VERSION ""

NS_ :

BS_:

BU_: EBOOST_HS CGM_HS BSM_HS HCP_B_HS AVM_HS PFAF_HS LVMPC_HS DCDC_HS TRCM_HS AMP_HS VICM2_HS FICM_HS ARS_HS MCP_B_HS MCP_A_HS ICCM_OBD_HS SAS_HS ACCM_HS VLBS_HS EBCM_OBD_HS HCP_T_HS EDI_HS HPCC_HS VITM_OBD_HS VICM_HS HCP_HS APPS_HS ICCM_HS EOCM_F_HS GPCM_HS VCM_HS HMIM_HS VES_HS Dummy_HS MCP_C_HS ONSTAR_HS EPS_HS TestTool_HS MCP_HS BCP_HS ALC_HS AHL_AFL_HS SADS_HS EPB_HS FCM_HS TCCM_HS RDCM_HS PTO_HS EBCM_HS ACC_HS BCM_HS TCM_HS ECM_HS

BO_ 497 PPEI_Platform_General_Status: 8 BCM_HS
 SG_ ElvtdIdlCstStReq : 33|2@0+ (1,0) [0|3] ""  CGM_HS,ECM_HS
 SG_ FuelFltLfRstRqd : 56|1@0+ (1,0) [0|1] ""  CGM_HS,TCCM_HS,ECM_HS
 SG_ ACCompSysVDA : 9|1@0+ (1,0) [0|1] ""  CGM_HS,HCP_HS,HCP_T_HS,VCM_HS,BCP_HS,ECM_HS
 SG_ BkupPwrModeMstrVDA : 7|1@0+ (1,0) [0|1] ""  EPS_HS,CGM_HS,HCP_T_HS,HCP_HS,HMIM_HS,APPS_HS,EBCM_OBD_HS,EBCM_HS,TCCM_HS,FICM_HS
 SG_ PrkBrkVDA : 35|1@0+ (1,0) [0|1] ""  CGM_HS,RDCM_HS,TCCM_HS
 SG_ PrkBrkVDM : 62|1@0+ (1,0) [0|1] ""  CGM_HS
 SG_ BkupPwrModeMstrVDM : 61|1@0+ (1,0) [0|1] ""  CGM_HS
 SG_ ACCompSysVDM : 60|1@0+ (1,0) [0|1] ""  CGM_HS,VCM_HS
 SG_ AirbgVDA : 57|1@0+ (1,0) [0|1] ""  HCP_B_HS,CGM_HS,HCP_T_HS,HCP_HS,HMIM_HS,ECM_HS,ACC_HS,TCCM_HS,ICCM_OBD_HS,ICCM_HS,BCP_HS
 SG_ SysBkupPwrMdEn : 6|1@0+ (1,0) [0|1] ""  CGM_HS,EBOOST_HS,HCP_B_HS,AVM_HS,PFAF_HS,DCDC_HS,TRCM_HS,FICM_HS,ARS_HS,ICCM_OBD_HS,SAS_HS,VLBS_HS,EBCM_OBD_HS,HCP_T_HS,HCP_HS,ICCM_HS,EOCM_F_HS,VCM_HS,HMIM_HS,VES_HS,MCP_C_HS,EPS_HS,BCP_HS,ALC_HS,AHL_AFL_HS,SADS_HS,FCM_HS,TCCM_HS,RDCM_HS,PTO_HS,EBCM_HS,ACC_HS,TCM_HS,ECM_HS,APPS_HS,EPB_HS
 SG_ SysBkUpPwrMd : 5|2@0+ (1,0) [0|3] ""  CGM_HS,EBOOST_HS,HCP_B_HS,AVM_HS,PFAF_HS,DCDC_HS,TRCM_HS,FICM_HS,ARS_HS,ICCM_OBD_HS,SAS_HS,VLBS_HS,EBCM_OBD_HS,HCP_T_HS,HCP_HS,ICCM_HS,EOCM_F_HS,VCM_HS,HMIM_HS,VES_HS,MCP_C_HS,EPS_HS,BCP_HS,ALC_HS,AHL_AFL_HS,SADS_HS,FCM_HS,TCCM_HS,RDCM_HS,PTO_HS,EBCM_HS,ACC_HS,TCM_HS,ECM_HS,APPS_HS,EPB_HS
 SG_ SysPwrMd : 1|2@0+ (1,0) [0|3] ""  CGM_HS,BSM_HS,VICM2_HS,VICM_HS,EBOOST_HS,HCP_B_HS,AVM_HS,PFAF_HS,DCDC_HS,TRCM_HS,FICM_HS,ARS_HS,ICCM_OBD_HS,SAS_HS,VLBS_HS,HCP_T_HS,HCP_HS,ICCM_HS,EOCM_F_HS,VCM_HS,HMIM_HS,VES_HS,MCP_C_HS,EPS_HS,BCP_HS,ALC_HS,AHL_AFL_HS,SADS_HS,FCM_HS,TCCM_HS,RDCM_HS,PTO_HS,ACC_HS,TCM_HS,ECM_HS,EBCM_OBD_HS,EBCM_HS,APPS_HS,EPB_HS
 SG_ TrStLgMdAtv : 34|1@0+ (1,0) [0|1] ""  EBOOST_HS,BSM_HS,HCP_B_HS,AVM_HS,PFAF_HS,DCDC_HS,TRCM_HS,VICM2_HS,MCP_B_HS,MCP_A_HS,ICCM_OBD_HS,SAS_HS,ACCM_HS,VLBS_HS,VITM_OBD_HS,VICM_HS,ICCM_HS,EOCM_F_HS,VCM_HS,HMIM_HS,VES_HS,MCP_C_HS,EPS_HS,MCP_HS,ALC_HS,AHL_AFL_HS,SADS_HS,EPB_HS,FCM_HS,TCCM_HS,RDCM_HS,PTO_HS,ACC_HS,TCM_HS,ECM_HS,CGM_HS,EBCM_OBD_HS,EBCM_HS
 SG_ DispMeasSys : 59|1@0+ (1,0) [0|1] ""  CGM_HS,TCCM_HS,ACC_HS,ECM_HS
 SG_ ACCmpsrFldOn : 63|1@0+ (1,0) [0|1] ""  CGM_HS,TCCM_HS,ECM_HS
 SG_ ACCompModReq : 12|2@0+ (1,0) [0|3] ""  CGM_HS,HCP_T_HS,HCP_HS,TCCM_HS,ECM_HS
 SG_ ACCompNormLd : 55|8@0+ (0.1,0) [0|25.5] "l/min"  CGM_HS,TCCM_HS,BCP_HS,ECM_HS
 SG_ ACCompNormLdV : 10|1@0+ (1,0) [0|1] ""  CGM_HS,TCCM_HS,BCP_HS,ECM_HS
 SG_ PTORSMstrEngShtReq : 13|1@0+ (1,0) [0|1] ""  CGM_HS,TCCM_HS,PTO_HS,ECM_HS
 SG_ EngOilLfRstRq : 37|1@0+ (1,0) [0|1] ""  CGM_HS,TCCM_HS,ECM_HS
 SG_ SIRDpl : 58|1@0+ (1,0) [0|1] ""  CGM_HS,HCP_T_HS,ICCM_OBD_HS,ICCM_HS,HCP_B_HS,HMIM_HS,HCP_HS,TCCM_HS,BCP_HS,ACC_HS,ECM_HS
 SG_ PTORmStMsEngStRq : 14|1@0+ (1,0) [0|1] ""  CGM_HS,PTO_HS,TCM_HS,TCCM_HS,ECM_HS
 SG_ RmVehStrRq : 15|1@0+ (1,0) [0|1] ""  CGM_HS,HCP_T_HS,BCP_HS,BSM_HS,VICM_HS,HCP_HS,APPS_HS,EPB_HS,TCCM_HS,ECM_HS
 SG_ ThrtlPrgrsnReq : 39|2@0+ (1,0) [0|3] ""  CGM_HS,TCCM_HS,ECM_HS
 SG_ PrkBrkSwAtv : 36|1@0+ (1,0) [0|1] ""  CGM_HS,PTO_HS,ICCM_OBD_HS,ICCM_HS,EOCM_F_HS,RDCM_HS,ACC_HS,EBCM_OBD_HS,EBCM_HS,TCCM_HS,ECM_HS
 SG_ PMMAccTrmSt : 2|1@0+ (1,0) [0|1] ""  CGM_HS,TCM_HS,TCCM_HS,ECM_HS
 SG_ PMMRunCrkTrmSt : 3|1@0+ (1,0) [0|1] ""  CGM_HS,TCM_HS,TCCM_HS,ECM_HS
 SG_ ImmblzrPreRelPswdStat : 8|1@0+ (1,0) [0|1] ""  CGM_HS,HCP_T_HS,HCP_HS,TCCM_HS,ECM_HS
 SG_ ImmblzrPreRelPswrd : 23|16@0+ (1,0) [0|65535] "passwrd"  CGM_HS,HCP_T_HS,HCP_HS,TCCM_HS,ECM_HS

BO_ 969 PPEI_Platform_Immobilizer_Data: 8 BCM_HS
 SG_ ImoInf : 7|64@0+ (1,0) [0|1.84467440737096E+019] ""  HCP_T_HS,HCP_HS,ECM_HS

BO_ 1249 PPEI_VIN_Digits_10_to_17: 8 BCM_HS
 SG_ VehIdNmDig10_17 : 7|64@0+ (1,0) [0|1] ""  HCP_B_HS,CGM_HS,HCP_T_HS,EBCM_OBD_HS,EBCM_HS,VES_HS,EPS_HS,VLBS_HS,BCP_HS,ACC_HS,FICM_HS,EPB_HS,RDCM_HS,TCCM_HS,TCM_HS,ECM_HS

BO_ 2024 USDT_Resp_From_ECM_HS: 8 ECM_HS
 SG_ DgnInf : 7|64@0+ (1,0) [0|1.84467440737096E+019] ""  CGM_HS,ONSTAR_HS,TestTool_HS

BO_ 1512 UUDT_Resp_From_ECM: 8 ECM_HS
 SG_ DgnInf : 7|64@0+ (1,0) [0|1.84467440737096E+019] ""  CGM_HS,ONSTAR_HS,TestTool_HS

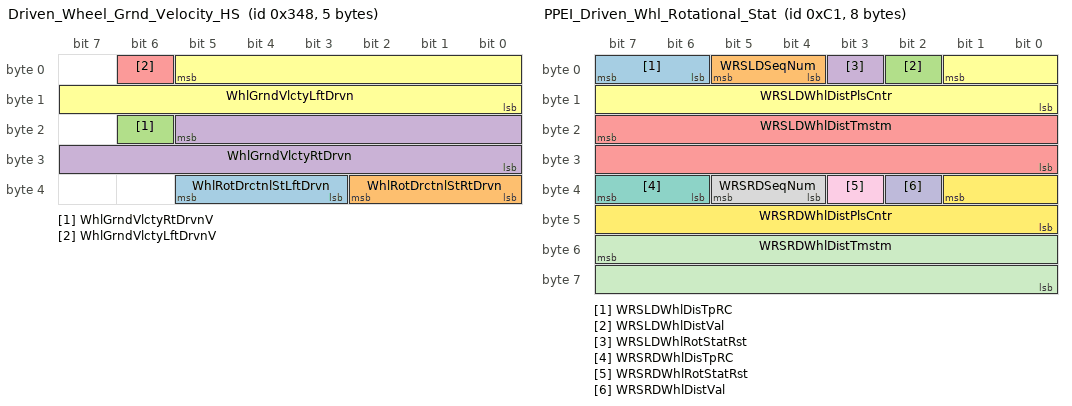
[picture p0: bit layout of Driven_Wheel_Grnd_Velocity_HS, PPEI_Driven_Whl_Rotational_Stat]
BO_ 840 Driven_Wheel_Grnd_Velocity_HS: 5 EBCM_HS
 SG_ WhlRotDrctnlStLftDrvn : 37|3@0+ (1,0) [0|7] ""  CGM_HS,EDI_HS,EOCM_F_HS,HMIM_HS,EPS_HS
 SG_ WhlRotDrctnlStRtDrvn : 34|3@0+ (1,0) [0|7] ""  CGM_HS,EDI_HS,EOCM_F_HS,HMIM_HS,EPS_HS
 SG_ WhlGrndVlctyRtDrvnV : 22|1@0+ (1,0) [0|1] ""  CGM_HS,EDI_HS,HMIM_HS,TCCM_HS,FCM_HS,APPS_HS,EOCM_F_HS,EPB_HS,BCM_HS,RDCM_HS,ACC_HS,VES_HS,EPS_HS,SADS_HS
 SG_ WhlGrndVlctyRtDrvn : 21|14@0+ (0.03125,0) [0|511.96875] "km / h"  CGM_HS,EDI_HS,HMIM_HS,TCCM_HS,FCM_HS,APPS_HS,EOCM_F_HS,BCM_HS,RDCM_HS,ACC_HS,EPB_HS,VES_HS,EPS_HS,SADS_HS
 SG_ WhlGrndVlctyLftDrvnV : 6|1@0+ (1,0) [0|1] ""  CGM_HS,EDI_HS,HMIM_HS,TCCM_HS,FCM_HS,APPS_HS,EOCM_F_HS,EPB_HS,BCM_HS,RDCM_HS,ACC_HS,VES_HS,EPS_HS,SADS_HS
 SG_ WhlGrndVlctyLftDrvn : 5|14@0+ (0.03125,0) [0|511.96875] "km / h"  CGM_HS,EDI_HS,HMIM_HS,TCCM_HS,FCM_HS,APPS_HS,EOCM_F_HS,BCM_HS,RDCM_HS,ACC_HS,EPB_HS,VES_HS,EPS_HS,SADS_HS

BO_ 193 PPEI_Driven_Whl_Rotational_Stat: 8 EBCM_HS
 SG_ WRSLDWhlDisTpRC : 7|2@0+ (1,0) [0|3] "counts"  HCP_B_HS,FCM_HS,HCP_T_HS,FICM_HS,CGM_HS,HCP_HS,ICCM_OBD_HS,ICCM_HS,HMIM_HS,BCP_HS,VES_HS,EPB_HS,EPS_HS,ONSTAR_HS,RDCM_HS,ACC_HS,PTO_HS,BCM_HS,SADS_HS,TCM_HS,TCCM_HS,ECM_HS
 SG_ WRSLDSeqNum : 5|2@0+ (1,0) [0|3] "counts"  HCP_B_HS,FCM_HS,HCP_T_HS,FICM_HS,CGM_HS,HCP_HS,ICCM_OBD_HS,ICCM_HS,HMIM_HS,BCP_HS,VES_HS,EPB_HS,EPS_HS,ONSTAR_HS,RDCM_HS,ACC_HS,PTO_HS,BCM_HS,SADS_HS,TCM_HS,TCCM_HS,ECM_HS
 SG_ WRSLDWhlDistVal : 2|1@0+ (1,0) [0|1] ""  HCP_B_HS,FCM_HS,HCP_T_HS,FICM_HS,CGM_HS,HCP_HS,ICCM_OBD_HS,ICCM_HS,HMIM_HS,BCP_HS,VES_HS,EPB_HS,EPS_HS,ONSTAR_HS,RDCM_HS,ACC_HS,PTO_HS,BCM_HS,SADS_HS,TCM_HS,TCCM_HS,ECM_HS
 SG_ WRSLDWhlRotStatRst : 3|1@0+ (1,0) [0|1] ""  HCP_B_HS,FCM_HS,HCP_T_HS,FICM_HS,CGM_HS,HCP_HS,ICCM_OBD_HS,ICCM_HS,HMIM_HS,BCP_HS,VES_HS,EPB_HS,EPS_HS,ONSTAR_HS,RDCM_HS,ACC_HS,PTO_HS,BCM_HS,SADS_HS,TCM_HS,TCCM_HS,ECM_HS
 SG_ WRSLDWhlDistTmstm : 23|16@0+ (1,0) [0|65535] "counts"  HCP_B_HS,FCM_HS,HCP_T_HS,FICM_HS,CGM_HS,HCP_HS,ICCM_OBD_HS,ICCM_HS,HMIM_HS,BCP_HS,VES_HS,EPB_HS,EPS_HS,ONSTAR_HS,RDCM_HS,ACC_HS,PTO_HS,BCM_HS,SADS_HS,TCM_HS,TCCM_HS,ECM_HS
 SG_ WRSLDWhlDistPlsCntr : 1|10@0+ (1,0) [0|1023] "counts"  HCP_B_HS,FCM_HS,HCP_T_HS,FICM_HS,CGM_HS,HCP_HS,ICCM_OBD_HS,ICCM_HS,HMIM_HS,BCP_HS,VES_HS,EPB_HS,EPS_HS,ONSTAR_HS,RDCM_HS,ACC_HS,PTO_HS,BCM_HS,SADS_HS,TCM_HS,TCCM_HS,ECM_HS
 SG_ WRSRDWhlDisTpRC : 39|2@0+ (1,0) [0|3] "counts"  HCP_B_HS,FCM_HS,HCP_T_HS,FICM_HS,CGM_HS,HCP_HS,ICCM_OBD_HS,ICCM_HS,HMIM_HS,BCP_HS,VES_HS,EPS_HS,ONSTAR_HS,RDCM_HS,ACC_HS,EPB_HS,PTO_HS,BCM_HS,SADS_HS,TCM_HS,TCCM_HS,ECM_HS
 SG_ WRSRDSeqNum : 37|2@0+ (1,0) [0|3] "counts"  HCP_B_HS,FCM_HS,HCP_T_HS,FICM_HS,CGM_HS,HCP_HS,ICCM_OBD_HS,ICCM_HS,HMIM_HS,BCP_HS,VES_HS,EPS_HS,ONSTAR_HS,RDCM_HS,ACC_HS,EPB_HS,PTO_HS,BCM_HS,SADS_HS,TCM_HS,TCCM_HS,ECM_HS
 SG_ WRSRDWhlRotStatRst : 35|1@0+ (1,0) [0|1] ""  HCP_B_HS,FCM_HS,HCP_T_HS,FICM_HS,CGM_HS,HCP_HS,ICCM_OBD_HS,ICCM_HS,HMIM_HS,BCP_HS,VES_HS,EPS_HS,ONSTAR_HS,RDCM_HS,ACC_HS,EPB_HS,PTO_HS,BCM_HS,SADS_HS,TCM_HS,TCCM_HS,ECM_HS
 SG_ WRSRDWhlDistVal : 34|1@0+ (1,0) [0|1] ""  HCP_B_HS,FCM_HS,HCP_T_HS,FICM_HS,CGM_HS,HCP_HS,ICCM_OBD_HS,ICCM_HS,HMIM_HS,BCP_HS,VES_HS,EPS_HS,ONSTAR_HS,RDCM_HS,ACC_HS,EPB_HS,PTO_HS,BCM_HS,SADS_HS,TCM_HS,TCCM_HS,ECM_HS
 SG_ WRSRDWhlDistTmstm : 55|16@0+ (1,0) [0|65535] "counts"  HCP_B_HS,FCM_HS,HCP_T_HS,FICM_HS,CGM_HS,HCP_HS,ICCM_OBD_HS,ICCM_HS,HMIM_HS,BCP_HS,VES_HS,EPS_HS,ONSTAR_HS,RDCM_HS,ACC_HS,EPB_HS,PTO_HS,BCM_HS,SADS_HS,TCM_HS,TCCM_HS,ECM_HS
 SG_ WRSRDWhlDistPlsCntr : 33|10@0+ (1,0) [0|1023] "counts"  HCP_B_HS,FCM_HS,HCP_T_HS,FICM_HS,CGM_HS,HCP_HS,ICCM_OBD_HS,ICCM_HS,HMIM_HS,BCP_HS,VES_HS,EPS_HS,ONSTAR_HS,RDCM_HS,ACC_HS,EPB_HS,PTO_HS,BCM_HS,SADS_HS,TCM_HS,TCCM_HS,ECM_HS

BO_ 481 PPEI_Cruise_Control_Sw_Status: 7 BCM_HS
 SG_ CrsSecSwStatPVal : 51|4@0+ (1,0) [0|15] ""  CGM_HS,ECM_HS,EOCM_F_HS,ACC_HS,PTO_HS
 SG_ CrsSecSwStatARC : 41|2@0+ (1,0) [0|3] ""  CGM_HS,ECM_HS,EOCM_F_HS,ACC_HS,PTO_HS
 SG_ CrsSecSwStat : 27|4@0+ (1,0) [0|15] ""  CGM_HS,ECM_HS,EOCM_F_HS,ACC_HS,PTO_HS
 SG_ DrvSelMdSw3Sta : 37|1@0+ (1,0) [0|1] ""  CGM_HS,ECM_HS
 SG_ DrvSelMdSw2Sta : 38|1@0+ (1,0) [0|1] ""  CGM_HS,ECM_HS
 SG_ AuxHtrRq : 31|1@0+ (1,0) [0|1] ""  CGM_HS,ECM_HS
 SG_ AuxHtrAtv : 30|1@0+ (1,0) [0|1] ""  CGM_HS,ECM_HS
 SG_ DrvSelMdSwStaARC : 33|2@0+ (1,0) [0|3] ""  CGM_HS,ECM_HS
 SG_ DrvSelMdSw1Sta : 39|1@0+ (1,0) [0|1] ""  CGM_HS,ECM_HS
 SG_ CrsSpdLmtrSwStatPVal : 55|4@0+ (1,0) [0|15] ""  CGM_HS,PTO_HS,EOCM_F_HS,ECM_HS,ACC_HS
 SG_ CrsSpdLmtrSwStatARC : 43|2@0+ (1,0) [0|3] ""  CGM_HS,PTO_HS,EOCM_F_HS,ECM_HS,ACC_HS
 SG_ FuelMdSwActV : 29|1@0+ (1,0) [0|1] ""  CGM_HS,FICM_HS,ECM_HS
 SG_ FuelMdSwAct : 28|1@0+ (1,0) [0|1] ""  CGM_HS,FICM_HS,ECM_HS
 SG_ CrsSpdLmtrSwStat : 47|4@0+ (1,0) [0|15] ""  CGM_HS,PTO_HS,EOCM_F_HS,ECM_HS,ACC_HS
 SG_ AdptCrsGapSwAct : 23|2@0+ (1,0) [0|3] ""  CGM_HS,EOCM_F_HS,ACC_HS
 SG_ CrsCntrlSwStCanSwAct : 7|1@0+ (1,0) [0|1] ""  CGM_HS,EOCM_F_HS,ACC_HS,ECM_HS
 SG_ CrsCntrlSwStSwDataIntgty : 1|2@0+ (1,0) [0|3] ""  CGM_HS,EOCM_F_HS,ACC_HS,ECM_HS
 SG_ CrsCntrlSwStSpdInSwAct : 3|1@0+ (1,0) [0|1] ""  CGM_HS,EOCM_F_HS,ACC_HS,ECM_HS
 SG_ CrsCntrlSwStSpDcSwAct : 2|1@0+ (1,0) [0|1] ""  CGM_HS,EOCM_F_HS,ACC_HS,ECM_HS
 SG_ CrsCntrlSwStSetSwAct : 4|1@0+ (1,0) [0|1] ""  CGM_HS,EOCM_F_HS,ACC_HS,ECM_HS
 SG_ CrsCntrlSwStResSwAct : 5|1@0+ (1,0) [0|1] ""  CGM_HS,EOCM_F_HS,ACC_HS,ECM_HS
 SG_ CrsCntrlSwStOnSwAct : 6|1@0+ (1,0) [0|1] ""  CGM_HS,EOCM_F_HS,ACC_HS,ECM_HS
 SG_ CrsCntrlSwStatProtValue : 15|8@0+ (1,0) [0|255] ""  CGM_HS,EOCM_F_HS,ACC_HS,ECM_HS
 SG_ CrsCntrlSwStAlvRollCnt : 17|2@0+ (1,0) [0|3] ""  CGM_HS,EOCM_F_HS,ACC_HS,ECM_HS
 SG_ CrsCntCncRq : 18|1@0+ (1,0) [0|1] ""  CGM_HS,ECM_HS

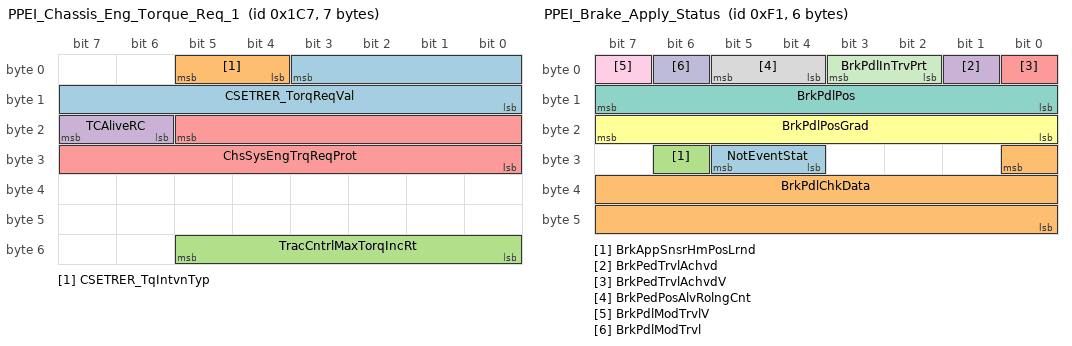
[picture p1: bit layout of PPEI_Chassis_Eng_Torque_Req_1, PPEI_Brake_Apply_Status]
BO_ 455 PPEI_Chassis_Eng_Torque_Req_1: 7 EBCM_HS
 SG_ CSETRER_TorqReqVal : 3|12@0+ (0.5,-848) [-848|1199.5] "Nm"  CGM_HS,ICCM_OBD_HS,ICCM_HS,EOCM_F_HS,ACC_HS,ECM_HS
 SG_ CSETRER_TqIntvnTyp : 5|2@0+ (1,0) [0|3] ""  CGM_HS,ICCM_OBD_HS,ICCM_HS,EOCM_F_HS,ACC_HS,ECM_HS
 SG_ TracCntrlMaxTorqIncRt : 53|6@0+ (16,0) [0|1008] "Nm/s"  CGM_HS,ECM_HS
 SG_ TCAliveRC : 23|2@0+ (1,0) [0|3] ""  CGM_HS,ECM_HS
 SG_ ChsSysEngTrqReqProt : 21|14@0+ (1,0) [0|16383] ""  CGM_HS,ECM_HS

BO_ 761 PPEI_Chassis_General_Status_2: 7 EBCM_HS
 SG_ BrkSysHRBkCtrlAvail : 24|1@0+ (1,0) [0|1] ""  CGM_HS,TCM_HS
 SG_ BrkSysHRBkCtrlStat : 26|2@0+ (1,0) [0|3] ""  CGM_HS,TCM_HS
 SG_ BrkSysHSAAval : 27|1@0+ (1,0) [0|1] ""  CGM_HS,TCM_HS
 SG_ BrkSysHSAStat : 30|3@0+ (1,0) [0|7] ""  CGM_HS,TCM_HS
 SG_ HillDscntCtrlStatPVal : 17|2@0+ (1,0) [0|3] ""  CGM_HS,ECM_HS
 SG_ HillDscntCtrlStatARC : 19|2@0+ (1,0) [0|3] ""  CGM_HS,ECM_HS
 SG_ HillDscntCtrlStat : 21|2@0+ (1,0) [0|3] ""  CGM_HS,ECM_HS
 SG_ AutoBrkFeatInhbtPVal : 49|2@0+ (1,0) [0|3] ""  CGM_HS,FCM_HS,ECM_HS
 SG_ AutoBrkFeatInhbtARC : 51|2@0+ (1,0) [0|3] ""  CGM_HS,FCM_HS,ECM_HS
 SG_ ABFI_CollPrepSysInhbt : 52|1@0+ (1,0) [0|1] ""  CGM_HS,FCM_HS,ECM_HS
 SG_ ABFI_RrVirtlBmprInh : 53|1@0+ (1,0) [0|1] ""  CGM_HS,FCM_HS,ECM_HS
 SG_ BrkPdlDrvApplPresV : 12|1@0+ (1,0) [0|1] ""  CGM_HS,ICCM_OBD_HS,ICCM_HS,BCP_HS,FCM_HS,ECM_HS,TCCM_HS,TCM_HS,VES_HS,EPS_HS
 SG_ BrkPdlDrvApplPres : 47|8@0+ (75,0) [0|19125] "kPa"  HCP_B_HS,CGM_HS,ICCM_OBD_HS,ICCM_HS,BCP_HS,FCM_HS,ECM_HS,TCCM_HS,TCM_HS,VES_HS,EPS_HS
 SG_ AutoBrkPTReqStat : 15|3@0+ (1,0) [0|7] ""  CGM_HS,FCM_HS,ECM_HS
 SG_ WhlSpdSnsgDTCIndex : 7|5@0+ (1,0) [0|31] ""  CGM_HS,ECM_HS
 SG_ WhlSpdSnsgDTCStat : 2|3@0+ (1,0) [0|7] ""  CGM_HS,ECM_HS
 SG_ SprTireSt : 10|3@0+ (1,0) [0|7] ""  CGM_HS,ICCM_OBD_HS,ICCM_HS,VES_HS,EPS_HS,BCM_HS,RDCM_HS,TCCM_HS

BO_ 489 PPEI_Chassis_General_Status_1: 8 EBCM_HS
 SG_ EnhDrvMdSwChUseRq : 53|1@0+ (1,0) [0|1] ""  CGM_HS,ECM_HS
 SG_ IMUDataMsk : 25|1@0+ (1,0) [0|1] ""  CGM_HS,ONSTAR_HS
 SG_ DrvIndpntBrkAppAct : 55|1@0+ (1,0) [0|1] ""  CGM_HS,RDCM_HS,TCM_HS,ECM_HS
 SG_ WhlSlpSt : 52|2@0+ (1,0) [0|3] ""  HCP_HS,CGM_HS,HCP_T_HS,ECM_HS,TCM_HS
 SG_ BSTGRReqdGear : 19|4@0+ (1,0) [0|15] ""  CGM_HS,TCM_HS
 SG_ BSTGRReqType : 21|2@0+ (1,0) [0|3] ""  CGM_HS,TCM_HS
 SG_ VehDynOvrUndrStr : 49|10@0- (0.5,0) [-256|255.5] "%"  CGM_HS,EPS_HS,RDCM_HS,TCCM_HS
 SG_ VSELatAccV : 4|1@0+ (1,0) [0|1] ""  CGM_HS,EDI_HS,FCM_HS,EPS_HS,ICCM_OBD_HS,ICCM_HS,ALC_HS,SADS_HS,RDCM_HS,BCM_HS,ACC_HS,EPB_HS,TCM_HS,TCCM_HS,ECM_HS
 SG_ VSELatAcc : 3|12@0- (0.015625,0) [-32|31.984375] "m/s^2"  CGM_HS,EDI_HS,FCM_HS,EPS_HS,ICCM_OBD_HS,ICCM_HS,ALC_HS,SADS_HS,BCM_HS,RDCM_HS,ACC_HS,EPB_HS,TCM_HS,TCCM_HS,ECM_HS
 SG_ VSEAct : 24|1@0+ (1,0) [0|1] ""  CGM_HS,ICCM_OBD_HS,ICCM_HS,EOCM_F_HS,VES_HS,BCM_HS,EPB_HS,RDCM_HS,EPS_HS,ACC_HS,LVMPC_HS,TCCM_HS,ECM_HS
 SG_ VhDynCntlSysSt : 39|3@0+ (1,0) [0|7] ""  CGM_HS,EOCM_F_HS,FCM_HS,HMIM_HS,RDCM_HS,VES_HS,ECM_HS,EPB_HS,EPS_HS,ACC_HS,TCCM_HS
 SG_ VehDynYawRateV : 36|1@0+ (1,0) [0|1] ""  CGM_HS,ICCM_OBD_HS,ICCM_HS,EDI_HS,FCM_HS,HMIM_HS,RDCM_HS,BCM_HS,VES_HS,EPS_HS,ONSTAR_HS,AHL_AFL_HS,ACC_HS,TCCM_HS
 SG_ VehDynYawRate : 35|12@0- (0.0625,0) [-128|127.9375] "deg/sec"  CGM_HS,ICCM_OBD_HS,ICCM_HS,EDI_HS,FCM_HS,HMIM_HS,RDCM_HS,BCM_HS,VES_HS,EPS_HS,AHL_AFL_HS,ONSTAR_HS,ACC_HS,TCCM_HS
 SG_ TrnsBrkSysCltchRelRqd : 5|1@0+ (1,0) [0|1] ""  CGM_HS,TCCM_HS,TCM_HS
 SG_ TracCntrlSysDrIntnt : 26|1@0+ (1,0) [0|1] ""  CGM_HS,EPS_HS,RDCM_HS,ECM_HS
 SG_ VehDynOvrUndrStrV : 50|1@0+ (1,0) [0|1] ""  CGM_HS,EPS_HS,RDCM_HS,TCCM_HS
 SG_ TCSysEnbld : 27|1@0+ (1,0) [0|1] ""  CGM_HS,EOCM_F_HS,ACC_HS,BCP_HS,VES_HS,EPS_HS,RDCM_HS,TCM_HS,ECM_HS
 SG_ TCSysAtv : 28|1@0+ (1,0) [0|1] ""  CGM_HS,LVMPC_HS,EDI_HS,PTO_HS,TCCM_HS,EOCM_F_HS,VES_HS,RDCM_HS,EPB_HS,EPS_HS,ACC_HS,BCM_HS,TCM_HS,ECM_HS
 SG_ BrkPdlDrvAppPrsDetcdV : 7|1@0+ (1,0) [0|1] ""  CGM_HS,EOCM_F_HS,ACC_HS,VES_HS,EPS_HS,RDCM_HS,TCM_HS,TCCM_HS,ECM_HS
 SG_ BrkPdlDrvAppPrsDetcd : 6|1@0+ (1,0) [0|1] ""  CGM_HS,EOCM_F_HS,ACC_HS,VES_HS,EPS_HS,RDCM_HS,TCM_HS,TCCM_HS,ECM_HS
 SG_ ACCBrkngAct : 31|1@0+ (1,0) [0|1] ""  CGM_HS,EOCM_F_HS,ACC_HS,TCM_HS,ECM_HS
 SG_ ABSFld : 29|1@0+ (1,0) [0|1] ""  CGM_HS,FCM_HS,EOCM_F_HS,ACC_HS,ICCM_OBD_HS,ICCM_HS,VES_HS,EPS_HS,EPB_HS,TCM_HS,ECM_HS
 SG_ ABSAtv : 30|1@0+ (1,0) [0|1] ""  CGM_HS,LVMPC_HS,EDI_HS,ICCM_OBD_HS,ICCM_HS,EOCM_F_HS,APPS_HS,SADS_HS,VES_HS,RDCM_HS,EPB_HS,EPS_HS,ACC_HS,BCM_HS,TCM_HS,TCCM_HS,ECM_HS

BO_ 381 Antilock_Brake_and_TC_Status_HS: 6 EBCM_HS
 SG_ HillDesCtrlRedVehSpIO : 39|1@0+ (1,0) [0|1] ""  CGM_HS,BCM_HS
 SG_ EBDFailed : 23|1@0+ (1,0) [0|1] ""  CGM_HS,BCM_HS
 SG_ StWhAnVDA : 17|1@0+ (1,0) [0|1] ""  CGM_HS,HMIM_HS,RDCM_HS,ONSTAR_HS,ACC_HS,AHL_AFL_HS,EPB_HS,BCM_HS
 SG_ TirePrsLowIO : 9|1@0+ (1,0) [0|1] ""  CGM_HS,BCM_HS
 SG_ VaccBoostFailure : 16|1@0+ (1,0) [0|1] ""  CGM_HS,BCM_HS
 SG_ VSESysPrs : 1|1@0+ (1,0) [0|1] ""  CGM_HS,EPB_HS,BCM_HS
 SG_ HalfSysFail : 18|1@0+ (1,0) [0|1] ""  CGM_HS,BCM_HS
 SG_ ActVehAccel : 35|12@0- (0.01,0) [-20.48|20.47] "m/s^2"  ECM_HS,CGM_HS,BSM_HS,VICM_HS,BCP_HS,BCM_HS,EOCM_F_HS,FCM_HS,ACC_HS,AHL_AFL_HS,EPB_HS
 SG_ ActVehAccelV : 20|1@0+ (1,0) [0|1] ""  ECM_HS,CGM_HS,BSM_HS,VICM_HS,BCP_HS,BCM_HS,EOCM_F_HS,FCM_HS,ACC_HS,AHL_AFL_HS,EPB_HS
 SG_ BksOvht : 8|1@0+ (1,0) [0|1] ""  CGM_HS,EOCM_F_HS,BCM_HS,ACC_HS
 SG_ TCSysPr : 10|1@0+ (1,0) [0|1] ""  CGM_HS,EPB_HS,BCM_HS
 SG_ ABSPr : 22|1@0+ (1,0) [0|1] ""  CGM_HS,BCP_HS,APPS_HS,BCM_HS,EPB_HS
 SG_ TreInfMonSysRstPrfmd : 11|1@0+ (1,0) [0|1] ""  CGM_HS,BCM_HS
 SG_ ABSIO : 12|1@0+ (1,0) [0|1] ""  CGM_HS,FCM_HS,EOCM_F_HS,BCM_HS
 SG_ BrkPadWrnIO : 0|1@0+ (1,0) [0|1] ""  CGM_HS,BCM_HS
 SG_ VehStabEnhmntMd : 15|3@0+ (1,0) [0|7] ""  CGM_HS,EDI_HS,ICCM_OBD_HS,ICCM_HS,SADS_HS,ACC_HS,EOCM_F_HS,TCCM_HS,RDCM_HS,BCM_HS
 SG_ VehStabEnhmntStat : 4|3@0+ (1,0) [0|7] ""  CGM_HS,EPS_HS,EDI_HS,FCM_HS,ONSTAR_HS,ACC_HS,EOCM_F_HS,BCM_HS,EPB_HS
 SG_ TCSysOpMd : 7|3@0+ (1,0) [0|7] ""  CGM_HS,EDI_HS,SADS_HS,EPS_HS,ACC_HS,EOCM_F_HS,TCCM_HS,RDCM_HS,BCM_HS
 SG_ TCSysOpStat : 38|3@0+ (1,0) [0|7] ""  CGM_HS,EDI_HS,SADS_HS,ONSTAR_HS,ACC_HS,EOCM_F_HS,EPB_HS,BCM_HS
 SG_ BrkSysVTopSpdLimVal : 31|8@0+ (2,0) [0|510] "km / h"  CGM_HS,BCM_HS
 SG_ BrkSysRedBrkTlltlReq : 19|1@0+ (1,0) [0|1] ""  CGM_HS,ONSTAR_HS,BCM_HS
 SG_ BrkSysBrkLtsReqd : 21|1@0+ (1,0) [0|1] ""  CGM_HS,AHL_AFL_HS,BCM_HS

BO_ 241 PPEI_Brake_Apply_Status: 6 BCM_HS
 SG_ NotEventStat : 29|2@0+ (1,0) [0|3] ""  CGM_HS,EBCM_OBD_HS,EBCM_HS,ECM_HS,VES_HS,EPS_HS
 SG_ BrkPdlChkData : 24|17@0+ (1,0) [0|131071] ""  FCM_HS,CGM_HS,EOCM_F_HS,ACC_HS
 SG_ BrkAppSnsrHmPosLrnd : 30|1@0+ (1,0) [0|1] ""  CGM_HS,EOCM_F_HS,FCM_HS,ACC_HS,ECM_HS,VES_HS,EPS_HS,EBCM_OBD_HS,EBCM_HS
 SG_ BrkPedTrvlAchvd : 1|1@0+ (1,0) [0|1] ""  HCP_B_HS,CGM_HS,HCP_T_HS,PTO_HS,BSM_HS,VICM_HS,BCP_HS,APPS_HS,VES_HS,EPS_HS,EOCM_F_HS,ICCM_OBD_HS,ICCM_HS,ALC_HS,EPB_HS,ACC_HS,RDCM_HS,SADS_HS,EBCM_OBD_HS,EBCM_HS,TCM_HS,TCCM_HS,ECM_HS
 SG_ BrkPedTrvlAchvdV : 0|1@0+ (1,0) [0|1] ""  HCP_B_HS,CGM_HS,HCP_T_HS,PTO_HS,BSM_HS,VICM_HS,BCP_HS,APPS_HS,VES_HS,EPS_HS,EOCM_F_HS,ICCM_OBD_HS,ICCM_HS,ALC_HS,EPB_HS,ACC_HS,RDCM_HS,SADS_HS,EBCM_OBD_HS,EBCM_HS,TCM_HS,TCCM_HS,ECM_HS
 SG_ BrkPdlPosGrad : 23|8@0- (40,0) [-5120|5080] "%/s"  FCM_HS,CGM_HS,ACC_HS,VES_HS,EPS_HS,EOCM_F_HS,SADS_HS,EBCM_OBD_HS,EBCM_HS
 SG_ BrkPdlPos : 15|8@0+ (0.392157,0) [0|100.000035] "% full"  FCM_HS,ECM_HS,CGM_HS,LVMPC_HS,TCCM_HS,ACC_HS,EOCM_F_HS,TCM_HS,EDI_HS,SADS_HS,VES_HS,EPS_HS,EPB_HS,EBCM_OBD_HS,EBCM_HS
 SG_ BrkPedPosAlvRolngCnt : 5|2@0+ (1,0) [0|3] ""  FCM_HS,CGM_HS,PTO_HS,TCCM_HS,RDCM_HS,VES_HS,EPS_HS,EOCM_F_HS,ICCM_OBD_HS,ICCM_HS,EPB_HS,ACC_HS,EBCM_OBD_HS,EBCM_HS,TCM_HS,ECM_HS
 SG_ BrkPdlModTrvlV : 7|1@0+ (1,0) [0|1] ""  CGM_HS,SADS_HS,EBCM_OBD_HS,EBCM_HS,ACC_HS,EOCM_F_HS,EPB_HS,TCCM_HS,VES_HS,EPS_HS,TCM_HS,ECM_HS
 SG_ BrkPdlModTrvl : 6|1@0+ (1,0) [0|1] ""  CGM_HS,EBCM_OBD_HS,EBCM_HS,SADS_HS,ACC_HS,EOCM_F_HS,EPB_HS,TCCM_HS,VES_HS,EPS_HS,TCM_HS,ECM_HS
 SG_ BrkPdlInTrvPrt : 3|2@0+ (1,0) [0|3] ""  CGM_HS,PTO_HS,EOCM_F_HS,ICCM_OBD_HS,ICCM_HS,ALC_HS,RDCM_HS,ACC_HS,VES_HS,EPS_HS,SADS_HS,EBCM_OBD_HS,EBCM_HS,EPB_HS,TCM_HS,TCCM_HS,ECM_HS

BO_ 2025 USDT_Resp_From_BCP_HS: 8 BCP_HS
 SG_ DgnInf : 7|64@0+ (1,0) [0|1.84467440737096E+019] ""  CGM_HS,ONSTAR_HS,TestTool_HS

BO_ 2029 USDT_Resp_From_OBD_Device5: 8 EBCM_OBD_HS
 SG_ DgnInf : 7|64@0+ (1,0) [0|1.84467440737096E+019] ""  CGM_HS,ONSTAR_HS,TestTool_HS

BO_ 2031 USDT_Resp_From_VITM_HS: 8 VITM_OBD_HS
 SG_ DgnInf : 7|64@0+ (1,0) [0|1.84467440737096E+019] ""  CGM_HS,ONSTAR_HS,TestTool_HS

BO_ 1513 UUDT_Resp_From_BCP_HS: 8 BCP_HS
 SG_ DgnInf : 7|64@0+ (1,0) [0|1.84467440737096E+019] ""  CGM_HS,ONSTAR_HS,TestTool_HS

BO_ 1517 UUDT_Resp_From_OBD_Device5: 8 EBCM_OBD_HS
 SG_ DgnInf : 7|64@0+ (1,0) [0|1.84467440737096E+019] ""  CGM_HS,ONSTAR_HS,TestTool_HS

BO_ 1519 UUDT_Resp_From_VITM_HS: 8 VITM_OBD_HS
 SG_ DgnInf : 7|64@0+ (1,0) [0|1.84467440737096E+019] ""  CGM_HS,ONSTAR_HS,TestTool_HS

BO_ 2030 USDT_Resp_From_OBD_Device6: 8 GPCM_HS
 SG_ DgnInf : 7|64@0+ (1,0) [0|1.84467440737096E+019] ""  CGM_HS,ONSTAR_HS,TestTool_HS

BO_ 1518 UUDT_Resp_From_OBD_Device6: 8 GPCM_HS
 SG_ DgnInf : 7|64@0+ (1,0) [0|1.84467440737096E+019] ""  CGM_HS,ONSTAR_HS,TestTool_HS

BO_ 1346 UUDT_Resp_From_EHPS_EPS_HS: 8 EPS_HS
 SG_ DgnInf_HS542 : 7|64@0+ (1,0) [0|1.84467440737096E+019] ""  CGM_HS,ONSTAR_HS,TestTool_HS

BO_ 1353 UUDT_Resp_From_AHL_AFL_HS: 8 CGM_HS
 SG_ DgnInf_HS549 : 7|64@0+ (1,0) [0|1.84467440737096E+019] ""  CGM_HS,ONSTAR_HS,TestTool_HS

BO_ 1609 USDT_Resp_From_AHL_AFL_HS: 8 AHL_AFL_HS
 SG_ DgnInf : 7|64@0+ (1,0) [0|1.84467440737096E+019] ""  CGM_HS,ONSTAR_HS,TestTool_HS

BO_ 1602 USDT_Resp_From_EHPS_EPS_HS: 8 EPS_HS
 SG_ DgnInf : 7|64@0+ (1,0) [0|1.84467440737096E+019] ""  CGM_HS,ONSTAR_HS,TestTool_HS

BO_ 2027 USDT_Resp_From_ICCM_OBD_HS: 8 ICCM_HS
 SG_ DgnInf : 7|64@0+ (1,0) [0|1.84467440737096E+019] ""  CGM_HS,ONSTAR_HS,TestTool_HS

BO_ 1515 UUDT_Resp_From_ICCM_OBD_HS: 8 ICCM_HS
 SG_ DgnInf : 7|64@0+ (1,0) [0|1.84467440737096E+019] ""  CGM_HS,ONSTAR_HS,TestTool_HS

BO_ 1614 USDT_Resp_From_SADS_HS: 8 SADS_HS
 SG_ DgnInf : 7|64@0+ (1,0) [0|1.84467440737096E+019] ""  CGM_HS,ONSTAR_HS,TestTool_HS

BO_ 1348 UUDT_Resp_From_OBCM_HS: 8 DCDC_HS
 SG_ DgnInf_HS544 : 7|64@0+ (1,0) [0|1.84467440737096E+019] ""  CGM_HS,ONSTAR_HS,TestTool_HS

BO_ 1349 UUDT_Resp_From_ALC_HS: 8 ALC_HS
 SG_ DgnInf_HS545 : 7|64@0+ (1,0) [0|1.84467440737096E+019] ""  CGM_HS,ONSTAR_HS,TestTool_HS

BO_ 1352 UUDT_Resp_From_Free_48_HS: 8 Dummy_HS
 SG_ DgnInf_HS548 : 7|64@0+ (1,0) [0|1.84467440737096E+019] ""  CGM_HS,ONSTAR_HS,TestTool_HS

BO_ 1354 UUDT_Resp_From_SAS_HS: 8 SAS_HS
 SG_ DgnInf_HS54A : 7|64@0+ (1,0) [0|1.84467440737096E+019] ""  CGM_HS,ONSTAR_HS,TestTool_HS

BO_ 1605 USDT_Resp_From_ALC_HS: 8 ALC_HS
 SG_ DgnInf : 7|64@0+ (1,0) [0|1.84467440737096E+019] ""  CGM_HS,ONSTAR_HS,TestTool_HS

BO_ 1620 USDT_Resp_From_EPB_HS: 8 EPB_HS
 SG_ DgnInf : 7|64@0+ (1,0) [0|1.84467440737096E+019] ""  CGM_HS,ONSTAR_HS,TestTool_HS

BO_ 1604 USDT_Resp_From_OBCM_HS: 8 DCDC_HS
 SG_ DgnInf : 7|64@0+ (1,0) [0|1.84467440737096E+019] ""  CGM_HS,ONSTAR_HS,TestTool_HS

BO_ 1612 USDT_Resp_From_PFAF_HS: 8 PFAF_HS
 SG_ DgnInf : 7|64@0+ (1,0) [0|1.84467440737096E+019] ""  CGM_HS,ONSTAR_HS,TestTool_HS

BO_ 1615 USDT_Resp_From_RDCM_HS: 8 RDCM_HS
 SG_ DgnInf : 7|64@0+ (1,0) [0|1.84467440737096E+019] ""  CGM_HS,ONSTAR_HS,TestTool_HS

BO_TX_BU_ 840 : EBCM_OBD_HS,EBCM_HS;
BO_TX_BU_ 193 : EBCM_OBD_HS,EBCM_HS;
BO_TX_BU_ 455 : EBCM_OBD_HS,EBCM_HS;
BO_TX_BU_ 761 : EBCM_OBD_HS,EBCM_HS;
BO_TX_BU_ 489 : EBCM_OBD_HS,EBCM_HS;
BO_TX_BU_ 381 : EBCM_OBD_HS,EBCM_HS;
BO_TX_BU_ 2025 : HCP_B_HS,HCP_T_HS,HCP_HS,BCP_HS;
BO_TX_BU_ 1513 : HCP_B_HS,HCP_T_HS,HCP_HS,BCP_HS;
BO_TX_BU_ 2030 : EBOOST_HS,VICM2_HS,FICM_HS,GPCM_HS;
BO_TX_BU_ 1518 : EBOOST_HS,VICM2_HS,FICM_HS,GPCM_HS;
BO_TX_BU_ 1346 : VES_HS,EPS_HS;
BO_TX_BU_ 1353 : CGM_HS,AHL_AFL_HS;
BO_TX_BU_ 1609 : CGM_HS,AHL_AFL_HS;
BO_TX_BU_ 1602 : VES_HS,EPS_HS;
BO_TX_BU_ 2027 : ICCM_OBD_HS,ICCM_HS;
BO_TX_BU_ 1515 : ICCM_OBD_HS,ICCM_HS;
BO_TX_BU_ 1620 : CGM_HS,EPB_HS;
BO_TX_BU_ 1612 : CGM_HS,PFAF_HS;
CM_ SG_ 1249 VehIdNmDig10_17 "Desc: 8 ASCII Characters";
CM_ SG_ 481 AuxHtrRq "Auxiliary Heater shall be used to denote a heater function that uses some kind of power, electrical or mechanical,  that was generated by the engine.";
CM_ SG_ 481 AuxHtrAtv "Auxiliary Heater shall be used to denote a heater function that uses some kind of power, electrical or mechanical,  that was generated by the engine.";
CM_ BO_ 489 "Changed for PPEI 3.6";
CM_ SG_ 381 BrkSysRedBrkTlltlReq "Added acc to Björn 0410";
CM_ SG_ 241 BrkPdlModTrvlV "Indicates that the brake pedal position has passed a threshold for brake torque management and some 2 channel Vehicle Dynamics Control systems.";
CM_ SG_ 241 BrkPdlModTrvl "Indicates that the brake pedal position has passed a threshold for brake torque management and some 2 channel Vehicle Dynamics Control systems.";
BA_DEF_ SG_  "VNSigSLHS_VNReq" ENUM  "No","Yes";
BA_DEF_ SG_  "VNSigSLHSSharedDiagnostic" ENUM  "No","Yes";
BA_DEF_ SG_  "SignalType" STRING ;
BA_DEF_ SG_  "PacketOrder" INT 0 65535;
BA_DEF_ SG_  "SignalLongName" STRING ;
BA_DEF_ SG_  "GenSigStartValue" INT 0 65535;
BA_DEF_ SG_  "VNSigAllNodes" ENUM  "No","Yes";
BA_DEF_ SG_  "GenSigDeltaValue" INT 0 0;
BA_DEF_ SG_  "GenSigSendType" ENUM  "not used","not used","not used","not used","not used","not used","not used","NoSigSendType","not used","not used","OnAnyChange","OnChangeIfActive","OnDelta";
BA_DEF_ SG_  "GenSigSendOnInit" ENUM  "Not Initialized","Application","Handler";
BA_DEF_ BO_  "AppGenMsgCycleTime" INT 0 0;
BA_DEF_ BO_  "TpTxIndex" INT 0 99;
BA_DEF_ BO_  "GenMsgILSupport" ENUM  "No","Yes";
BA_DEF_ BO_  "TpApplType" STRING ;
BA_DEF_ BO_  "Prio" INT 0 7;
BA_DEF_ BO_  "MessageSubnet" ENUM  "LS","MS","HS","CE","PE","HV","FO","S1","HE","LE","HE2";
BA_DEF_ BO_  "DiagState" ENUM  "No","Yes";
BA_DEF_ BO_  "GenMsgStartDelayTime" INT 0 100000;
BA_DEF_ BO_  "GenMsgDelayTime" INT 0 100000;
BA_DEF_ BO_  "GenMsgCycleTime" INT 0 100000;
BA_DEF_ BO_  "GenMsgSendType" ENUM  "cyclicX","spontanX","cyclicIfActiveX","spontanWithDelay","cyclicAndSpontanX","cyclicAndSpontanWithDelay","spontanWithRepitition","cyclicIfActiveAndSpontanWD";
BA_DEF_ BO_  "DiagResponse" ENUM  "No","Yes";
BA_DEF_ BO_  "DiagRequest" ENUM  "No","Yes";
BA_DEF_ BO_  "NmMessage" ENUM  "No","Yes";
BA_DEF_REL_ BU_SG_REL_  "GenSigSuprvRespComment" STRING ;
BA_DEF_REL_ BU_SG_REL_  "GenSigVBitResp" ENUM  "No","Yes";
BA_DEF_REL_ BU_SG_REL_  "GenSigVBitRespComment" STRING ;
BA_DEF_REL_ BU_SG_REL_  "GenSigVDAFailComment" STRING ;
BA_DEF_REL_ BU_SG_REL_  "GenSigVDAFailResp" ENUM  "No","Yes";
BA_DEF_REL_ BU_SG_REL_  "GenSigRxStartValue" STRING ;
BA_DEF_REL_ BU_SG_REL_  "GenSigSuprvRespSubValue" INT 0 65535;
BA_DEF_REL_ BU_SG_REL_  "GenSigSuprvResp" ENUM  "None","Notify App","Substitute Default";
BA_DEF_REL_ BU_SG_REL_  "GenSigTimeoutMsg" HEX -2147483648 268435455;
BA_DEF_REL_ BU_SG_REL_  "GenSigTimeoutTime" INT 0 15000;
BA_DEF_DEF_  "VNSigSLHS_VNReq" "No";
BA_DEF_DEF_  "VNSigSLHSSharedDiagnostic" "No";
BA_DEF_DEF_  "SignalType" "";
BA_DEF_DEF_  "PacketOrder" 0;
BA_DEF_DEF_  "SignalLongName" "";
BA_DEF_DEF_  "GenSigStartValue" 0;
BA_DEF_DEF_  "VNSigAllNodes" "No";
BA_DEF_DEF_  "GenSigDeltaValue" 0;
BA_DEF_DEF_  "GenSigSendType" "NoSigSendType";
BA_DEF_DEF_  "GenSigSendOnInit" "Not Initialized";
BA_DEF_DEF_  "AppGenMsgCycleTime" 0;
BA_DEF_DEF_  "TpTxIndex" 0;
BA_DEF_DEF_  "GenMsgILSupport" "Yes";
BA_DEF_DEF_  "TpApplType" "";
BA_DEF_DEF_  "Prio" 4;
BA_DEF_DEF_  "MessageSubnet" "FO";
BA_DEF_DEF_  "DiagState" "No";
BA_DEF_DEF_  "GenMsgStartDelayTime" 0;
BA_DEF_DEF_  "GenMsgDelayTime" 0;
BA_DEF_DEF_  "GenMsgCycleTime" 0;
BA_DEF_DEF_  "GenMsgSendType" "spontanX";
BA_DEF_DEF_  "DiagResponse" "No";
BA_DEF_DEF_  "DiagRequest" "No";
BA_DEF_DEF_  "NmMessage" "No";
BA_DEF_DEF_REL_ "GenSigSuprvRespComment" "";
BA_DEF_DEF_REL_ "GenSigVBitResp" "No";
BA_DEF_DEF_REL_ "GenSigVBitRespComment" "";
BA_DEF_DEF_REL_ "GenSigVDAFailComment" "";
BA_DEF_DEF_REL_ "GenSigVDAFailResp" "No";
BA_DEF_DEF_REL_ "GenSigRxStartValue" "";
BA_DEF_DEF_REL_ "GenSigSuprvRespSubValue" 0;
BA_DEF_DEF_REL_ "GenSigSuprvResp" "None";
BA_DEF_DEF_REL_ "GenSigTimeoutMsg" 0;
BA_DEF_DEF_REL_ "GenSigTimeoutTime" 0;
BA_ "Prio" BO_ 497 0;
BA_ "MessageSubnet" BO_ 497 2;
BA_ "GenMsgStartDelayTime" BO_ 497 10;
BA_ "GenMsgDelayTime" BO_ 497 30;
BA_ "GenMsgCycleTime" BO_ 497 100;
BA_ "GenMsgSendType" BO_ 497 0;
BA_ "Prio" BO_ 969 0;
BA_ "MessageSubnet" BO_ 969 2;
BA_ "GenMsgStartDelayTime" BO_ 969 20;
BA_ "GenMsgCycleTime" BO_ 969 100;
BA_ "GenMsgSendType" BO_ 969 0;
BA_ "Prio" BO_ 1249 0;
BA_ "MessageSubnet" BO_ 1249 2;
BA_ "GenMsgStartDelayTime" BO_ 1249 60;
BA_ "GenMsgCycleTime" BO_ 1249 1000;
BA_ "GenMsgSendType" BO_ 1249 0;
BA_ "Prio" BO_ 2024 0;
BA_ "MessageSubnet" BO_ 2024 2;
BA_ "DiagResponse" BO_ 2024 1;
BA_ "GenMsgILSupport" BO_ 1512 0;
BA_ "TpApplType" BO_ 1512 "DiagUUDTResponse";
BA_ "Prio" BO_ 1512 0;
BA_ "MessageSubnet" BO_ 1512 2;
BA_ "Prio" BO_ 840 0;
BA_ "MessageSubnet" BO_ 840 2;
BA_ "GenMsgCycleTime" BO_ 840 50;
BA_ "GenMsgSendType" BO_ 840 0;
BA_ "Prio" BO_ 193 0;
BA_ "MessageSubnet" BO_ 193 2;
BA_ "GenMsgCycleTime" BO_ 193 10;
BA_ "GenMsgSendType" BO_ 193 0;
BA_ "Prio" BO_ 481 0;
BA_ "MessageSubnet" BO_ 481 2;
BA_ "GenMsgStartDelayTime" BO_ 481 10;
BA_ "GenMsgCycleTime" BO_ 481 30;
BA_ "GenMsgSendType" BO_ 481 0;
BA_ "Prio" BO_ 455 0;
BA_ "MessageSubnet" BO_ 455 2;
BA_ "GenMsgCycleTime" BO_ 455 20;
BA_ "GenMsgSendType" BO_ 455 0;
BA_ "Prio" BO_ 761 0;
BA_ "MessageSubnet" BO_ 761 2;
BA_ "GenMsgCycleTime" BO_ 761 50;
BA_ "GenMsgSendType" BO_ 761 0;
BA_ "Prio" BO_ 489 0;
BA_ "MessageSubnet" BO_ 489 2;
BA_ "GenMsgCycleTime" BO_ 489 20;
BA_ "GenMsgSendType" BO_ 489 0;
BA_ "Prio" BO_ 381 0;
BA_ "MessageSubnet" BO_ 381 2;
BA_ "GenMsgCycleTime" BO_ 381 100;
BA_ "GenMsgSendType" BO_ 381 0;
BA_ "Prio" BO_ 241 0;
BA_ "MessageSubnet" BO_ 241 2;
BA_ "GenMsgCycleTime" BO_ 241 10;
BA_ "GenMsgSendType" BO_ 241 0;
BA_ "Prio" BO_ 2025 0;
BA_ "MessageSubnet" BO_ 2025 2;
BA_ "DiagResponse" BO_ 2025 1;
BA_ "Prio" BO_ 2029 0;
BA_ "MessageSubnet" BO_ 2029 2;
BA_ "DiagResponse" BO_ 2029 1;
BA_ "Prio" BO_ 2031 0;
BA_ "MessageSubnet" BO_ 2031 2;
BA_ "DiagResponse" BO_ 2031 1;
BA_ "GenMsgILSupport" BO_ 1513 0;
BA_ "TpApplType" BO_ 1513 "DiagUUDTResponse";
BA_ "Prio" BO_ 1513 0;
BA_ "MessageSubnet" BO_ 1513 2;
BA_ "GenMsgILSupport" BO_ 1517 0;
BA_ "TpApplType" BO_ 1517 "DiagUUDTResponse";
BA_ "Prio" BO_ 1517 0;
BA_ "MessageSubnet" BO_ 1517 2;
BA_ "GenMsgILSupport" BO_ 1519 0;
BA_ "TpApplType" BO_ 1519 "DiagUUDTResponse";
BA_ "Prio" BO_ 1519 0;
BA_ "MessageSubnet" BO_ 1519 2;
BA_ "Prio" BO_ 2030 0;
BA_ "MessageSubnet" BO_ 2030 2;
BA_ "DiagResponse" BO_ 2030 1;
BA_ "GenMsgILSupport" BO_ 1518 0;
BA_ "TpApplType" BO_ 1518 "DiagUUDTResponse";
BA_ "Prio" BO_ 1518 0;
BA_ "MessageSubnet" BO_ 1518 2;
BA_ "GenMsgILSupport" BO_ 1346 0;
BA_ "TpApplType" BO_ 1346 "DiagUUDTResponse";
BA_ "Prio" BO_ 1346 0;
BA_ "MessageSubnet" BO_ 1346 2;
BA_ "GenMsgILSupport" BO_ 1353 0;
BA_ "TpApplType" BO_ 1353 "DiagUUDTResponse";
BA_ "Prio" BO_ 1353 0;
BA_ "MessageSubnet" BO_ 1353 2;
BA_ "Prio" BO_ 1609 0;
BA_ "MessageSubnet" BO_ 1609 2;
BA_ "DiagResponse" BO_ 1609 1;
BA_ "Prio" BO_ 1602 0;
BA_ "MessageSubnet" BO_ 1602 2;
BA_ "DiagResponse" BO_ 1602 1;
BA_ "Prio" BO_ 2027 0;
BA_ "MessageSubnet" BO_ 2027 2;
BA_ "DiagResponse" BO_ 2027 1;
BA_ "GenMsgILSupport" BO_ 1515 0;
BA_ "TpApplType" BO_ 1515 "DiagUUDTResponse";
BA_ "Prio" BO_ 1515 0;
BA_ "MessageSubnet" BO_ 1515 2;
BA_ "Prio" BO_ 1614 0;
BA_ "MessageSubnet" BO_ 1614 2;
BA_ "DiagResponse" BO_ 1614 1;
BA_ "GenMsgILSupport" BO_ 1348 0;
BA_ "TpApplType" BO_ 1348 "DiagUUDTResponse";
BA_ "Prio" BO_ 1348 0;
BA_ "MessageSubnet" BO_ 1348 2;
BA_ "GenMsgILSupport" BO_ 1349 0;
BA_ "TpApplType" BO_ 1349 "DiagUUDTResponse";
BA_ "Prio" BO_ 1349 0;
BA_ "MessageSubnet" BO_ 1349 2;
BA_ "GenMsgILSupport" BO_ 1352 0;
BA_ "TpApplType" BO_ 1352 "DiagUUDTResponse";
BA_ "Prio" BO_ 1352 0;
BA_ "MessageSubnet" BO_ 1352 2;
BA_ "GenMsgILSupport" BO_ 1354 0;
BA_ "TpApplType" BO_ 1354 "DiagUUDTResponse";
BA_ "Prio" BO_ 1354 0;
BA_ "MessageSubnet" BO_ 1354 2;
BA_ "Prio" BO_ 1605 0;
BA_ "MessageSubnet" BO_ 1605 2;
BA_ "DiagResponse" BO_ 1605 1;
BA_ "Prio" BO_ 1620 0;
BA_ "MessageSubnet" BO_ 1620 2;
BA_ "DiagResponse" BO_ 1620 1;
BA_ "Prio" BO_ 1604 0;
BA_ "MessageSubnet" BO_ 1604 2;
BA_ "DiagResponse" BO_ 1604 1;
BA_ "GenMsgILSupport" BO_ 1612 0;
BA_ "Prio" BO_ 1612 0;
BA_ "MessageSubnet" BO_ 1612 2;
BA_ "DiagResponse" BO_ 1612 1;
BA_ "Prio" BO_ 1615 0;
BA_ "MessageSubnet" BO_ 1615 2;
BA_ "DiagResponse" BO_ 1615 1;
BA_ "GenSigSendType" SG_ 497 ElvtdIdlCstStReq 10;
BA_ "SignalType" SG_ 497 ElvtdIdlCstStReq "ENM";
BA_ "SignalLongName" SG_ 497 ElvtdIdlCstStReq "Elevated Idle Customization Setting Request";
BA_ "VNSigAllNodes" SG_ 497 ElvtdIdlCstStReq 1;
BA_ "GenSigSendType" SG_ 497 FuelFltLfRstRqd 10;
BA_ "SignalType" SG_ 497 FuelFltLfRstRqd "BLN";
BA_ "SignalLongName" SG_ 497 FuelFltLfRstRqd "Fuel Filter Life Reset Requested";
BA_ "VNSigAllNodes" SG_ 497 FuelFltLfRstRqd 1;
BA_ "GenSigSendType" SG_ 497 ACCompSysVDA 10;
BA_ "SignalType" SG_ 497 ACCompSysVDA "ENM";
BA_ "SignalLongName" SG_ 497 ACCompSysVDA "Air Conditioning Compressor System Virtual Device Availability";
BA_ "GenSigStartValue" SG_ 497 ACCompSysVDA 1;
BA_ "VNSigAllNodes" SG_ 497 ACCompSysVDA 1;
BA_ "GenSigSendType" SG_ 497 BkupPwrModeMstrVDA 10;
BA_ "SignalType" SG_ 497 BkupPwrModeMstrVDA "ENM";
BA_ "SignalLongName" SG_ 497 BkupPwrModeMstrVDA "Backup Power Mode Master Virtual Device Availability";
BA_ "GenSigStartValue" SG_ 497 BkupPwrModeMstrVDA 1;
BA_ "VNSigAllNodes" SG_ 497 BkupPwrModeMstrVDA 1;
BA_ "GenSigSendType" SG_ 497 PrkBrkVDA 10;
BA_ "SignalType" SG_ 497 PrkBrkVDA "ENM";
BA_ "SignalLongName" SG_ 497 PrkBrkVDA "Park Brake Virtual Device Availability";
BA_ "GenSigStartValue" SG_ 497 PrkBrkVDA 1;
BA_ "VNSigAllNodes" SG_ 497 PrkBrkVDA 1;
BA_ "GenSigSendType" SG_ 497 PrkBrkVDM 10;
BA_ "SignalType" SG_ 497 PrkBrkVDM "ENM";
BA_ "SignalLongName" SG_ 497 PrkBrkVDM "Park Brake Virtual Device Mask";
BA_ "GenSigStartValue" SG_ 497 PrkBrkVDM 1;
BA_ "VNSigAllNodes" SG_ 497 PrkBrkVDM 1;
BA_ "GenSigSendType" SG_ 497 BkupPwrModeMstrVDM 10;
BA_ "SignalType" SG_ 497 BkupPwrModeMstrVDM "ENM";
BA_ "SignalLongName" SG_ 497 BkupPwrModeMstrVDM "Backup Power Mode Master Virtual Device Mask";
BA_ "VNSigAllNodes" SG_ 497 BkupPwrModeMstrVDM 1;
BA_ "GenSigSendType" SG_ 497 ACCompSysVDM 10;
BA_ "SignalType" SG_ 497 ACCompSysVDM "ENM";
BA_ "SignalLongName" SG_ 497 ACCompSysVDM "Air Conditioning Compressor System Virtual Device Mask";
BA_ "VNSigAllNodes" SG_ 497 ACCompSysVDM 1;
BA_ "GenSigSendType" SG_ 497 AirbgVDA 10;
BA_ "SignalType" SG_ 497 AirbgVDA "ENM";
BA_ "SignalLongName" SG_ 497 AirbgVDA "Airbag Virtual Device Availability";
BA_ "GenSigStartValue" SG_ 497 AirbgVDA 1;
BA_ "VNSigAllNodes" SG_ 497 AirbgVDA 1;
BA_ "GenSigSendType" SG_ 497 SysBkupPwrMdEn 10;
BA_ "SignalType" SG_ 497 SysBkupPwrMdEn "BLN";
BA_ "SignalLongName" SG_ 497 SysBkupPwrMdEn "System Backup Power Mode Enabled";
BA_ "VNSigAllNodes" SG_ 497 SysBkupPwrMdEn 1;
BA_ "GenSigSendType" SG_ 497 SysBkUpPwrMd 10;
BA_ "SignalType" SG_ 497 SysBkUpPwrMd "ENM";
BA_ "SignalLongName" SG_ 497 SysBkUpPwrMd "System Backup Power Mode";
BA_ "VNSigAllNodes" SG_ 497 SysBkUpPwrMd 1;
BA_ "GenSigSendType" SG_ 497 SysPwrMd 10;
BA_ "SignalType" SG_ 497 SysPwrMd "ENM";
BA_ "SignalLongName" SG_ 497 SysPwrMd "System Power Mode";
BA_ "VNSigAllNodes" SG_ 497 SysPwrMd 1;
BA_ "GenSigSendType" SG_ 497 TrStLgMdAtv 10;
BA_ "SignalType" SG_ 497 TrStLgMdAtv "BLN";
BA_ "SignalLongName" SG_ 497 TrStLgMdAtv "Transport Storage Logistic Mode Active";
BA_ "VNSigAllNodes" SG_ 497 TrStLgMdAtv 1;
BA_ "GenSigSendType" SG_ 497 DispMeasSys 10;
BA_ "SignalType" SG_ 497 DispMeasSys "ENM";
BA_ "SignalLongName" SG_ 497 DispMeasSys "Display Measurement System";
BA_ "VNSigAllNodes" SG_ 497 DispMeasSys 1;
BA_ "GenSigSendType" SG_ 497 ACCmpsrFldOn 10;
BA_ "SignalType" SG_ 497 ACCmpsrFldOn "BLN";
BA_ "SignalLongName" SG_ 497 ACCmpsrFldOn "Air Conditioning Compressor Failed On";
BA_ "VNSigAllNodes" SG_ 497 ACCmpsrFldOn 1;
BA_ "GenSigSendType" SG_ 497 ACCompModReq 10;
BA_ "SignalType" SG_ 497 ACCompModReq "ENM";
BA_ "SignalLongName" SG_ 497 ACCompModReq "Air Conditioning Compressor Mode Request";
BA_ "VNSigAllNodes" SG_ 497 ACCompModReq 1;
BA_ "GenSigDeltaValue" SG_ 497 ACCompNormLd 1;
BA_ "GenSigSendType" SG_ 497 ACCompNormLd 12;
BA_ "SignalType" SG_ 497 ACCompNormLd "UNM";
BA_ "SignalLongName" SG_ 497 ACCompNormLd "Air Conditioning Compressor Normalized Load";
BA_ "VNSigAllNodes" SG_ 497 ACCompNormLd 1;
BA_ "GenSigSendType" SG_ 497 ACCompNormLdV 10;
BA_ "SignalType" SG_ 497 ACCompNormLdV "ENM";
BA_ "SignalLongName" SG_ 497 ACCompNormLdV "Air Conditioning Compressor Normalized Load Validity";
BA_ "VNSigAllNodes" SG_ 497 ACCompNormLdV 1;
BA_ "GenSigSendType" SG_ 497 PTORSMstrEngShtReq 10;
BA_ "SignalType" SG_ 497 PTORSMstrEngShtReq "BLN";
BA_ "SignalLongName" SG_ 497 PTORSMstrEngShtReq "Power Take Off Remote Start Master Engine Shutdown Requested";
BA_ "VNSigAllNodes" SG_ 497 PTORSMstrEngShtReq 1;
BA_ "GenSigSendType" SG_ 497 EngOilLfRstRq 10;
BA_ "SignalType" SG_ 497 EngOilLfRstRq "BLN";
BA_ "SignalLongName" SG_ 497 EngOilLfRstRq "Engine Oil Life Reset Request";
BA_ "VNSigAllNodes" SG_ 497 EngOilLfRstRq 1;
BA_ "GenSigSendType" SG_ 497 SIRDpl 10;
BA_ "SignalType" SG_ 497 SIRDpl "BLN";
BA_ "SignalLongName" SG_ 497 SIRDpl "Airbag Deployed";
BA_ "VNSigAllNodes" SG_ 497 SIRDpl 1;
BA_ "GenSigSendType" SG_ 497 PTORmStMsEngStRq 10;
BA_ "SignalType" SG_ 497 PTORmStMsEngStRq "ENM";
BA_ "SignalLongName" SG_ 497 PTORmStMsEngStRq "Power Take Off Remote Start Master Engine Start Request";
BA_ "VNSigAllNodes" SG_ 497 PTORmStMsEngStRq 1;
BA_ "GenSigSendType" SG_ 497 RmVehStrRq 10;
BA_ "SignalType" SG_ 497 RmVehStrRq "ENM";
BA_ "SignalLongName" SG_ 497 RmVehStrRq "Remote Vehicle Start Request";
BA_ "VNSigAllNodes" SG_ 497 RmVehStrRq 1;
BA_ "GenSigSendType" SG_ 497 ThrtlPrgrsnReq 10;
BA_ "SignalType" SG_ 497 ThrtlPrgrsnReq "ENM";
BA_ "SignalLongName" SG_ 497 ThrtlPrgrsnReq "Throttle Progression Request";
BA_ "VNSigAllNodes" SG_ 497 ThrtlPrgrsnReq 1;
BA_ "GenSigSendType" SG_ 497 PrkBrkSwAtv 10;
BA_ "SignalType" SG_ 497 PrkBrkSwAtv "BLN";
BA_ "SignalLongName" SG_ 497 PrkBrkSwAtv "Park Brake Switch Active";
BA_ "VNSigAllNodes" SG_ 497 PrkBrkSwAtv 1;
BA_ "GenSigSendType" SG_ 497 PMMAccTrmSt 10;
BA_ "SignalType" SG_ 497 PMMAccTrmSt "ENM";
BA_ "SignalLongName" SG_ 497 PMMAccTrmSt "Power Mode Master Accessory Terminal Status";
BA_ "VNSigAllNodes" SG_ 497 PMMAccTrmSt 1;
BA_ "GenSigSendType" SG_ 497 PMMRunCrkTrmSt 10;
BA_ "SignalType" SG_ 497 PMMRunCrkTrmSt "ENM";
BA_ "SignalLongName" SG_ 497 PMMRunCrkTrmSt "Power Mode Master Run Crank Terminal Status";
BA_ "VNSigAllNodes" SG_ 497 PMMRunCrkTrmSt 1;
BA_ "GenSigSendType" SG_ 497 ImmblzrPreRelPswdStat 10;
BA_ "SignalType" SG_ 497 ImmblzrPreRelPswdStat "ENM";
BA_ "SignalLongName" SG_ 497 ImmblzrPreRelPswdStat "Immobilizer Pre Release Password Status";
BA_ "VNSigAllNodes" SG_ 497 ImmblzrPreRelPswdStat 1;
BA_ "GenSigDeltaValue" SG_ 497 ImmblzrPreRelPswrd 1;
BA_ "GenSigSendType" SG_ 497 ImmblzrPreRelPswrd 12;
BA_ "SignalType" SG_ 497 ImmblzrPreRelPswrd "UNM";
BA_ "SignalLongName" SG_ 497 ImmblzrPreRelPswrd "Immobilizer Pre Release Password";
BA_ "VNSigAllNodes" SG_ 497 ImmblzrPreRelPswrd 1;
BA_ "SignalType" SG_ 969 ImoInf "UNM";
BA_ "SignalLongName" SG_ 969 ImoInf "Immobilizer Information";
BA_ "VNSigAllNodes" SG_ 969 ImoInf 1;
BA_ "SignalType" SG_ 1249 VehIdNmDig10_17 "ASC";
BA_ "SignalLongName" SG_ 1249 VehIdNmDig10_17 "Vehicle Identification Number Digits 10-17";
BA_ "VNSigAllNodes" SG_ 1249 VehIdNmDig10_17 1;
BA_ "VNSigSLHSSharedDiagnostic" SG_ 2024 DgnInf 1;
BA_ "SignalType" SG_ 2024 DgnInf "UNM";
BA_ "SignalLongName" SG_ 2024 DgnInf "Diagnostic Information";
BA_ "VNSigAllNodes" SG_ 2024 DgnInf 1;
BA_ "VNSigSLHSSharedDiagnostic" SG_ 1512 DgnInf 1;
BA_ "SignalType" SG_ 1512 DgnInf "UNM";
BA_ "SignalLongName" SG_ 1512 DgnInf "Diagnostic Information";
BA_ "VNSigAllNodes" SG_ 1512 DgnInf 1;
BA_ "SignalType" SG_ 840 WhlRotDrctnlStLftDrvn "ENM";
BA_ "SignalLongName" SG_ 840 WhlRotDrctnlStLftDrvn "Wheel Rotational Directional Status Left Driven";
BA_ "VNSigAllNodes" SG_ 840 WhlRotDrctnlStLftDrvn 1;
BA_ "SignalType" SG_ 840 WhlRotDrctnlStRtDrvn "ENM";
BA_ "SignalLongName" SG_ 840 WhlRotDrctnlStRtDrvn "Wheel Rotational Directional Status Right Driven";
BA_ "VNSigAllNodes" SG_ 840 WhlRotDrctnlStRtDrvn 1;
BA_ "SignalType" SG_ 840 WhlGrndVlctyRtDrvnV "ENM";
BA_ "SignalLongName" SG_ 840 WhlGrndVlctyRtDrvnV "Wheel Ground Velocity Right Driven Validity";
BA_ "VNSigAllNodes" SG_ 840 WhlGrndVlctyRtDrvnV 1;
BA_ "SignalType" SG_ 840 WhlGrndVlctyRtDrvn "UNM";
BA_ "SignalLongName" SG_ 840 WhlGrndVlctyRtDrvn "Wheel Ground Velocity Right Driven";
BA_ "VNSigAllNodes" SG_ 840 WhlGrndVlctyRtDrvn 1;
BA_ "SignalType" SG_ 840 WhlGrndVlctyLftDrvnV "ENM";
BA_ "SignalLongName" SG_ 840 WhlGrndVlctyLftDrvnV "Wheel Ground Velocity Left Driven Validity";
BA_ "VNSigAllNodes" SG_ 840 WhlGrndVlctyLftDrvnV 1;
BA_ "SignalType" SG_ 840 WhlGrndVlctyLftDrvn "UNM";
BA_ "SignalLongName" SG_ 840 WhlGrndVlctyLftDrvn "Wheel Ground Velocity Left Driven";
BA_ "VNSigAllNodes" SG_ 840 WhlGrndVlctyLftDrvn 1;
BA_ "SignalType" SG_ 193 WRSLDWhlDisTpRC "UNM";
BA_ "PacketOrder" SG_ 193 WRSLDWhlDisTpRC 1;
BA_ "SignalLongName" SG_ 193 WRSLDWhlDisTpRC "Wheel Rotational Status Left Driven : Wheel Distance Timestamp Rollover Counter";
BA_ "VNSigAllNodes" SG_ 193 WRSLDWhlDisTpRC 1;
BA_ "SignalType" SG_ 193 WRSLDSeqNum "UNM";
BA_ "PacketOrder" SG_ 193 WRSLDSeqNum 2;
BA_ "SignalLongName" SG_ 193 WRSLDSeqNum "Wheel Rotational Status Left Driven : Sequence Number";
BA_ "VNSigAllNodes" SG_ 193 WRSLDSeqNum 1;
BA_ "SignalType" SG_ 193 WRSLDWhlDistVal "ENM";
BA_ "PacketOrder" SG_ 193 WRSLDWhlDistVal 4;
BA_ "SignalLongName" SG_ 193 WRSLDWhlDistVal "Wheel Rotational Status Left Driven : Wheel Distance Validity";
BA_ "VNSigAllNodes" SG_ 193 WRSLDWhlDistVal 1;
BA_ "SignalType" SG_ 193 WRSLDWhlRotStatRst "BLN";
BA_ "PacketOrder" SG_ 193 WRSLDWhlRotStatRst 3;
BA_ "SignalLongName" SG_ 193 WRSLDWhlRotStatRst "Wheel Rotational Status Left Driven : Wheel Rotational Status Reset Occurred";
BA_ "VNSigAllNodes" SG_ 193 WRSLDWhlRotStatRst 1;
BA_ "SignalType" SG_ 193 WRSLDWhlDistTmstm "UNM";
BA_ "PacketOrder" SG_ 193 WRSLDWhlDistTmstm 6;
BA_ "SignalLongName" SG_ 193 WRSLDWhlDistTmstm "Wheel Rotational Status Left Driven : Wheel Distance Timestamp";
BA_ "VNSigAllNodes" SG_ 193 WRSLDWhlDistTmstm 1;
BA_ "SignalType" SG_ 193 WRSLDWhlDistPlsCntr "UNM";
BA_ "PacketOrder" SG_ 193 WRSLDWhlDistPlsCntr 5;
BA_ "SignalLongName" SG_ 193 WRSLDWhlDistPlsCntr "Wheel Rotational Status Left Driven : Wheel Distance Pulse Counter";
BA_ "VNSigAllNodes" SG_ 193 WRSLDWhlDistPlsCntr 1;
BA_ "SignalType" SG_ 193 WRSRDWhlDisTpRC "UNM";
BA_ "PacketOrder" SG_ 193 WRSRDWhlDisTpRC 1;
BA_ "SignalLongName" SG_ 193 WRSRDWhlDisTpRC "Wheel Rotational Status Right Driven : Wheel Distance Timestamp Rollover Counter";
BA_ "VNSigAllNodes" SG_ 193 WRSRDWhlDisTpRC 1;
BA_ "SignalType" SG_ 193 WRSRDSeqNum "UNM";
BA_ "PacketOrder" SG_ 193 WRSRDSeqNum 2;
BA_ "SignalLongName" SG_ 193 WRSRDSeqNum "Wheel Rotational Status Right Driven : Sequence Number";
BA_ "VNSigAllNodes" SG_ 193 WRSRDSeqNum 1;
BA_ "SignalType" SG_ 193 WRSRDWhlRotStatRst "BLN";
BA_ "PacketOrder" SG_ 193 WRSRDWhlRotStatRst 3;
BA_ "SignalLongName" SG_ 193 WRSRDWhlRotStatRst "Wheel Rotational Status Right Driven : Wheel Rotational Status Reset Occurred";
BA_ "VNSigAllNodes" SG_ 193 WRSRDWhlRotStatRst 1;
BA_ "SignalType" SG_ 193 WRSRDWhlDistVal "ENM";
BA_ "PacketOrder" SG_ 193 WRSRDWhlDistVal 4;
BA_ "SignalLongName" SG_ 193 WRSRDWhlDistVal "Wheel Rotational Status Right Driven : Wheel Distance Validity";
BA_ "VNSigAllNodes" SG_ 193 WRSRDWhlDistVal 1;
BA_ "SignalType" SG_ 193 WRSRDWhlDistTmstm "UNM";
BA_ "PacketOrder" SG_ 193 WRSRDWhlDistTmstm 6;
BA_ "SignalLongName" SG_ 193 WRSRDWhlDistTmstm "Wheel Rotational Status Right Driven : Wheel Distance Timestamp";
BA_ "VNSigAllNodes" SG_ 193 WRSRDWhlDistTmstm 1;
BA_ "SignalType" SG_ 193 WRSRDWhlDistPlsCntr "UNM";
BA_ "PacketOrder" SG_ 193 WRSRDWhlDistPlsCntr 5;
BA_ "SignalLongName" SG_ 193 WRSRDWhlDistPlsCntr "Wheel Rotational Status Right Driven : Wheel Distance Pulse Counter";
BA_ "VNSigAllNodes" SG_ 193 WRSRDWhlDistPlsCntr 1;
BA_ "SignalType" SG_ 481 CrsSecSwStatPVal "UNM";
BA_ "SignalLongName" SG_ 481 CrsSecSwStatPVal "Cruise Secondary Switch Status Protection Value";
BA_ "VNSigAllNodes" SG_ 481 CrsSecSwStatPVal 1;
BA_ "SignalType" SG_ 481 CrsSecSwStatARC "UNM";
BA_ "SignalLongName" SG_ 481 CrsSecSwStatARC "Cruise Secondary Switch Status Alive Rolling Count";
BA_ "VNSigAllNodes" SG_ 481 CrsSecSwStatARC 1;
BA_ "SignalType" SG_ 481 CrsSecSwStat "ENM";
BA_ "SignalLongName" SG_ 481 CrsSecSwStat "Cruise Secondary Switch Status";
BA_ "VNSigAllNodes" SG_ 481 CrsSecSwStat 1;
BA_ "SignalType" SG_ 481 DrvSelMdSw3Sta "ENM";
BA_ "SignalLongName" SG_ 481 DrvSelMdSw3Sta "Driver Selected Mode Switch 3 State";
BA_ "VNSigAllNodes" SG_ 481 DrvSelMdSw3Sta 1;
BA_ "SignalType" SG_ 481 DrvSelMdSw2Sta "ENM";
BA_ "SignalLongName" SG_ 481 DrvSelMdSw2Sta "Driver Selected Mode Switch 2 State";
BA_ "VNSigAllNodes" SG_ 481 DrvSelMdSw2Sta 1;
BA_ "SignalType" SG_ 481 AuxHtrRq "ENM";
BA_ "SignalLongName" SG_ 481 AuxHtrRq "Auxiliary Heater Request";
BA_ "VNSigAllNodes" SG_ 481 AuxHtrRq 1;
BA_ "SignalType" SG_ 481 AuxHtrAtv "BLN";
BA_ "SignalLongName" SG_ 481 AuxHtrAtv "Auxiliary Heater Active";
BA_ "VNSigAllNodes" SG_ 481 AuxHtrAtv 1;
BA_ "SignalType" SG_ 481 DrvSelMdSwStaARC "UNM";
BA_ "SignalLongName" SG_ 481 DrvSelMdSwStaARC "Driver Selected Mode Switch State Alive Rolling Count";
BA_ "VNSigAllNodes" SG_ 481 DrvSelMdSwStaARC 1;
BA_ "SignalType" SG_ 481 DrvSelMdSw1Sta "ENM";
BA_ "SignalLongName" SG_ 481 DrvSelMdSw1Sta "Driver Selected Mode Switch 1 State";
BA_ "VNSigAllNodes" SG_ 481 DrvSelMdSw1Sta 1;
BA_ "SignalType" SG_ 481 CrsSpdLmtrSwStatPVal "UNM";
BA_ "SignalLongName" SG_ 481 CrsSpdLmtrSwStatPVal "Cruise and Speed Limiter Switch Status Protection Value";
BA_ "VNSigAllNodes" SG_ 481 CrsSpdLmtrSwStatPVal 1;
BA_ "SignalType" SG_ 481 CrsSpdLmtrSwStatARC "UNM";
BA_ "SignalLongName" SG_ 481 CrsSpdLmtrSwStatARC "Cruise and Speed Limiter Switch Status Alive Rolling Count";
BA_ "VNSigAllNodes" SG_ 481 CrsSpdLmtrSwStatARC 1;
BA_ "SignalType" SG_ 481 FuelMdSwActV "ENM";
BA_ "SignalLongName" SG_ 481 FuelMdSwActV "Fuel Mode Switch Active Validity";
BA_ "VNSigAllNodes" SG_ 481 FuelMdSwActV 1;
BA_ "SignalType" SG_ 481 FuelMdSwAct "ENM";
BA_ "SignalLongName" SG_ 481 FuelMdSwAct "Fuel Mode Switch Active";
BA_ "VNSigAllNodes" SG_ 481 FuelMdSwAct 1;
BA_ "SignalType" SG_ 481 CrsSpdLmtrSwStat "ENM";
BA_ "SignalLongName" SG_ 481 CrsSpdLmtrSwStat "Cruise and Speed Limiter Switch Status";
BA_ "VNSigAllNodes" SG_ 481 CrsSpdLmtrSwStat 1;
BA_ "SignalType" SG_ 481 AdptCrsGapSwAct "ENM";
BA_ "SignalLongName" SG_ 481 AdptCrsGapSwAct "Adaptive Cruise Control Gap Switch Activation";
BA_ "VNSigAllNodes" SG_ 481 AdptCrsGapSwAct 1;
BA_ "SignalType" SG_ 481 CrsCntrlSwStCanSwAct "BLN";
BA_ "PacketOrder" SG_ 481 CrsCntrlSwStCanSwAct 1;
BA_ "SignalLongName" SG_ 481 CrsCntrlSwStCanSwAct "Cruise Control Switch Status : Cancel Switch Active";
BA_ "VNSigAllNodes" SG_ 481 CrsCntrlSwStCanSwAct 1;
BA_ "SignalType" SG_ 481 CrsCntrlSwStSwDataIntgty "ENM";
BA_ "PacketOrder" SG_ 481 CrsCntrlSwStSwDataIntgty 7;
BA_ "SignalLongName" SG_ 481 CrsCntrlSwStSwDataIntgty "Cruise Control Switch Status : Switch Data Integrity";
BA_ "VNSigAllNodes" SG_ 481 CrsCntrlSwStSwDataIntgty 1;
BA_ "SignalType" SG_ 481 CrsCntrlSwStSpdInSwAct "BLN";
BA_ "PacketOrder" SG_ 481 CrsCntrlSwStSpdInSwAct 5;
BA_ "SignalLongName" SG_ 481 CrsCntrlSwStSpdInSwAct "Cruise Control Switch Status : Speed Increase Switch Active";
BA_ "VNSigAllNodes" SG_ 481 CrsCntrlSwStSpdInSwAct 1;
BA_ "SignalType" SG_ 481 CrsCntrlSwStSpDcSwAct "BLN";
BA_ "PacketOrder" SG_ 481 CrsCntrlSwStSpDcSwAct 6;
BA_ "SignalLongName" SG_ 481 CrsCntrlSwStSpDcSwAct "Cruise Control Switch Status : Speed Decrease Switch Active";
BA_ "VNSigAllNodes" SG_ 481 CrsCntrlSwStSpDcSwAct 1;
BA_ "SignalType" SG_ 481 CrsCntrlSwStSetSwAct "BLN";
BA_ "PacketOrder" SG_ 481 CrsCntrlSwStSetSwAct 4;
BA_ "SignalLongName" SG_ 481 CrsCntrlSwStSetSwAct "Cruise Control Switch Status : Set Switch Active";
BA_ "VNSigAllNodes" SG_ 481 CrsCntrlSwStSetSwAct 1;
BA_ "SignalType" SG_ 481 CrsCntrlSwStResSwAct "BLN";
BA_ "PacketOrder" SG_ 481 CrsCntrlSwStResSwAct 3;
BA_ "SignalLongName" SG_ 481 CrsCntrlSwStResSwAct "Cruise Control Switch Status : Resume Switch Active";
BA_ "VNSigAllNodes" SG_ 481 CrsCntrlSwStResSwAct 1;
BA_ "SignalType" SG_ 481 CrsCntrlSwStOnSwAct "BLN";
BA_ "PacketOrder" SG_ 481 CrsCntrlSwStOnSwAct 2;
BA_ "SignalLongName" SG_ 481 CrsCntrlSwStOnSwAct "Cruise Control Switch Status : On Switch Active";
BA_ "VNSigAllNodes" SG_ 481 CrsCntrlSwStOnSwAct 1;
BA_ "SignalType" SG_ 481 CrsCntrlSwStatProtValue "UNM";
BA_ "SignalLongName" SG_ 481 CrsCntrlSwStatProtValue "Cruise Control Switch Status Protection Value";
BA_ "VNSigAllNodes" SG_ 481 CrsCntrlSwStatProtValue 1;
BA_ "SignalType" SG_ 481 CrsCntrlSwStAlvRollCnt "UNM";
BA_ "SignalLongName" SG_ 481 CrsCntrlSwStAlvRollCnt "Cruise Control Switch Status Alive Rolling Count";
BA_ "VNSigAllNodes" SG_ 481 CrsCntrlSwStAlvRollCnt 1;
BA_ "SignalType" SG_ 481 CrsCntCncRq "ENM";
BA_ "SignalLongName" SG_ 481 CrsCntCncRq "Cruise Control Cancel Request";
BA_ "VNSigAllNodes" SG_ 481 CrsCntCncRq 1;
BA_ "SignalType" SG_ 455 CSETRER_TorqReqVal "UNM";
BA_ "PacketOrder" SG_ 455 CSETRER_TorqReqVal 2;
BA_ "SignalLongName" SG_ 455 CSETRER_TorqReqVal "Chassis System Engine Torque Request Extended Range : Torque Request Value";
BA_ "VNSigAllNodes" SG_ 455 CSETRER_TorqReqVal 1;
BA_ "SignalType" SG_ 455 CSETRER_TqIntvnTyp "ENM";
BA_ "PacketOrder" SG_ 455 CSETRER_TqIntvnTyp 1;
BA_ "SignalLongName" SG_ 455 CSETRER_TqIntvnTyp "Chassis System Engine Torque Request Extended Range : Torque Intervention Type";
BA_ "VNSigAllNodes" SG_ 455 CSETRER_TqIntvnTyp 1;
BA_ "SignalType" SG_ 455 TracCntrlMaxTorqIncRt "UNM";
BA_ "SignalLongName" SG_ 455 TracCntrlMaxTorqIncRt "Traction Control Maximum Torque Increase Rate";
BA_ "VNSigAllNodes" SG_ 455 TracCntrlMaxTorqIncRt 1;
BA_ "SignalType" SG_ 455 TCAliveRC "UNM";
BA_ "SignalLongName" SG_ 455 TCAliveRC "Traction Control Alive Rolling Count";
BA_ "VNSigAllNodes" SG_ 455 TCAliveRC 1;
BA_ "SignalType" SG_ 455 ChsSysEngTrqReqProt "UNM";
BA_ "SignalLongName" SG_ 455 ChsSysEngTrqReqProt "Chassis System Engine Torque Request Protection";
BA_ "VNSigAllNodes" SG_ 455 ChsSysEngTrqReqProt 1;
BA_ "SignalType" SG_ 761 BrkSysHRBkCtrlAvail "BLN";
BA_ "SignalLongName" SG_ 761 BrkSysHRBkCtrlAvail "Brake System Hill Rollback Control Available";
BA_ "VNSigAllNodes" SG_ 761 BrkSysHRBkCtrlAvail 1;
BA_ "SignalType" SG_ 761 BrkSysHRBkCtrlStat "ENM";
BA_ "SignalLongName" SG_ 761 BrkSysHRBkCtrlStat "Brake System Hill Rollback Control Status";
BA_ "VNSigAllNodes" SG_ 761 BrkSysHRBkCtrlStat 1;
BA_ "SignalType" SG_ 761 BrkSysHSAAval "BLN";
BA_ "SignalLongName" SG_ 761 BrkSysHSAAval "Brake System Hill Start Assist Available";
BA_ "VNSigAllNodes" SG_ 761 BrkSysHSAAval 1;
BA_ "SignalType" SG_ 761 BrkSysHSAStat "ENM";
BA_ "SignalLongName" SG_ 761 BrkSysHSAStat "Brake System Hill Start Assist Status";
BA_ "VNSigAllNodes" SG_ 761 BrkSysHSAStat 1;
BA_ "SignalType" SG_ 761 HillDscntCtrlStatPVal "UNM";
BA_ "SignalLongName" SG_ 761 HillDscntCtrlStatPVal "Hill Descent Control Status Protection Value";
BA_ "VNSigAllNodes" SG_ 761 HillDscntCtrlStatPVal 1;
BA_ "SignalType" SG_ 761 HillDscntCtrlStatARC "UNM";
BA_ "SignalLongName" SG_ 761 HillDscntCtrlStatARC "Hill Descent Control Status Alive Rolling Count";
BA_ "VNSigAllNodes" SG_ 761 HillDscntCtrlStatARC 1;
BA_ "SignalType" SG_ 761 HillDscntCtrlStat "ENM";
BA_ "SignalLongName" SG_ 761 HillDscntCtrlStat "Hill Descent Control Status";
BA_ "VNSigAllNodes" SG_ 761 HillDscntCtrlStat 1;
BA_ "SignalType" SG_ 761 AutoBrkFeatInhbtPVal "UNM";
BA_ "SignalLongName" SG_ 761 AutoBrkFeatInhbtPVal "Automatic Braking Feature Inhibit Protection Value";
BA_ "VNSigAllNodes" SG_ 761 AutoBrkFeatInhbtPVal 1;
BA_ "SignalType" SG_ 761 AutoBrkFeatInhbtARC "UNM";
BA_ "SignalLongName" SG_ 761 AutoBrkFeatInhbtARC "Automatic Braking Feature Inhibit Alive Rolling Count";
BA_ "VNSigAllNodes" SG_ 761 AutoBrkFeatInhbtARC 1;
BA_ "SignalType" SG_ 761 ABFI_CollPrepSysInhbt "BLN";
BA_ "PacketOrder" SG_ 761 ABFI_CollPrepSysInhbt 2;
BA_ "SignalLongName" SG_ 761 ABFI_CollPrepSysInhbt "Automatic Braking Feature Inhibit : Collision Preparation System Inhibit";
BA_ "VNSigAllNodes" SG_ 761 ABFI_CollPrepSysInhbt 1;
BA_ "SignalType" SG_ 761 ABFI_RrVirtlBmprInh "BLN";
BA_ "PacketOrder" SG_ 761 ABFI_RrVirtlBmprInh 1;
BA_ "SignalLongName" SG_ 761 ABFI_RrVirtlBmprInh "Automatic Braking Feature Inhibit : Rear Virtual Bumper Inhibit";
BA_ "VNSigAllNodes" SG_ 761 ABFI_RrVirtlBmprInh 1;
BA_ "SignalType" SG_ 761 BrkPdlDrvApplPresV "ENM";
BA_ "SignalLongName" SG_ 761 BrkPdlDrvApplPresV "Brake Pedal Driver Applied Pressure Validity";
BA_ "VNSigAllNodes" SG_ 761 BrkPdlDrvApplPresV 1;
BA_ "SignalType" SG_ 761 BrkPdlDrvApplPres "UNM";
BA_ "SignalLongName" SG_ 761 BrkPdlDrvApplPres "Brake Pedal Driver Applied Pressure";
BA_ "VNSigAllNodes" SG_ 761 BrkPdlDrvApplPres 1;
BA_ "SignalType" SG_ 761 AutoBrkPTReqStat "ENM";
BA_ "SignalLongName" SG_ 761 AutoBrkPTReqStat "Automatic Braking Powertrain Request Status";
BA_ "VNSigAllNodes" SG_ 761 AutoBrkPTReqStat 1;
BA_ "SignalType" SG_ 761 WhlSpdSnsgDTCIndex "UNM";
BA_ "PacketOrder" SG_ 761 WhlSpdSnsgDTCIndex 1;
BA_ "SignalLongName" SG_ 761 WhlSpdSnsgDTCIndex "Wheel Speed Sensing Legislated Diagnostic Status : Diagnostic Trouble Code Index";
BA_ "VNSigAllNodes" SG_ 761 WhlSpdSnsgDTCIndex 1;
BA_ "SignalType" SG_ 761 WhlSpdSnsgDTCStat "ENM";
BA_ "PacketOrder" SG_ 761 WhlSpdSnsgDTCStat 2;
BA_ "SignalLongName" SG_ 761 WhlSpdSnsgDTCStat "Wheel Speed Sensing Legislated Diagnostic Status : Diagnostic Trouble Code Status";
BA_ "VNSigAllNodes" SG_ 761 WhlSpdSnsgDTCStat 1;
BA_ "SignalType" SG_ 761 SprTireSt "ENM";
BA_ "SignalLongName" SG_ 761 SprTireSt "Spare Tire Status";
BA_ "VNSigAllNodes" SG_ 761 SprTireSt 1;
BA_ "SignalType" SG_ 489 EnhDrvMdSwChUseRq "BLN";
BA_ "SignalLongName" SG_ 489 EnhDrvMdSwChUseRq "Enhanced Driver Selected Mode Switch Chassis Use Requested";
BA_ "VNSigAllNodes" SG_ 489 EnhDrvMdSwChUseRq 1;
BA_ "SignalType" SG_ 489 IMUDataMsk "BLN";
BA_ "SignalLongName" SG_ 489 IMUDataMsk "Inertial Measurement Unit Data Mask";
BA_ "VNSigAllNodes" SG_ 489 IMUDataMsk 1;
BA_ "SignalType" SG_ 489 DrvIndpntBrkAppAct "BLN";
BA_ "SignalLongName" SG_ 489 DrvIndpntBrkAppAct "Driver Independent Brake Apply Active";
BA_ "VNSigAllNodes" SG_ 489 DrvIndpntBrkAppAct 1;
BA_ "SignalType" SG_ 489 WhlSlpSt "ENM";
BA_ "SignalLongName" SG_ 489 WhlSlpSt "Wheel Slip Status";
BA_ "VNSigAllNodes" SG_ 489 WhlSlpSt 1;
BA_ "SignalType" SG_ 489 BSTGRReqdGear "ENM";
BA_ "PacketOrder" SG_ 489 BSTGRReqdGear 2;
BA_ "SignalLongName" SG_ 489 BSTGRReqdGear "Brake System Transmission Gear Request : Requested Gear";
BA_ "VNSigAllNodes" SG_ 489 BSTGRReqdGear 1;
BA_ "SignalType" SG_ 489 BSTGRReqType "ENM";
BA_ "PacketOrder" SG_ 489 BSTGRReqType 1;
BA_ "SignalLongName" SG_ 489 BSTGRReqType "Brake System Transmission Gear Request : Request Type";
BA_ "VNSigAllNodes" SG_ 489 BSTGRReqType 1;
BA_ "SignalType" SG_ 489 VehDynOvrUndrStr "SNM";
BA_ "SignalLongName" SG_ 489 VehDynOvrUndrStr "Vehicle Dynamics Over Under Steer";
BA_ "VNSigAllNodes" SG_ 489 VehDynOvrUndrStr 1;
BA_ "SignalType" SG_ 489 VSELatAccV "ENM";
BA_ "SignalLongName" SG_ 489 VSELatAccV "Vehicle Stability Enhancement Lateral Acceleration Validity";
BA_ "VNSigAllNodes" SG_ 489 VSELatAccV 1;
BA_ "SignalType" SG_ 489 VSELatAcc "SNM";
BA_ "SignalLongName" SG_ 489 VSELatAcc "Vehicle Stability Enhancement Lateral Acceleration";
BA_ "VNSigAllNodes" SG_ 489 VSELatAcc 1;
BA_ "SignalType" SG_ 489 VSEAct "BLN";
BA_ "SignalLongName" SG_ 489 VSEAct "Vehicle Stability Enhancement System Active";
BA_ "VNSigAllNodes" SG_ 489 VSEAct 1;
BA_ "SignalType" SG_ 489 VhDynCntlSysSt "ENM";
BA_ "SignalLongName" SG_ 489 VhDynCntlSysSt "Vehicle Dynamics Control System Status";
BA_ "VNSigAllNodes" SG_ 489 VhDynCntlSysSt 1;
BA_ "SignalType" SG_ 489 VehDynYawRateV "ENM";
BA_ "SignalLongName" SG_ 489 VehDynYawRateV "Vehicle Dynamics Yaw Rate Validity";
BA_ "VNSigAllNodes" SG_ 489 VehDynYawRateV 1;
BA_ "SignalType" SG_ 489 VehDynYawRate "SNM";
BA_ "SignalLongName" SG_ 489 VehDynYawRate "Vehicle Dynamics Yaw Rate";
BA_ "VNSigAllNodes" SG_ 489 VehDynYawRate 1;
BA_ "SignalType" SG_ 489 TrnsBrkSysCltchRelRqd "BLN";
BA_ "SignalLongName" SG_ 489 TrnsBrkSysCltchRelRqd "Transmission Brake System Clutch Release Requested";
BA_ "VNSigAllNodes" SG_ 489 TrnsBrkSysCltchRelRqd 1;
BA_ "SignalType" SG_ 489 TracCntrlSysDrIntnt "ENM";
BA_ "SignalLongName" SG_ 489 TracCntrlSysDrIntnt "Traction Control System Driver Intent";
BA_ "VNSigAllNodes" SG_ 489 TracCntrlSysDrIntnt 1;
BA_ "SignalType" SG_ 489 VehDynOvrUndrStrV "ENM";
BA_ "SignalLongName" SG_ 489 VehDynOvrUndrStrV "Vehicle Dynamics Over Under Steer Validity";
BA_ "VNSigAllNodes" SG_ 489 VehDynOvrUndrStrV 1;
BA_ "SignalType" SG_ 489 TCSysEnbld "BLN";
BA_ "SignalLongName" SG_ 489 TCSysEnbld "Traction Control System Enabled";
BA_ "VNSigAllNodes" SG_ 489 TCSysEnbld 1;
BA_ "SignalType" SG_ 489 TCSysAtv "BLN";
BA_ "SignalLongName" SG_ 489 TCSysAtv "Traction Control System Active";
BA_ "VNSigAllNodes" SG_ 489 TCSysAtv 1;
BA_ "SignalType" SG_ 489 BrkPdlDrvAppPrsDetcdV "ENM";
BA_ "SignalLongName" SG_ 489 BrkPdlDrvAppPrsDetcdV "Brake Pedal Driver Applied Pressure Detected Validity";
BA_ "VNSigAllNodes" SG_ 489 BrkPdlDrvAppPrsDetcdV 1;
BA_ "SignalType" SG_ 489 BrkPdlDrvAppPrsDetcd "BLN";
BA_ "SignalLongName" SG_ 489 BrkPdlDrvAppPrsDetcd "Brake Pedal Driver Applied Pressure Detected";
BA_ "GenSigStartValue" SG_ 489 BrkPdlDrvAppPrsDetcd 1;
BA_ "VNSigAllNodes" SG_ 489 BrkPdlDrvAppPrsDetcd 1;
BA_ "SignalType" SG_ 489 ACCBrkngAct "BLN";
BA_ "SignalLongName" SG_ 489 ACCBrkngAct "Adaptive Cruise Control Braking Active";
BA_ "VNSigAllNodes" SG_ 489 ACCBrkngAct 1;
BA_ "SignalType" SG_ 489 ABSFld "BLN";
BA_ "SignalLongName" SG_ 489 ABSFld "Antilock Brake System Failed";
BA_ "VNSigAllNodes" SG_ 489 ABSFld 1;
BA_ "SignalType" SG_ 489 ABSAtv "BLN";
BA_ "SignalLongName" SG_ 489 ABSAtv "Antilock Brake System Active";
BA_ "VNSigAllNodes" SG_ 489 ABSAtv 1;
BA_ "SignalType" SG_ 381 HillDesCtrlRedVehSpIO "BLN";
BA_ "SignalLongName" SG_ 381 HillDesCtrlRedVehSpIO "Hill Descent Control Reduce Vehicle Speed Indication On";
BA_ "VNSigAllNodes" SG_ 381 HillDesCtrlRedVehSpIO 1;
BA_ "SignalType" SG_ 381 EBDFailed "BLN";
BA_ "SignalLongName" SG_ 381 EBDFailed "Electronic Brake Distribution Failed";
BA_ "VNSigAllNodes" SG_ 381 EBDFailed 1;
BA_ "SignalType" SG_ 381 StWhAnVDA "ENM";
BA_ "SignalLongName" SG_ 381 StWhAnVDA "Steering Wheel Angle Virtual Device Availability";
BA_ "GenSigStartValue" SG_ 381 StWhAnVDA 1;
BA_ "VNSigAllNodes" SG_ 381 StWhAnVDA 1;
BA_ "SignalType" SG_ 381 TirePrsLowIO "BLN";
BA_ "SignalLongName" SG_ 381 TirePrsLowIO "Tire Pressure Low Indication On";
BA_ "VNSigAllNodes" SG_ 381 TirePrsLowIO 1;
BA_ "SignalType" SG_ 381 VaccBoostFailure "BLN";
BA_ "SignalLongName" SG_ 381 VaccBoostFailure "Vaccum Boost Failure";
BA_ "VNSigAllNodes" SG_ 381 VaccBoostFailure 1;
BA_ "SignalType" SG_ 381 VSESysPrs "BLN";
BA_ "SignalLongName" SG_ 381 VSESysPrs "Vehicle Stability Enhancement System Present";
BA_ "VNSigAllNodes" SG_ 381 VSESysPrs 1;
BA_ "SignalType" SG_ 381 HalfSysFail "BLN";
BA_ "SignalLongName" SG_ 381 HalfSysFail "Half System Failure";
BA_ "VNSigAllNodes" SG_ 381 HalfSysFail 1;
BA_ "SignalType" SG_ 381 ActVehAccel "SNM";
BA_ "SignalLongName" SG_ 381 ActVehAccel "Actual Vehicle Acceleration";
BA_ "VNSigAllNodes" SG_ 381 ActVehAccel 1;
BA_ "SignalType" SG_ 381 ActVehAccelV "ENM";
BA_ "SignalLongName" SG_ 381 ActVehAccelV "Actual Vehicle Acceleration Validity";
BA_ "VNSigAllNodes" SG_ 381 ActVehAccelV 1;
BA_ "SignalType" SG_ 381 BksOvht "BLN";
BA_ "SignalLongName" SG_ 381 BksOvht "Brakes Overheated";
BA_ "VNSigAllNodes" SG_ 381 BksOvht 1;
BA_ "SignalType" SG_ 381 TCSysPr "BLN";
BA_ "SignalLongName" SG_ 381 TCSysPr "Traction Control System Present";
BA_ "VNSigAllNodes" SG_ 381 TCSysPr 1;
BA_ "SignalType" SG_ 381 ABSPr "BLN";
BA_ "SignalLongName" SG_ 381 ABSPr "Antilock Brake System Present";
BA_ "VNSigAllNodes" SG_ 381 ABSPr 1;
BA_ "SignalType" SG_ 381 TreInfMonSysRstPrfmd "BLN";
BA_ "SignalLongName" SG_ 381 TreInfMonSysRstPrfmd "Tire Inflation Monitoring System Reset Performed";
BA_ "VNSigAllNodes" SG_ 381 TreInfMonSysRstPrfmd 1;
BA_ "SignalType" SG_ 381 ABSIO "BLN";
BA_ "SignalLongName" SG_ 381 ABSIO "Antilock Brake System Indication On";
BA_ "VNSigAllNodes" SG_ 381 ABSIO 1;
BA_ "SignalType" SG_ 381 BrkPadWrnIO "BLN";
BA_ "SignalLongName" SG_ 381 BrkPadWrnIO "Brake Pad Worn Indication On";
BA_ "VNSigAllNodes" SG_ 381 BrkPadWrnIO 1;
BA_ "SignalType" SG_ 381 VehStabEnhmntMd "ENM";
BA_ "SignalLongName" SG_ 381 VehStabEnhmntMd "Vehicle Stability Enhancement Mode";
BA_ "VNSigAllNodes" SG_ 381 VehStabEnhmntMd 1;
BA_ "SignalType" SG_ 381 VehStabEnhmntStat "ENM";
BA_ "SignalLongName" SG_ 381 VehStabEnhmntStat "Vehicle Stability Enhancement Status";
BA_ "VNSigAllNodes" SG_ 381 VehStabEnhmntStat 1;
BA_ "SignalType" SG_ 381 TCSysOpMd "ENM";
BA_ "SignalLongName" SG_ 381 TCSysOpMd "Traction Control System Operating Mode";
BA_ "VNSigAllNodes" SG_ 381 TCSysOpMd 1;
BA_ "SignalType" SG_ 381 TCSysOpStat "ENM";
BA_ "SignalLongName" SG_ 381 TCSysOpStat "Traction Control System Operating Status";
BA_ "VNSigAllNodes" SG_ 381 TCSysOpStat 1;
BA_ "SignalType" SG_ 381 BrkSysVTopSpdLimVal "UNM";
BA_ "SignalLongName" SG_ 381 BrkSysVTopSpdLimVal "Braking System Vehicle Top Speed Limit Value";
BA_ "GenSigStartValue" SG_ 381 BrkSysVTopSpdLimVal 255;
BA_ "VNSigAllNodes" SG_ 381 BrkSysVTopSpdLimVal 1;
BA_ "SignalType" SG_ 381 BrkSysRedBrkTlltlReq "BLN";
BA_ "SignalLongName" SG_ 381 BrkSysRedBrkTlltlReq "Brake System Red Brake Telltale Request";
BA_ "VNSigAllNodes" SG_ 381 BrkSysRedBrkTlltlReq 1;
BA_ "SignalType" SG_ 381 BrkSysBrkLtsReqd "BLN";
BA_ "SignalLongName" SG_ 381 BrkSysBrkLtsReqd "Brake System Brake Lights Requested";
BA_ "VNSigAllNodes" SG_ 381 BrkSysBrkLtsReqd 1;
BA_ "SignalType" SG_ 241 NotEventStat "ENM";
BA_ "SignalLongName" SG_ 241 NotEventStat "Notification Event Status";
BA_ "VNSigAllNodes" SG_ 241 NotEventStat 1;
BA_ "SignalType" SG_ 241 BrkPdlChkData "UNM";
BA_ "SignalLongName" SG_ 241 BrkPdlChkData "Brake Pedal Check Data";
BA_ "VNSigAllNodes" SG_ 241 BrkPdlChkData 1;
BA_ "SignalType" SG_ 241 BrkAppSnsrHmPosLrnd "BLN";
BA_ "SignalLongName" SG_ 241 BrkAppSnsrHmPosLrnd "Brake Apply Sensor Home Position Learned";
BA_ "VNSigAllNodes" SG_ 241 BrkAppSnsrHmPosLrnd 1;
BA_ "SignalType" SG_ 241 BrkPedTrvlAchvd "BLN";
BA_ "PacketOrder" SG_ 241 BrkPedTrvlAchvd 1;
BA_ "SignalLongName" SG_ 241 BrkPedTrvlAchvd "Brake Pedal Initial Travel Achieved Status : Brake Pedal Initial Travel Achieved";
BA_ "VNSigAllNodes" SG_ 241 BrkPedTrvlAchvd 1;
BA_ "SignalType" SG_ 241 BrkPedTrvlAchvdV "ENM";
BA_ "PacketOrder" SG_ 241 BrkPedTrvlAchvdV 2;
BA_ "SignalLongName" SG_ 241 BrkPedTrvlAchvdV "Brake Pedal Initial Travel Achieved Status : Brake Pedal Initial Travel Achieved Validity";
BA_ "VNSigAllNodes" SG_ 241 BrkPedTrvlAchvdV 1;
BA_ "SignalType" SG_ 241 BrkPdlPosGrad "SNM";
BA_ "SignalLongName" SG_ 241 BrkPdlPosGrad "Brake Pedal Position Gradient";
BA_ "VNSigAllNodes" SG_ 241 BrkPdlPosGrad 1;
BA_ "SignalType" SG_ 241 BrkPdlPos "UNM";
BA_ "SignalLongName" SG_ 241 BrkPdlPos "Brake Pedal Position";
BA_ "VNSigAllNodes" SG_ 241 BrkPdlPos 1;
BA_ "SignalType" SG_ 241 BrkPedPosAlvRolngCnt "UNM";
BA_ "SignalLongName" SG_ 241 BrkPedPosAlvRolngCnt "Brake Pedal Position Alive Rolling Count";
BA_ "VNSigAllNodes" SG_ 241 BrkPedPosAlvRolngCnt 1;
BA_ "SignalType" SG_ 241 BrkPdlModTrvlV "ENM";
BA_ "SignalLongName" SG_ 241 BrkPdlModTrvlV "Brake Pedal Moderate Travel Achieved Validity";
BA_ "VNSigAllNodes" SG_ 241 BrkPdlModTrvlV 1;
BA_ "SignalType" SG_ 241 BrkPdlModTrvl "BLN";
BA_ "SignalLongName" SG_ 241 BrkPdlModTrvl "Brake Pedal Moderate Travel Achieved";
BA_ "VNSigAllNodes" SG_ 241 BrkPdlModTrvl 1;
BA_ "SignalType" SG_ 241 BrkPdlInTrvPrt "UNM";
BA_ "SignalLongName" SG_ 241 BrkPdlInTrvPrt "Brake Pedal Initial Travel Achieved Protection";
BA_ "VNSigAllNodes" SG_ 241 BrkPdlInTrvPrt 1;
BA_ "VNSigSLHSSharedDiagnostic" SG_ 2025 DgnInf 1;
BA_ "SignalType" SG_ 2025 DgnInf "UNM";
BA_ "SignalLongName" SG_ 2025 DgnInf "Diagnostic Information";
BA_ "VNSigAllNodes" SG_ 2025 DgnInf 1;
BA_ "VNSigSLHSSharedDiagnostic" SG_ 2029 DgnInf 1;
BA_ "SignalType" SG_ 2029 DgnInf "UNM";
BA_ "SignalLongName" SG_ 2029 DgnInf "Diagnostic Information";
BA_ "VNSigAllNodes" SG_ 2029 DgnInf 1;
BA_ "VNSigSLHSSharedDiagnostic" SG_ 2031 DgnInf 1;
BA_ "SignalType" SG_ 2031 DgnInf "UNM";
BA_ "SignalLongName" SG_ 2031 DgnInf "Diagnostic Information";
BA_ "VNSigAllNodes" SG_ 2031 DgnInf 1;
BA_ "VNSigSLHSSharedDiagnostic" SG_ 1513 DgnInf 1;
BA_ "SignalType" SG_ 1513 DgnInf "UNM";
BA_ "SignalLongName" SG_ 1513 DgnInf "Diagnostic Information";
BA_ "VNSigAllNodes" SG_ 1513 DgnInf 1;
BA_ "VNSigSLHSSharedDiagnostic" SG_ 1517 DgnInf 1;
BA_ "SignalType" SG_ 1517 DgnInf "UNM";
BA_ "SignalLongName" SG_ 1517 DgnInf "Diagnostic Information";
BA_ "VNSigAllNodes" SG_ 1517 DgnInf 1;
BA_ "VNSigSLHSSharedDiagnostic" SG_ 1519 DgnInf 1;
BA_ "SignalType" SG_ 1519 DgnInf "UNM";
BA_ "SignalLongName" SG_ 1519 DgnInf "Diagnostic Information";
BA_ "VNSigAllNodes" SG_ 1519 DgnInf 1;
BA_ "VNSigSLHSSharedDiagnostic" SG_ 2030 DgnInf 1;
BA_ "SignalType" SG_ 2030 DgnInf "UNM";
BA_ "SignalLongName" SG_ 2030 DgnInf "Diagnostic Information";
BA_ "VNSigAllNodes" SG_ 2030 DgnInf 1;
BA_ "VNSigSLHSSharedDiagnostic" SG_ 1518 DgnInf 1;
BA_ "SignalType" SG_ 1518 DgnInf "UNM";
BA_ "SignalLongName" SG_ 1518 DgnInf "Diagnostic Information";
BA_ "VNSigAllNodes" SG_ 1518 DgnInf 1;
BA_ "VNSigSLHSSharedDiagnostic" SG_ 1346 DgnInf_HS542 1;
BA_ "SignalType" SG_ 1346 DgnInf_HS542 "UNM";
BA_ "SignalLongName" SG_ 1346 DgnInf_HS542 "Diagnostic Information HS542";
BA_ "VNSigAllNodes" SG_ 1346 DgnInf_HS542 1;
BA_ "VNSigSLHSSharedDiagnostic" SG_ 1353 DgnInf_HS549 1;
BA_ "SignalType" SG_ 1353 DgnInf_HS549 "UNM";
BA_ "SignalLongName" SG_ 1353 DgnInf_HS549 "Diagnostic Information HS549";
BA_ "VNSigAllNodes" SG_ 1353 DgnInf_HS549 1;
BA_ "VNSigSLHSSharedDiagnostic" SG_ 1609 DgnInf 1;
BA_ "SignalType" SG_ 1609 DgnInf "UNM";
BA_ "SignalLongName" SG_ 1609 DgnInf "Diagnostic Information";
BA_ "VNSigAllNodes" SG_ 1609 DgnInf 1;
BA_ "VNSigSLHSSharedDiagnostic" SG_ 1602 DgnInf 1;
BA_ "SignalType" SG_ 1602 DgnInf "UNM";
BA_ "SignalLongName" SG_ 1602 DgnInf "Diagnostic Information";
BA_ "VNSigAllNodes" SG_ 1602 DgnInf 1;
BA_ "VNSigSLHSSharedDiagnostic" SG_ 2027 DgnInf 1;
BA_ "SignalType" SG_ 2027 DgnInf "UNM";
BA_ "SignalLongName" SG_ 2027 DgnInf "Diagnostic Information";
BA_ "VNSigAllNodes" SG_ 2027 DgnInf 1;
BA_ "VNSigSLHSSharedDiagnostic" SG_ 1515 DgnInf 1;
BA_ "SignalType" SG_ 1515 DgnInf "UNM";
BA_ "SignalLongName" SG_ 1515 DgnInf "Diagnostic Information";
BA_ "VNSigAllNodes" SG_ 1515 DgnInf 1;
BA_ "VNSigSLHSSharedDiagnostic" SG_ 1614 DgnInf 1;
BA_ "SignalType" SG_ 1614 DgnInf "UNM";
BA_ "SignalLongName" SG_ 1614 DgnInf "Diagnostic Information";
BA_ "VNSigAllNodes" SG_ 1614 DgnInf 1;
BA_ "VNSigSLHSSharedDiagnostic" SG_ 1348 DgnInf_HS544 1;
BA_ "SignalType" SG_ 1348 DgnInf_HS544 "UNM";
BA_ "SignalLongName" SG_ 1348 DgnInf_HS544 "Diagnostic Information HS544";
BA_ "VNSigAllNodes" SG_ 1348 DgnInf_HS544 1;
BA_ "VNSigSLHSSharedDiagnostic" SG_ 1349 DgnInf_HS545 1;
BA_ "SignalType" SG_ 1349 DgnInf_HS545 "UNM";
BA_ "SignalLongName" SG_ 1349 DgnInf_HS545 "Diagnostic Information HS545";
BA_ "VNSigAllNodes" SG_ 1349 DgnInf_HS545 1;
BA_ "VNSigSLHSSharedDiagnostic" SG_ 1352 DgnInf_HS548 1;
BA_ "SignalType" SG_ 1352 DgnInf_HS548 "UNM";
BA_ "SignalLongName" SG_ 1352 DgnInf_HS548 "Diagnostic Information HS548";
BA_ "VNSigAllNodes" SG_ 1352 DgnInf_HS548 1;
BA_ "VNSigSLHSSharedDiagnostic" SG_ 1354 DgnInf_HS54A 1;
BA_ "SignalType" SG_ 1354 DgnInf_HS54A "UNM";
BA_ "SignalLongName" SG_ 1354 DgnInf_HS54A "Diagnostic Information HS54A";
BA_ "VNSigAllNodes" SG_ 1354 DgnInf_HS54A 1;
BA_ "VNSigSLHSSharedDiagnostic" SG_ 1605 DgnInf 1;
BA_ "SignalType" SG_ 1605 DgnInf "UNM";
BA_ "SignalLongName" SG_ 1605 DgnInf "Diagnostic Information";
BA_ "VNSigAllNodes" SG_ 1605 DgnInf 1;
BA_ "VNSigSLHSSharedDiagnostic" SG_ 1620 DgnInf 1;
BA_ "SignalType" SG_ 1620 DgnInf "UNM";
BA_ "SignalLongName" SG_ 1620 DgnInf "Diagnostic Information";
BA_ "VNSigAllNodes" SG_ 1620 DgnInf 1;
BA_ "VNSigSLHSSharedDiagnostic" SG_ 1604 DgnInf 1;
BA_ "SignalType" SG_ 1604 DgnInf "UNM";
BA_ "SignalLongName" SG_ 1604 DgnInf "Diagnostic Information";
BA_ "VNSigAllNodes" SG_ 1604 DgnInf 1;
BA_ "VNSigSLHSSharedDiagnostic" SG_ 1612 DgnInf 1;
BA_ "SignalType" SG_ 1612 DgnInf "UNM";
BA_ "SignalLongName" SG_ 1612 DgnInf "Diagnostic Information";
BA_ "VNSigAllNodes" SG_ 1612 DgnInf 1;
BA_ "VNSigSLHSSharedDiagnostic" SG_ 1615 DgnInf 1;
BA_ "SignalType" SG_ 1615 DgnInf "UNM";
BA_ "SignalLongName" SG_ 1615 DgnInf "Diagnostic Information";
BA_ "VNSigAllNodes" SG_ 1615 DgnInf 1;
BA_REL_ "GenSigSuprvResp" BU_SG_REL_ ECM_HS SG_ 497 ElvtdIdlCstStReq 1;
BA_REL_ "GenSigTimeoutMsg" BU_SG_REL_ ECM_HS SG_ 497 ElvtdIdlCstStReq 497;
BA_REL_ "GenSigTimeoutTime" BU_SG_REL_ ECM_HS SG_ 497 ElvtdIdlCstStReq 250;
BA_REL_ "GenSigSuprvResp" BU_SG_REL_ EBCM_OBD_HS SG_ 497 BkupPwrModeMstrVDA 2;
BA_REL_ "GenSigTimeoutMsg" BU_SG_REL_ EBCM_OBD_HS SG_ 497 BkupPwrModeMstrVDA 497;
BA_REL_ "GenSigTimeoutTime" BU_SG_REL_ EBCM_OBD_HS SG_ 497 BkupPwrModeMstrVDA 250;
BA_REL_ "GenSigSuprvResp" BU_SG_REL_ EBCM_HS SG_ 497 BkupPwrModeMstrVDA 2;
BA_REL_ "GenSigTimeoutMsg" BU_SG_REL_ EBCM_HS SG_ 497 BkupPwrModeMstrVDA 497;
BA_REL_ "GenSigTimeoutTime" BU_SG_REL_ EBCM_HS SG_ 497 BkupPwrModeMstrVDA 250;
BA_REL_ "GenSigRxStartValue" BU_SG_REL_ BCP_HS SG_ 497 AirbgVDA "$1 - Virtual Device Available";
BA_REL_ "GenSigVDAFailComment" BU_SG_REL_ APPS_HS SG_ 497 SysBkupPwrMdEn "Backup Power Mode Master Virtual Device Availability";
BA_REL_ "GenSigVDAFailResp" BU_SG_REL_ APPS_HS SG_ 497 SysBkupPwrMdEn 1;
BA_REL_ "GenSigSuprvResp" BU_SG_REL_ APPS_HS SG_ 497 SysBkupPwrMdEn 1;
BA_REL_ "GenSigTimeoutMsg" BU_SG_REL_ APPS_HS SG_ 497 SysBkupPwrMdEn 497;
BA_REL_ "GenSigTimeoutTime" BU_SG_REL_ APPS_HS SG_ 497 SysBkupPwrMdEn 250;
BA_REL_ "GenSigVDAFailComment" BU_SG_REL_ EPB_HS SG_ 497 SysBkupPwrMdEn "Backup Power Mode Master Virtual Device Availability";
BA_REL_ "GenSigVDAFailResp" BU_SG_REL_ EPB_HS SG_ 497 SysBkupPwrMdEn 1;
BA_REL_ "GenSigSuprvResp" BU_SG_REL_ EPB_HS SG_ 497 SysBkupPwrMdEn 1;
BA_REL_ "GenSigTimeoutMsg" BU_SG_REL_ EPB_HS SG_ 497 SysBkupPwrMdEn 497;
BA_REL_ "GenSigTimeoutTime" BU_SG_REL_ EPB_HS SG_ 497 SysBkupPwrMdEn 250;
BA_REL_ "GenSigSuprvResp" BU_SG_REL_ APPS_HS SG_ 497 SysBkUpPwrMd 1;
BA_REL_ "GenSigTimeoutMsg" BU_SG_REL_ APPS_HS SG_ 497 SysBkUpPwrMd 497;
BA_REL_ "GenSigTimeoutTime" BU_SG_REL_ APPS_HS SG_ 497 SysBkUpPwrMd 250;
BA_REL_ "GenSigSuprvResp" BU_SG_REL_ EPB_HS SG_ 497 SysBkUpPwrMd 1;
BA_REL_ "GenSigTimeoutMsg" BU_SG_REL_ EPB_HS SG_ 497 SysBkUpPwrMd 497;
BA_REL_ "GenSigTimeoutTime" BU_SG_REL_ EPB_HS SG_ 497 SysBkUpPwrMd 250;
BA_REL_ "GenSigSuprvResp" BU_SG_REL_ BSM_HS SG_ 497 SysPwrMd 1;
BA_REL_ "GenSigTimeoutMsg" BU_SG_REL_ BSM_HS SG_ 497 SysPwrMd 497;
BA_REL_ "GenSigTimeoutTime" BU_SG_REL_ BSM_HS SG_ 497 SysPwrMd 250;
BA_REL_ "GenSigSuprvResp" BU_SG_REL_ VICM2_HS SG_ 497 SysPwrMd 1;
BA_REL_ "GenSigTimeoutMsg" BU_SG_REL_ VICM2_HS SG_ 497 SysPwrMd 497;
BA_REL_ "GenSigTimeoutTime" BU_SG_REL_ VICM2_HS SG_ 497 SysPwrMd 250;
BA_REL_ "GenSigSuprvResp" BU_SG_REL_ VICM_HS SG_ 497 SysPwrMd 1;
BA_REL_ "GenSigTimeoutMsg" BU_SG_REL_ VICM_HS SG_ 497 SysPwrMd 497;
BA_REL_ "GenSigTimeoutTime" BU_SG_REL_ VICM_HS SG_ 497 SysPwrMd 250;
BA_REL_ "GenSigSuprvResp" BU_SG_REL_ EBOOST_HS SG_ 497 SysPwrMd 1;
BA_REL_ "GenSigTimeoutMsg" BU_SG_REL_ EBOOST_HS SG_ 497 SysPwrMd 497;
BA_REL_ "GenSigTimeoutTime" BU_SG_REL_ EBOOST_HS SG_ 497 SysPwrMd 250;
BA_REL_ "GenSigSuprvResp" BU_SG_REL_ HCP_B_HS SG_ 497 SysPwrMd 1;
BA_REL_ "GenSigTimeoutMsg" BU_SG_REL_ HCP_B_HS SG_ 497 SysPwrMd 497;
BA_REL_ "GenSigTimeoutTime" BU_SG_REL_ HCP_B_HS SG_ 497 SysPwrMd 250;
BA_REL_ "GenSigSuprvResp" BU_SG_REL_ AVM_HS SG_ 497 SysPwrMd 1;
BA_REL_ "GenSigTimeoutMsg" BU_SG_REL_ AVM_HS SG_ 497 SysPwrMd 497;
BA_REL_ "GenSigTimeoutTime" BU_SG_REL_ AVM_HS SG_ 497 SysPwrMd 250;
BA_REL_ "GenSigSuprvResp" BU_SG_REL_ PFAF_HS SG_ 497 SysPwrMd 1;
BA_REL_ "GenSigTimeoutMsg" BU_SG_REL_ PFAF_HS SG_ 497 SysPwrMd 497;
BA_REL_ "GenSigTimeoutTime" BU_SG_REL_ PFAF_HS SG_ 497 SysPwrMd 250;
BA_REL_ "GenSigSuprvResp" BU_SG_REL_ DCDC_HS SG_ 497 SysPwrMd 1;
BA_REL_ "GenSigTimeoutMsg" BU_SG_REL_ DCDC_HS SG_ 497 SysPwrMd 497;
BA_REL_ "GenSigTimeoutTime" BU_SG_REL_ DCDC_HS SG_ 497 SysPwrMd 250;
BA_REL_ "GenSigSuprvResp" BU_SG_REL_ TRCM_HS SG_ 497 SysPwrMd 1;
BA_REL_ "GenSigTimeoutMsg" BU_SG_REL_ TRCM_HS SG_ 497 SysPwrMd 497;
BA_REL_ "GenSigTimeoutTime" BU_SG_REL_ TRCM_HS SG_ 497 SysPwrMd 250;
BA_REL_ "GenSigSuprvResp" BU_SG_REL_ FICM_HS SG_ 497 SysPwrMd 1;
BA_REL_ "GenSigTimeoutMsg" BU_SG_REL_ FICM_HS SG_ 497 SysPwrMd 497;
BA_REL_ "GenSigTimeoutTime" BU_SG_REL_ FICM_HS SG_ 497 SysPwrMd 250;
BA_REL_ "GenSigSuprvResp" BU_SG_REL_ ARS_HS SG_ 497 SysPwrMd 1;
BA_REL_ "GenSigTimeoutMsg" BU_SG_REL_ ARS_HS SG_ 497 SysPwrMd 497;
BA_REL_ "GenSigTimeoutTime" BU_SG_REL_ ARS_HS SG_ 497 SysPwrMd 250;
BA_REL_ "GenSigSuprvResp" BU_SG_REL_ ICCM_OBD_HS SG_ 497 SysPwrMd 1;
BA_REL_ "GenSigTimeoutMsg" BU_SG_REL_ ICCM_OBD_HS SG_ 497 SysPwrMd 497;
BA_REL_ "GenSigTimeoutTime" BU_SG_REL_ ICCM_OBD_HS SG_ 497 SysPwrMd 250;
BA_REL_ "GenSigSuprvResp" BU_SG_REL_ SAS_HS SG_ 497 SysPwrMd 1;
BA_REL_ "GenSigTimeoutMsg" BU_SG_REL_ SAS_HS SG_ 497 SysPwrMd 497;
BA_REL_ "GenSigTimeoutTime" BU_SG_REL_ SAS_HS SG_ 497 SysPwrMd 250;
BA_REL_ "GenSigSuprvResp" BU_SG_REL_ VLBS_HS SG_ 497 SysPwrMd 1;
BA_REL_ "GenSigTimeoutMsg" BU_SG_REL_ VLBS_HS SG_ 497 SysPwrMd 497;
BA_REL_ "GenSigTimeoutTime" BU_SG_REL_ VLBS_HS SG_ 497 SysPwrMd 250;
BA_REL_ "GenSigSuprvResp" BU_SG_REL_ HCP_T_HS SG_ 497 SysPwrMd 1;
BA_REL_ "GenSigTimeoutMsg" BU_SG_REL_ HCP_T_HS SG_ 497 SysPwrMd 497;
BA_REL_ "GenSigTimeoutTime" BU_SG_REL_ HCP_T_HS SG_ 497 SysPwrMd 250;
BA_REL_ "GenSigSuprvResp" BU_SG_REL_ HCP_HS SG_ 497 SysPwrMd 1;
BA_REL_ "GenSigTimeoutMsg" BU_SG_REL_ HCP_HS SG_ 497 SysPwrMd 497;
BA_REL_ "GenSigTimeoutTime" BU_SG_REL_ HCP_HS SG_ 497 SysPwrMd 250;
BA_REL_ "GenSigSuprvResp" BU_SG_REL_ ICCM_HS SG_ 497 SysPwrMd 1;
BA_REL_ "GenSigTimeoutMsg" BU_SG_REL_ ICCM_HS SG_ 497 SysPwrMd 497;
BA_REL_ "GenSigTimeoutTime" BU_SG_REL_ ICCM_HS SG_ 497 SysPwrMd 250;
BA_REL_ "GenSigSuprvResp" BU_SG_REL_ EOCM_F_HS SG_ 497 SysPwrMd 1;
BA_REL_ "GenSigTimeoutMsg" BU_SG_REL_ EOCM_F_HS SG_ 497 SysPwrMd 497;
BA_REL_ "GenSigTimeoutTime" BU_SG_REL_ EOCM_F_HS SG_ 497 SysPwrMd 250;
BA_REL_ "GenSigSuprvResp" BU_SG_REL_ VCM_HS SG_ 497 SysPwrMd 1;
BA_REL_ "GenSigTimeoutMsg" BU_SG_REL_ VCM_HS SG_ 497 SysPwrMd 497;
BA_REL_ "GenSigTimeoutTime" BU_SG_REL_ VCM_HS SG_ 497 SysPwrMd 250;
BA_REL_ "GenSigSuprvResp" BU_SG_REL_ HMIM_HS SG_ 497 SysPwrMd 1;
BA_REL_ "GenSigTimeoutMsg" BU_SG_REL_ HMIM_HS SG_ 497 SysPwrMd 497;
BA_REL_ "GenSigTimeoutTime" BU_SG_REL_ HMIM_HS SG_ 497 SysPwrMd 250;
BA_REL_ "GenSigSuprvResp" BU_SG_REL_ VES_HS SG_ 497 SysPwrMd 1;
BA_REL_ "GenSigTimeoutMsg" BU_SG_REL_ VES_HS SG_ 497 SysPwrMd 497;
BA_REL_ "GenSigTimeoutTime" BU_SG_REL_ VES_HS SG_ 497 SysPwrMd 250;
BA_REL_ "GenSigSuprvResp" BU_SG_REL_ MCP_C_HS SG_ 497 SysPwrMd 1;
BA_REL_ "GenSigTimeoutMsg" BU_SG_REL_ MCP_C_HS SG_ 497 SysPwrMd 497;
BA_REL_ "GenSigTimeoutTime" BU_SG_REL_ MCP_C_HS SG_ 497 SysPwrMd 250;
BA_REL_ "GenSigSuprvResp" BU_SG_REL_ EPS_HS SG_ 497 SysPwrMd 1;
BA_REL_ "GenSigTimeoutMsg" BU_SG_REL_ EPS_HS SG_ 497 SysPwrMd 497;
BA_REL_ "GenSigTimeoutTime" BU_SG_REL_ EPS_HS SG_ 497 SysPwrMd 250;
BA_REL_ "GenSigSuprvResp" BU_SG_REL_ BCP_HS SG_ 497 SysPwrMd 1;
BA_REL_ "GenSigTimeoutMsg" BU_SG_REL_ BCP_HS SG_ 497 SysPwrMd 497;
BA_REL_ "GenSigTimeoutTime" BU_SG_REL_ BCP_HS SG_ 497 SysPwrMd 250;
BA_REL_ "GenSigSuprvResp" BU_SG_REL_ ALC_HS SG_ 497 SysPwrMd 1;
BA_REL_ "GenSigTimeoutMsg" BU_SG_REL_ ALC_HS SG_ 497 SysPwrMd 497;
BA_REL_ "GenSigTimeoutTime" BU_SG_REL_ ALC_HS SG_ 497 SysPwrMd 250;
BA_REL_ "GenSigSuprvResp" BU_SG_REL_ AHL_AFL_HS SG_ 497 SysPwrMd 1;
BA_REL_ "GenSigTimeoutMsg" BU_SG_REL_ AHL_AFL_HS SG_ 497 SysPwrMd 497;
BA_REL_ "GenSigTimeoutTime" BU_SG_REL_ AHL_AFL_HS SG_ 497 SysPwrMd 250;
BA_REL_ "GenSigSuprvResp" BU_SG_REL_ SADS_HS SG_ 497 SysPwrMd 1;
BA_REL_ "GenSigTimeoutMsg" BU_SG_REL_ SADS_HS SG_ 497 SysPwrMd 497;
BA_REL_ "GenSigTimeoutTime" BU_SG_REL_ SADS_HS SG_ 497 SysPwrMd 250;
BA_REL_ "GenSigSuprvResp" BU_SG_REL_ FCM_HS SG_ 497 SysPwrMd 1;
BA_REL_ "GenSigTimeoutMsg" BU_SG_REL_ FCM_HS SG_ 497 SysPwrMd 497;
BA_REL_ "GenSigTimeoutTime" BU_SG_REL_ FCM_HS SG_ 497 SysPwrMd 250;
BA_REL_ "GenSigSuprvResp" BU_SG_REL_ TCCM_HS SG_ 497 SysPwrMd 1;
BA_REL_ "GenSigTimeoutMsg" BU_SG_REL_ TCCM_HS SG_ 497 SysPwrMd 497;
BA_REL_ "GenSigTimeoutTime" BU_SG_REL_ TCCM_HS SG_ 497 SysPwrMd 250;
BA_REL_ "GenSigSuprvResp" BU_SG_REL_ RDCM_HS SG_ 497 SysPwrMd 1;
BA_REL_ "GenSigTimeoutMsg" BU_SG_REL_ RDCM_HS SG_ 497 SysPwrMd 497;
BA_REL_ "GenSigTimeoutTime" BU_SG_REL_ RDCM_HS SG_ 497 SysPwrMd 250;
BA_REL_ "GenSigSuprvResp" BU_SG_REL_ PTO_HS SG_ 497 SysPwrMd 1;
BA_REL_ "GenSigTimeoutMsg" BU_SG_REL_ PTO_HS SG_ 497 SysPwrMd 497;
BA_REL_ "GenSigTimeoutTime" BU_SG_REL_ PTO_HS SG_ 497 SysPwrMd 250;
BA_REL_ "GenSigSuprvResp" BU_SG_REL_ ACC_HS SG_ 497 SysPwrMd 1;
BA_REL_ "GenSigTimeoutMsg" BU_SG_REL_ ACC_HS SG_ 497 SysPwrMd 497;
BA_REL_ "GenSigTimeoutTime" BU_SG_REL_ ACC_HS SG_ 497 SysPwrMd 250;
BA_REL_ "GenSigSuprvResp" BU_SG_REL_ TCM_HS SG_ 497 SysPwrMd 1;
BA_REL_ "GenSigTimeoutMsg" BU_SG_REL_ TCM_HS SG_ 497 SysPwrMd 497;
BA_REL_ "GenSigTimeoutTime" BU_SG_REL_ TCM_HS SG_ 497 SysPwrMd 250;
BA_REL_ "GenSigSuprvResp" BU_SG_REL_ ECM_HS SG_ 497 SysPwrMd 1;
BA_REL_ "GenSigTimeoutMsg" BU_SG_REL_ ECM_HS SG_ 497 SysPwrMd 497;
BA_REL_ "GenSigTimeoutTime" BU_SG_REL_ ECM_HS SG_ 497 SysPwrMd 250;
BA_REL_ "GenSigSuprvResp" BU_SG_REL_ EBCM_OBD_HS SG_ 497 SysPwrMd 1;
BA_REL_ "GenSigTimeoutMsg" BU_SG_REL_ EBCM_OBD_HS SG_ 497 SysPwrMd 497;
BA_REL_ "GenSigTimeoutTime" BU_SG_REL_ EBCM_OBD_HS SG_ 497 SysPwrMd 250;
BA_REL_ "GenSigSuprvResp" BU_SG_REL_ EBCM_OBD_HS SG_ 497 SysPwrMd 1;
BA_REL_ "GenSigTimeoutMsg" BU_SG_REL_ EBCM_OBD_HS SG_ 497 SysPwrMd 497;
BA_REL_ "GenSigTimeoutTime" BU_SG_REL_ EBCM_OBD_HS SG_ 497 SysPwrMd 250;
BA_REL_ "GenSigSuprvResp" BU_SG_REL_ EBCM_HS SG_ 497 SysPwrMd 1;
BA_REL_ "GenSigTimeoutMsg" BU_SG_REL_ EBCM_HS SG_ 497 SysPwrMd 497;
BA_REL_ "GenSigTimeoutTime" BU_SG_REL_ EBCM_HS SG_ 497 SysPwrMd 250;
BA_REL_ "GenSigSuprvResp" BU_SG_REL_ EBCM_HS SG_ 497 SysPwrMd 1;
BA_REL_ "GenSigTimeoutMsg" BU_SG_REL_ EBCM_HS SG_ 497 SysPwrMd 497;
BA_REL_ "GenSigTimeoutTime" BU_SG_REL_ EBCM_HS SG_ 497 SysPwrMd 250;
BA_REL_ "GenSigSuprvResp" BU_SG_REL_ APPS_HS SG_ 497 SysPwrMd 1;
BA_REL_ "GenSigTimeoutMsg" BU_SG_REL_ APPS_HS SG_ 497 SysPwrMd 497;
BA_REL_ "GenSigTimeoutTime" BU_SG_REL_ APPS_HS SG_ 497 SysPwrMd 250;
BA_REL_ "GenSigSuprvResp" BU_SG_REL_ EPB_HS SG_ 497 SysPwrMd 1;
BA_REL_ "GenSigTimeoutMsg" BU_SG_REL_ EPB_HS SG_ 497 SysPwrMd 497;
BA_REL_ "GenSigTimeoutTime" BU_SG_REL_ EPB_HS SG_ 497 SysPwrMd 250;
BA_REL_ "GenSigSuprvResp" BU_SG_REL_ EBCM_OBD_HS SG_ 497 TrStLgMdAtv 1;
BA_REL_ "GenSigTimeoutMsg" BU_SG_REL_ EBCM_OBD_HS SG_ 497 TrStLgMdAtv 497;
BA_REL_ "GenSigTimeoutTime" BU_SG_REL_ EBCM_OBD_HS SG_ 497 TrStLgMdAtv 250;
BA_REL_ "GenSigSuprvResp" BU_SG_REL_ EBCM_HS SG_ 497 TrStLgMdAtv 1;
BA_REL_ "GenSigTimeoutMsg" BU_SG_REL_ EBCM_HS SG_ 497 TrStLgMdAtv 497;
BA_REL_ "GenSigTimeoutTime" BU_SG_REL_ EBCM_HS SG_ 497 TrStLgMdAtv 250;
BA_REL_ "GenSigSuprvResp" BU_SG_REL_ HCP_T_HS SG_ 497 ACCompModReq 1;
BA_REL_ "GenSigTimeoutMsg" BU_SG_REL_ HCP_T_HS SG_ 497 ACCompModReq 497;
BA_REL_ "GenSigTimeoutTime" BU_SG_REL_ HCP_T_HS SG_ 497 ACCompModReq 250;
BA_REL_ "GenSigSuprvResp" BU_SG_REL_ HCP_HS SG_ 497 ACCompModReq 1;
BA_REL_ "GenSigTimeoutMsg" BU_SG_REL_ HCP_HS SG_ 497 ACCompModReq 497;
BA_REL_ "GenSigTimeoutTime" BU_SG_REL_ HCP_HS SG_ 497 ACCompModReq 250;
BA_REL_ "GenSigVBitResp" BU_SG_REL_ ECM_HS SG_ 497 ACCompNormLd 1;
BA_REL_ "GenSigVDAFailComment" BU_SG_REL_ ECM_HS SG_ 497 ACCompNormLd "Air Conditioning Compressor System VDA";
BA_REL_ "GenSigVDAFailResp" BU_SG_REL_ ECM_HS SG_ 497 ACCompNormLd 1;
BA_REL_ "GenSigRxStartValue" BU_SG_REL_ TCCM_HS SG_ 497 PTORSMstrEngShtReq "False";
BA_REL_ "GenSigRxStartValue" BU_SG_REL_ PTO_HS SG_ 497 PTORSMstrEngShtReq "False";
BA_REL_ "GenSigRxStartValue" BU_SG_REL_ ECM_HS SG_ 497 PTORSMstrEngShtReq "False";
BA_REL_ "GenSigSuprvResp" BU_SG_REL_ ECM_HS SG_ 497 PTORSMstrEngShtReq 1;
BA_REL_ "GenSigTimeoutMsg" BU_SG_REL_ ECM_HS SG_ 497 PTORSMstrEngShtReq 497;
BA_REL_ "GenSigTimeoutTime" BU_SG_REL_ ECM_HS SG_ 497 PTORSMstrEngShtReq 250;
BA_REL_ "GenSigSuprvResp" BU_SG_REL_ HCP_T_HS SG_ 497 SIRDpl 1;
BA_REL_ "GenSigTimeoutMsg" BU_SG_REL_ HCP_T_HS SG_ 497 SIRDpl 497;
BA_REL_ "GenSigTimeoutTime" BU_SG_REL_ HCP_T_HS SG_ 497 SIRDpl 250;
BA_REL_ "GenSigRxStartValue" BU_SG_REL_ ICCM_OBD_HS SG_ 497 SIRDpl "False";
BA_REL_ "GenSigSuprvResp" BU_SG_REL_ ICCM_OBD_HS SG_ 497 SIRDpl 1;
BA_REL_ "GenSigTimeoutMsg" BU_SG_REL_ ICCM_OBD_HS SG_ 497 SIRDpl 497;
BA_REL_ "GenSigTimeoutTime" BU_SG_REL_ ICCM_OBD_HS SG_ 497 SIRDpl 250;
BA_REL_ "GenSigRxStartValue" BU_SG_REL_ ICCM_HS SG_ 497 SIRDpl "False";
BA_REL_ "GenSigSuprvResp" BU_SG_REL_ ICCM_HS SG_ 497 SIRDpl 1;
BA_REL_ "GenSigTimeoutMsg" BU_SG_REL_ ICCM_HS SG_ 497 SIRDpl 497;
BA_REL_ "GenSigTimeoutTime" BU_SG_REL_ ICCM_HS SG_ 497 SIRDpl 250;
BA_REL_ "GenSigSuprvResp" BU_SG_REL_ HCP_B_HS SG_ 497 SIRDpl 1;
BA_REL_ "GenSigTimeoutMsg" BU_SG_REL_ HCP_B_HS SG_ 497 SIRDpl 497;
BA_REL_ "GenSigTimeoutTime" BU_SG_REL_ HCP_B_HS SG_ 497 SIRDpl 250;
BA_REL_ "GenSigSuprvResp" BU_SG_REL_ HCP_HS SG_ 497 SIRDpl 1;
BA_REL_ "GenSigTimeoutMsg" BU_SG_REL_ HCP_HS SG_ 497 SIRDpl 497;
BA_REL_ "GenSigTimeoutTime" BU_SG_REL_ HCP_HS SG_ 497 SIRDpl 250;
BA_REL_ "GenSigRxStartValue" BU_SG_REL_ TCCM_HS SG_ 497 SIRDpl "False";
BA_REL_ "GenSigRxStartValue" BU_SG_REL_ BCP_HS SG_ 497 SIRDpl "False";
BA_REL_ "GenSigRxStartValue" BU_SG_REL_ ECM_HS SG_ 497 SIRDpl "False";
BA_REL_ "GenSigSuprvResp" BU_SG_REL_ PTO_HS SG_ 497 PTORmStMsEngStRq 1;
BA_REL_ "GenSigTimeoutMsg" BU_SG_REL_ PTO_HS SG_ 497 PTORmStMsEngStRq 497;
BA_REL_ "GenSigTimeoutTime" BU_SG_REL_ PTO_HS SG_ 497 PTORmStMsEngStRq 250;
BA_REL_ "GenSigSuprvResp" BU_SG_REL_ TCM_HS SG_ 497 PTORmStMsEngStRq 1;
BA_REL_ "GenSigTimeoutMsg" BU_SG_REL_ TCM_HS SG_ 497 PTORmStMsEngStRq 497;
BA_REL_ "GenSigTimeoutTime" BU_SG_REL_ TCM_HS SG_ 497 PTORmStMsEngStRq 250;
BA_REL_ "GenSigSuprvResp" BU_SG_REL_ APPS_HS SG_ 497 RmVehStrRq 1;
BA_REL_ "GenSigTimeoutMsg" BU_SG_REL_ APPS_HS SG_ 497 RmVehStrRq 497;
BA_REL_ "GenSigTimeoutTime" BU_SG_REL_ APPS_HS SG_ 497 RmVehStrRq 250;
BA_REL_ "GenSigSuprvResp" BU_SG_REL_ EPB_HS SG_ 497 RmVehStrRq 1;
BA_REL_ "GenSigTimeoutMsg" BU_SG_REL_ EPB_HS SG_ 497 RmVehStrRq 497;
BA_REL_ "GenSigTimeoutTime" BU_SG_REL_ EPB_HS SG_ 497 RmVehStrRq 250;
BA_REL_ "GenSigRxStartValue" BU_SG_REL_ TCCM_HS SG_ 497 ThrtlPrgrsnReq "$0 - Map A";
BA_REL_ "GenSigRxStartValue" BU_SG_REL_ ECM_HS SG_ 497 ThrtlPrgrsnReq "$0 - Map A";
BA_REL_ "GenSigSuprvResp" BU_SG_REL_ ECM_HS SG_ 497 ThrtlPrgrsnReq 1;
BA_REL_ "GenSigTimeoutMsg" BU_SG_REL_ ECM_HS SG_ 497 ThrtlPrgrsnReq 497;
BA_REL_ "GenSigTimeoutTime" BU_SG_REL_ ECM_HS SG_ 497 ThrtlPrgrsnReq 250;
BA_REL_ "GenSigSuprvResp" BU_SG_REL_ PTO_HS SG_ 497 PrkBrkSwAtv 1;
BA_REL_ "GenSigTimeoutMsg" BU_SG_REL_ PTO_HS SG_ 497 PrkBrkSwAtv 497;
BA_REL_ "GenSigTimeoutTime" BU_SG_REL_ PTO_HS SG_ 497 PrkBrkSwAtv 250;
BA_REL_ "GenSigSuprvResp" BU_SG_REL_ EOCM_F_HS SG_ 497 PrkBrkSwAtv 1;
BA_REL_ "GenSigTimeoutMsg" BU_SG_REL_ EOCM_F_HS SG_ 497 PrkBrkSwAtv 497;
BA_REL_ "GenSigTimeoutTime" BU_SG_REL_ EOCM_F_HS SG_ 497 PrkBrkSwAtv 250;
BA_REL_ "GenSigSuprvResp" BU_SG_REL_ RDCM_HS SG_ 497 PrkBrkSwAtv 1;
BA_REL_ "GenSigTimeoutMsg" BU_SG_REL_ RDCM_HS SG_ 497 PrkBrkSwAtv 497;
BA_REL_ "GenSigTimeoutTime" BU_SG_REL_ RDCM_HS SG_ 497 PrkBrkSwAtv 250;
BA_REL_ "GenSigSuprvResp" BU_SG_REL_ ACC_HS SG_ 497 PrkBrkSwAtv 1;
BA_REL_ "GenSigTimeoutMsg" BU_SG_REL_ ACC_HS SG_ 497 PrkBrkSwAtv 497;
BA_REL_ "GenSigTimeoutTime" BU_SG_REL_ ACC_HS SG_ 497 PrkBrkSwAtv 250;
BA_REL_ "GenSigSuprvResp" BU_SG_REL_ ACC_HS SG_ 497 PrkBrkSwAtv 1;
BA_REL_ "GenSigTimeoutMsg" BU_SG_REL_ ACC_HS SG_ 497 PrkBrkSwAtv 497;
BA_REL_ "GenSigTimeoutTime" BU_SG_REL_ ACC_HS SG_ 497 PrkBrkSwAtv 250;
BA_REL_ "GenSigRxStartValue" BU_SG_REL_ HCP_T_HS SG_ 497 ImmblzrPreRelPswdStat "$0 - No Information";
BA_REL_ "GenSigRxStartValue" BU_SG_REL_ HCP_HS SG_ 497 ImmblzrPreRelPswdStat "$0 - No Information";
BA_REL_ "GenSigRxStartValue" BU_SG_REL_ TCCM_HS SG_ 497 ImmblzrPreRelPswdStat "$0 - No Information";
BA_REL_ "GenSigRxStartValue" BU_SG_REL_ ECM_HS SG_ 497 ImmblzrPreRelPswdStat "$0 - No Information";
BA_REL_ "GenSigSuprvResp" BU_SG_REL_ HCP_B_HS SG_ 1249 VehIdNmDig10_17 1;
BA_REL_ "GenSigTimeoutMsg" BU_SG_REL_ HCP_B_HS SG_ 1249 VehIdNmDig10_17 1249;
BA_REL_ "GenSigTimeoutTime" BU_SG_REL_ HCP_B_HS SG_ 1249 VehIdNmDig10_17 2500;
BA_REL_ "GenSigSuprvResp" BU_SG_REL_ CGM_HS SG_ 1249 VehIdNmDig10_17 1;
BA_REL_ "GenSigTimeoutMsg" BU_SG_REL_ CGM_HS SG_ 1249 VehIdNmDig10_17 1249;
BA_REL_ "GenSigTimeoutTime" BU_SG_REL_ CGM_HS SG_ 1249 VehIdNmDig10_17 2500;
BA_REL_ "GenSigSuprvResp" BU_SG_REL_ HCP_T_HS SG_ 1249 VehIdNmDig10_17 1;
BA_REL_ "GenSigTimeoutMsg" BU_SG_REL_ HCP_T_HS SG_ 1249 VehIdNmDig10_17 1249;
BA_REL_ "GenSigTimeoutTime" BU_SG_REL_ HCP_T_HS SG_ 1249 VehIdNmDig10_17 2500;
BA_REL_ "GenSigSuprvResp" BU_SG_REL_ EBCM_OBD_HS SG_ 1249 VehIdNmDig10_17 1;
BA_REL_ "GenSigTimeoutMsg" BU_SG_REL_ EBCM_OBD_HS SG_ 1249 VehIdNmDig10_17 1249;
BA_REL_ "GenSigTimeoutTime" BU_SG_REL_ EBCM_OBD_HS SG_ 1249 VehIdNmDig10_17 2500;
BA_REL_ "GenSigSuprvResp" BU_SG_REL_ EBCM_HS SG_ 1249 VehIdNmDig10_17 1;
BA_REL_ "GenSigTimeoutMsg" BU_SG_REL_ EBCM_HS SG_ 1249 VehIdNmDig10_17 1249;
BA_REL_ "GenSigTimeoutTime" BU_SG_REL_ EBCM_HS SG_ 1249 VehIdNmDig10_17 2500;
BA_REL_ "GenSigSuprvResp" BU_SG_REL_ FICM_HS SG_ 1249 VehIdNmDig10_17 1;
BA_REL_ "GenSigTimeoutMsg" BU_SG_REL_ FICM_HS SG_ 1249 VehIdNmDig10_17 1249;
BA_REL_ "GenSigTimeoutTime" BU_SG_REL_ FICM_HS SG_ 1249 VehIdNmDig10_17 2500;
BA_REL_ "GenSigSuprvResp" BU_SG_REL_ RDCM_HS SG_ 1249 VehIdNmDig10_17 1;
BA_REL_ "GenSigTimeoutMsg" BU_SG_REL_ RDCM_HS SG_ 1249 VehIdNmDig10_17 1249;
BA_REL_ "GenSigTimeoutTime" BU_SG_REL_ RDCM_HS SG_ 1249 VehIdNmDig10_17 2500;
BA_REL_ "GenSigSuprvResp" BU_SG_REL_ RDCM_HS SG_ 1249 VehIdNmDig10_17 1;
BA_REL_ "GenSigTimeoutMsg" BU_SG_REL_ RDCM_HS SG_ 1249 VehIdNmDig10_17 1249;
BA_REL_ "GenSigTimeoutTime" BU_SG_REL_ RDCM_HS SG_ 1249 VehIdNmDig10_17 2500;
BA_REL_ "GenSigSuprvResp" BU_SG_REL_ TCCM_HS SG_ 1249 VehIdNmDig10_17 1;
BA_REL_ "GenSigTimeoutMsg" BU_SG_REL_ TCCM_HS SG_ 1249 VehIdNmDig10_17 1249;
BA_REL_ "GenSigTimeoutTime" BU_SG_REL_ TCCM_HS SG_ 1249 VehIdNmDig10_17 2500;
BA_REL_ "GenSigSuprvResp" BU_SG_REL_ CGM_HS SG_ 840 WhlRotDrctnlStLftDrvn 1;
BA_REL_ "GenSigTimeoutMsg" BU_SG_REL_ CGM_HS SG_ 840 WhlRotDrctnlStLftDrvn 840;
BA_REL_ "GenSigTimeoutTime" BU_SG_REL_ CGM_HS SG_ 840 WhlRotDrctnlStLftDrvn 250;
BA_REL_ "GenSigSuprvResp" BU_SG_REL_ EOCM_F_HS SG_ 840 WhlRotDrctnlStLftDrvn 1;
BA_REL_ "GenSigTimeoutMsg" BU_SG_REL_ EOCM_F_HS SG_ 840 WhlRotDrctnlStLftDrvn 840;
BA_REL_ "GenSigTimeoutTime" BU_SG_REL_ EOCM_F_HS SG_ 840 WhlRotDrctnlStLftDrvn 160;
BA_REL_ "GenSigSuprvResp" BU_SG_REL_ EPS_HS SG_ 840 WhlRotDrctnlStLftDrvn 1;
BA_REL_ "GenSigTimeoutMsg" BU_SG_REL_ EPS_HS SG_ 840 WhlRotDrctnlStLftDrvn 840;
BA_REL_ "GenSigTimeoutTime" BU_SG_REL_ EPS_HS SG_ 840 WhlRotDrctnlStLftDrvn 250;
BA_REL_ "GenSigSuprvResp" BU_SG_REL_ CGM_HS SG_ 840 WhlRotDrctnlStRtDrvn 1;
BA_REL_ "GenSigTimeoutMsg" BU_SG_REL_ CGM_HS SG_ 840 WhlRotDrctnlStRtDrvn 840;
BA_REL_ "GenSigTimeoutTime" BU_SG_REL_ CGM_HS SG_ 840 WhlRotDrctnlStRtDrvn 250;
BA_REL_ "GenSigSuprvResp" BU_SG_REL_ EOCM_F_HS SG_ 840 WhlRotDrctnlStRtDrvn 1;
BA_REL_ "GenSigTimeoutMsg" BU_SG_REL_ EOCM_F_HS SG_ 840 WhlRotDrctnlStRtDrvn 840;
BA_REL_ "GenSigTimeoutTime" BU_SG_REL_ EOCM_F_HS SG_ 840 WhlRotDrctnlStRtDrvn 160;
BA_REL_ "GenSigSuprvResp" BU_SG_REL_ EPS_HS SG_ 840 WhlRotDrctnlStRtDrvn 1;
BA_REL_ "GenSigTimeoutMsg" BU_SG_REL_ EPS_HS SG_ 840 WhlRotDrctnlStRtDrvn 840;
BA_REL_ "GenSigTimeoutTime" BU_SG_REL_ EPS_HS SG_ 840 WhlRotDrctnlStRtDrvn 250;
BA_REL_ "GenSigSuprvResp" BU_SG_REL_ CGM_HS SG_ 840 WhlGrndVlctyRtDrvn 1;
BA_REL_ "GenSigTimeoutMsg" BU_SG_REL_ CGM_HS SG_ 840 WhlGrndVlctyRtDrvn 840;
BA_REL_ "GenSigTimeoutTime" BU_SG_REL_ CGM_HS SG_ 840 WhlGrndVlctyRtDrvn 250;
BA_REL_ "GenSigSuprvResp" BU_SG_REL_ TCCM_HS SG_ 840 WhlGrndVlctyRtDrvn 1;
BA_REL_ "GenSigTimeoutMsg" BU_SG_REL_ TCCM_HS SG_ 840 WhlGrndVlctyRtDrvn 840;
BA_REL_ "GenSigTimeoutTime" BU_SG_REL_ TCCM_HS SG_ 840 WhlGrndVlctyRtDrvn 250;
BA_REL_ "GenSigSuprvResp" BU_SG_REL_ FCM_HS SG_ 840 WhlGrndVlctyRtDrvn 1;
BA_REL_ "GenSigTimeoutMsg" BU_SG_REL_ FCM_HS SG_ 840 WhlGrndVlctyRtDrvn 840;
BA_REL_ "GenSigTimeoutTime" BU_SG_REL_ FCM_HS SG_ 840 WhlGrndVlctyRtDrvn 250;
BA_REL_ "GenSigVBitResp" BU_SG_REL_ APPS_HS SG_ 840 WhlGrndVlctyRtDrvn 1;
BA_REL_ "GenSigSuprvResp" BU_SG_REL_ APPS_HS SG_ 840 WhlGrndVlctyRtDrvn 1;
BA_REL_ "GenSigTimeoutMsg" BU_SG_REL_ APPS_HS SG_ 840 WhlGrndVlctyRtDrvn 840;
BA_REL_ "GenSigTimeoutTime" BU_SG_REL_ APPS_HS SG_ 840 WhlGrndVlctyRtDrvn 250;
BA_REL_ "GenSigSuprvResp" BU_SG_REL_ EOCM_F_HS SG_ 840 WhlGrndVlctyRtDrvn 1;
BA_REL_ "GenSigTimeoutMsg" BU_SG_REL_ EOCM_F_HS SG_ 840 WhlGrndVlctyRtDrvn 840;
BA_REL_ "GenSigTimeoutTime" BU_SG_REL_ EOCM_F_HS SG_ 840 WhlGrndVlctyRtDrvn 160;
BA_REL_ "GenSigVBitResp" BU_SG_REL_ BCM_HS SG_ 840 WhlGrndVlctyRtDrvn 1;
BA_REL_ "GenSigSuprvResp" BU_SG_REL_ BCM_HS SG_ 840 WhlGrndVlctyRtDrvn 1;
BA_REL_ "GenSigTimeoutMsg" BU_SG_REL_ BCM_HS SG_ 840 WhlGrndVlctyRtDrvn 840;
BA_REL_ "GenSigTimeoutTime" BU_SG_REL_ BCM_HS SG_ 840 WhlGrndVlctyRtDrvn 250;
BA_REL_ "GenSigSuprvResp" BU_SG_REL_ ACC_HS SG_ 840 WhlGrndVlctyRtDrvn 1;
BA_REL_ "GenSigTimeoutMsg" BU_SG_REL_ ACC_HS SG_ 840 WhlGrndVlctyRtDrvn 840;
BA_REL_ "GenSigTimeoutTime" BU_SG_REL_ ACC_HS SG_ 840 WhlGrndVlctyRtDrvn 125;
BA_REL_ "GenSigSuprvResp" BU_SG_REL_ EPB_HS SG_ 840 WhlGrndVlctyRtDrvn 1;
BA_REL_ "GenSigTimeoutMsg" BU_SG_REL_ EPB_HS SG_ 840 WhlGrndVlctyRtDrvn 840;
BA_REL_ "GenSigTimeoutTime" BU_SG_REL_ EPB_HS SG_ 840 WhlGrndVlctyRtDrvn 125;
BA_REL_ "GenSigSuprvResp" BU_SG_REL_ VES_HS SG_ 840 WhlGrndVlctyRtDrvn 1;
BA_REL_ "GenSigTimeoutMsg" BU_SG_REL_ VES_HS SG_ 840 WhlGrndVlctyRtDrvn 840;
BA_REL_ "GenSigTimeoutTime" BU_SG_REL_ VES_HS SG_ 840 WhlGrndVlctyRtDrvn 250;
BA_REL_ "GenSigSuprvResp" BU_SG_REL_ EPS_HS SG_ 840 WhlGrndVlctyRtDrvn 1;
BA_REL_ "GenSigTimeoutMsg" BU_SG_REL_ EPS_HS SG_ 840 WhlGrndVlctyRtDrvn 840;
BA_REL_ "GenSigTimeoutTime" BU_SG_REL_ EPS_HS SG_ 840 WhlGrndVlctyRtDrvn 250;
BA_REL_ "GenSigSuprvResp" BU_SG_REL_ SADS_HS SG_ 840 WhlGrndVlctyRtDrvn 1;
BA_REL_ "GenSigTimeoutMsg" BU_SG_REL_ SADS_HS SG_ 840 WhlGrndVlctyRtDrvn 840;
BA_REL_ "GenSigTimeoutTime" BU_SG_REL_ SADS_HS SG_ 840 WhlGrndVlctyRtDrvn 250;
BA_REL_ "GenSigSuprvResp" BU_SG_REL_ CGM_HS SG_ 840 WhlGrndVlctyLftDrvn 1;
BA_REL_ "GenSigTimeoutMsg" BU_SG_REL_ CGM_HS SG_ 840 WhlGrndVlctyLftDrvn 840;
BA_REL_ "GenSigTimeoutTime" BU_SG_REL_ CGM_HS SG_ 840 WhlGrndVlctyLftDrvn 250;
BA_REL_ "GenSigSuprvResp" BU_SG_REL_ TCCM_HS SG_ 840 WhlGrndVlctyLftDrvn 1;
BA_REL_ "GenSigTimeoutMsg" BU_SG_REL_ TCCM_HS SG_ 840 WhlGrndVlctyLftDrvn 840;
BA_REL_ "GenSigTimeoutTime" BU_SG_REL_ TCCM_HS SG_ 840 WhlGrndVlctyLftDrvn 250;
BA_REL_ "GenSigSuprvResp" BU_SG_REL_ FCM_HS SG_ 840 WhlGrndVlctyLftDrvn 1;
BA_REL_ "GenSigTimeoutMsg" BU_SG_REL_ FCM_HS SG_ 840 WhlGrndVlctyLftDrvn 840;
BA_REL_ "GenSigTimeoutTime" BU_SG_REL_ FCM_HS SG_ 840 WhlGrndVlctyLftDrvn 250;
BA_REL_ "GenSigVBitResp" BU_SG_REL_ APPS_HS SG_ 840 WhlGrndVlctyLftDrvn 1;
BA_REL_ "GenSigSuprvResp" BU_SG_REL_ APPS_HS SG_ 840 WhlGrndVlctyLftDrvn 1;
BA_REL_ "GenSigTimeoutMsg" BU_SG_REL_ APPS_HS SG_ 840 WhlGrndVlctyLftDrvn 840;
BA_REL_ "GenSigTimeoutTime" BU_SG_REL_ APPS_HS SG_ 840 WhlGrndVlctyLftDrvn 250;
BA_REL_ "GenSigSuprvResp" BU_SG_REL_ EOCM_F_HS SG_ 840 WhlGrndVlctyLftDrvn 1;
BA_REL_ "GenSigTimeoutMsg" BU_SG_REL_ EOCM_F_HS SG_ 840 WhlGrndVlctyLftDrvn 840;
BA_REL_ "GenSigTimeoutTime" BU_SG_REL_ EOCM_F_HS SG_ 840 WhlGrndVlctyLftDrvn 160;
BA_REL_ "GenSigVBitResp" BU_SG_REL_ BCM_HS SG_ 840 WhlGrndVlctyLftDrvn 1;
BA_REL_ "GenSigSuprvResp" BU_SG_REL_ BCM_HS SG_ 840 WhlGrndVlctyLftDrvn 1;
BA_REL_ "GenSigTimeoutMsg" BU_SG_REL_ BCM_HS SG_ 840 WhlGrndVlctyLftDrvn 840;
BA_REL_ "GenSigTimeoutTime" BU_SG_REL_ BCM_HS SG_ 840 WhlGrndVlctyLftDrvn 250;
BA_REL_ "GenSigVBitResp" BU_SG_REL_ RDCM_HS SG_ 840 WhlGrndVlctyLftDrvn 1;
BA_REL_ "GenSigSuprvResp" BU_SG_REL_ RDCM_HS SG_ 840 WhlGrndVlctyLftDrvn 1;
BA_REL_ "GenSigTimeoutMsg" BU_SG_REL_ RDCM_HS SG_ 840 WhlGrndVlctyLftDrvn 840;
BA_REL_ "GenSigTimeoutTime" BU_SG_REL_ RDCM_HS SG_ 840 WhlGrndVlctyLftDrvn 250;
BA_REL_ "GenSigVBitResp" BU_SG_REL_ RDCM_HS SG_ 840 WhlGrndVlctyLftDrvn 1;
BA_REL_ "GenSigSuprvResp" BU_SG_REL_ RDCM_HS SG_ 840 WhlGrndVlctyLftDrvn 1;
BA_REL_ "GenSigTimeoutMsg" BU_SG_REL_ RDCM_HS SG_ 840 WhlGrndVlctyLftDrvn 840;
BA_REL_ "GenSigTimeoutTime" BU_SG_REL_ RDCM_HS SG_ 840 WhlGrndVlctyLftDrvn 250;
BA_REL_ "GenSigSuprvResp" BU_SG_REL_ ACC_HS SG_ 840 WhlGrndVlctyLftDrvn 1;
BA_REL_ "GenSigTimeoutMsg" BU_SG_REL_ ACC_HS SG_ 840 WhlGrndVlctyLftDrvn 840;
BA_REL_ "GenSigTimeoutTime" BU_SG_REL_ ACC_HS SG_ 840 WhlGrndVlctyLftDrvn 125;
BA_REL_ "GenSigSuprvResp" BU_SG_REL_ EPB_HS SG_ 840 WhlGrndVlctyLftDrvn 1;
BA_REL_ "GenSigTimeoutMsg" BU_SG_REL_ EPB_HS SG_ 840 WhlGrndVlctyLftDrvn 840;
BA_REL_ "GenSigTimeoutTime" BU_SG_REL_ EPB_HS SG_ 840 WhlGrndVlctyLftDrvn 125;
BA_REL_ "GenSigSuprvResp" BU_SG_REL_ HCP_B_HS SG_ 193 WRSLDWhlDisTpRC 1;
BA_REL_ "GenSigTimeoutMsg" BU_SG_REL_ HCP_B_HS SG_ 193 WRSLDWhlDisTpRC 193;
BA_REL_ "GenSigTimeoutTime" BU_SG_REL_ HCP_B_HS SG_ 193 WRSLDWhlDisTpRC 250;
BA_REL_ "GenSigSuprvResp" BU_SG_REL_ FCM_HS SG_ 193 WRSLDWhlDisTpRC 1;
BA_REL_ "GenSigTimeoutMsg" BU_SG_REL_ FCM_HS SG_ 193 WRSLDWhlDisTpRC 193;
BA_REL_ "GenSigTimeoutTime" BU_SG_REL_ FCM_HS SG_ 193 WRSLDWhlDisTpRC 250;
BA_REL_ "GenSigSuprvResp" BU_SG_REL_ HCP_T_HS SG_ 193 WRSLDWhlDisTpRC 1;
BA_REL_ "GenSigTimeoutMsg" BU_SG_REL_ HCP_T_HS SG_ 193 WRSLDWhlDisTpRC 193;
BA_REL_ "GenSigTimeoutTime" BU_SG_REL_ HCP_T_HS SG_ 193 WRSLDWhlDisTpRC 250;
BA_REL_ "GenSigSuprvResp" BU_SG_REL_ HCP_T_HS SG_ 193 WRSLDWhlDisTpRC 1;
BA_REL_ "GenSigTimeoutMsg" BU_SG_REL_ HCP_T_HS SG_ 193 WRSLDWhlDisTpRC 193;
BA_REL_ "GenSigTimeoutTime" BU_SG_REL_ HCP_T_HS SG_ 193 WRSLDWhlDisTpRC 250;
BA_REL_ "GenSigSuprvResp" BU_SG_REL_ FICM_HS SG_ 193 WRSLDWhlDisTpRC 1;
BA_REL_ "GenSigTimeoutMsg" BU_SG_REL_ FICM_HS SG_ 193 WRSLDWhlDisTpRC 193;
BA_REL_ "GenSigTimeoutTime" BU_SG_REL_ FICM_HS SG_ 193 WRSLDWhlDisTpRC 250;
BA_REL_ "GenSigSuprvResp" BU_SG_REL_ CGM_HS SG_ 193 WRSLDWhlDisTpRC 1;
BA_REL_ "GenSigTimeoutMsg" BU_SG_REL_ CGM_HS SG_ 193 WRSLDWhlDisTpRC 193;
BA_REL_ "GenSigTimeoutTime" BU_SG_REL_ CGM_HS SG_ 193 WRSLDWhlDisTpRC 250;
BA_REL_ "GenSigSuprvResp" BU_SG_REL_ HCP_HS SG_ 193 WRSLDWhlDisTpRC 1;
BA_REL_ "GenSigTimeoutMsg" BU_SG_REL_ HCP_HS SG_ 193 WRSLDWhlDisTpRC 193;
BA_REL_ "GenSigTimeoutTime" BU_SG_REL_ HCP_HS SG_ 193 WRSLDWhlDisTpRC 250;
BA_REL_ "GenSigSuprvResp" BU_SG_REL_ RDCM_HS SG_ 193 WRSLDWhlDisTpRC 1;
BA_REL_ "GenSigTimeoutMsg" BU_SG_REL_ RDCM_HS SG_ 193 WRSLDWhlDisTpRC 193;
BA_REL_ "GenSigTimeoutTime" BU_SG_REL_ RDCM_HS SG_ 193 WRSLDWhlDisTpRC 250;
BA_REL_ "GenSigSuprvResp" BU_SG_REL_ PTO_HS SG_ 193 WRSLDWhlDisTpRC 1;
BA_REL_ "GenSigTimeoutMsg" BU_SG_REL_ PTO_HS SG_ 193 WRSLDWhlDisTpRC 193;
BA_REL_ "GenSigTimeoutTime" BU_SG_REL_ PTO_HS SG_ 193 WRSLDWhlDisTpRC 250;
BA_REL_ "GenSigSuprvResp" BU_SG_REL_ BCM_HS SG_ 193 WRSLDWhlDisTpRC 1;
BA_REL_ "GenSigTimeoutMsg" BU_SG_REL_ BCM_HS SG_ 193 WRSLDWhlDisTpRC 193;
BA_REL_ "GenSigTimeoutTime" BU_SG_REL_ BCM_HS SG_ 193 WRSLDWhlDisTpRC 250;
BA_REL_ "GenSigSuprvResp" BU_SG_REL_ TCCM_HS SG_ 193 WRSLDWhlDisTpRC 1;
BA_REL_ "GenSigTimeoutMsg" BU_SG_REL_ TCCM_HS SG_ 193 WRSLDWhlDisTpRC 193;
BA_REL_ "GenSigTimeoutTime" BU_SG_REL_ TCCM_HS SG_ 193 WRSLDWhlDisTpRC 25;
BA_REL_ "GenSigSuprvResp" BU_SG_REL_ HCP_B_HS SG_ 193 WRSLDSeqNum 1;
BA_REL_ "GenSigTimeoutMsg" BU_SG_REL_ HCP_B_HS SG_ 193 WRSLDSeqNum 193;
BA_REL_ "GenSigTimeoutTime" BU_SG_REL_ HCP_B_HS SG_ 193 WRSLDSeqNum 250;
BA_REL_ "GenSigSuprvResp" BU_SG_REL_ FCM_HS SG_ 193 WRSLDSeqNum 1;
BA_REL_ "GenSigTimeoutMsg" BU_SG_REL_ FCM_HS SG_ 193 WRSLDSeqNum 193;
BA_REL_ "GenSigTimeoutTime" BU_SG_REL_ FCM_HS SG_ 193 WRSLDSeqNum 250;
BA_REL_ "GenSigSuprvResp" BU_SG_REL_ HCP_T_HS SG_ 193 WRSLDSeqNum 1;
BA_REL_ "GenSigTimeoutMsg" BU_SG_REL_ HCP_T_HS SG_ 193 WRSLDSeqNum 193;
BA_REL_ "GenSigTimeoutTime" BU_SG_REL_ HCP_T_HS SG_ 193 WRSLDSeqNum 250;
BA_REL_ "GenSigSuprvResp" BU_SG_REL_ HCP_T_HS SG_ 193 WRSLDSeqNum 1;
BA_REL_ "GenSigTimeoutMsg" BU_SG_REL_ HCP_T_HS SG_ 193 WRSLDSeqNum 193;
BA_REL_ "GenSigTimeoutTime" BU_SG_REL_ HCP_T_HS SG_ 193 WRSLDSeqNum 250;
BA_REL_ "GenSigSuprvResp" BU_SG_REL_ FICM_HS SG_ 193 WRSLDSeqNum 1;
BA_REL_ "GenSigTimeoutMsg" BU_SG_REL_ FICM_HS SG_ 193 WRSLDSeqNum 193;
BA_REL_ "GenSigTimeoutTime" BU_SG_REL_ FICM_HS SG_ 193 WRSLDSeqNum 250;
BA_REL_ "GenSigSuprvResp" BU_SG_REL_ CGM_HS SG_ 193 WRSLDSeqNum 1;
BA_REL_ "GenSigTimeoutMsg" BU_SG_REL_ CGM_HS SG_ 193 WRSLDSeqNum 193;
BA_REL_ "GenSigTimeoutTime" BU_SG_REL_ CGM_HS SG_ 193 WRSLDSeqNum 250;
BA_REL_ "GenSigSuprvResp" BU_SG_REL_ HCP_HS SG_ 193 WRSLDSeqNum 1;
BA_REL_ "GenSigTimeoutMsg" BU_SG_REL_ HCP_HS SG_ 193 WRSLDSeqNum 193;
BA_REL_ "GenSigTimeoutTime" BU_SG_REL_ HCP_HS SG_ 193 WRSLDSeqNum 250;
BA_REL_ "GenSigSuprvResp" BU_SG_REL_ RDCM_HS SG_ 193 WRSLDSeqNum 1;
BA_REL_ "GenSigTimeoutMsg" BU_SG_REL_ RDCM_HS SG_ 193 WRSLDSeqNum 193;
BA_REL_ "GenSigTimeoutTime" BU_SG_REL_ RDCM_HS SG_ 193 WRSLDSeqNum 250;
BA_REL_ "GenSigSuprvResp" BU_SG_REL_ PTO_HS SG_ 193 WRSLDSeqNum 1;
BA_REL_ "GenSigTimeoutMsg" BU_SG_REL_ PTO_HS SG_ 193 WRSLDSeqNum 193;
BA_REL_ "GenSigTimeoutTime" BU_SG_REL_ PTO_HS SG_ 193 WRSLDSeqNum 250;
BA_REL_ "GenSigSuprvResp" BU_SG_REL_ BCM_HS SG_ 193 WRSLDSeqNum 1;
BA_REL_ "GenSigTimeoutMsg" BU_SG_REL_ BCM_HS SG_ 193 WRSLDSeqNum 193;
BA_REL_ "GenSigTimeoutTime" BU_SG_REL_ BCM_HS SG_ 193 WRSLDSeqNum 250;
BA_REL_ "GenSigSuprvResp" BU_SG_REL_ TCCM_HS SG_ 193 WRSLDSeqNum 1;
BA_REL_ "GenSigTimeoutMsg" BU_SG_REL_ TCCM_HS SG_ 193 WRSLDSeqNum 193;
BA_REL_ "GenSigTimeoutTime" BU_SG_REL_ TCCM_HS SG_ 193 WRSLDSeqNum 25;
BA_REL_ "GenSigSuprvResp" BU_SG_REL_ HCP_B_HS SG_ 193 WRSLDWhlDistVal 1;
BA_REL_ "GenSigTimeoutMsg" BU_SG_REL_ HCP_B_HS SG_ 193 WRSLDWhlDistVal 193;
BA_REL_ "GenSigTimeoutTime" BU_SG_REL_ HCP_B_HS SG_ 193 WRSLDWhlDistVal 250;
BA_REL_ "GenSigSuprvResp" BU_SG_REL_ FCM_HS SG_ 193 WRSLDWhlDistVal 1;
BA_REL_ "GenSigTimeoutMsg" BU_SG_REL_ FCM_HS SG_ 193 WRSLDWhlDistVal 193;
BA_REL_ "GenSigTimeoutTime" BU_SG_REL_ FCM_HS SG_ 193 WRSLDWhlDistVal 250;
BA_REL_ "GenSigSuprvResp" BU_SG_REL_ HCP_T_HS SG_ 193 WRSLDWhlDistVal 1;
BA_REL_ "GenSigTimeoutMsg" BU_SG_REL_ HCP_T_HS SG_ 193 WRSLDWhlDistVal 193;
BA_REL_ "GenSigTimeoutTime" BU_SG_REL_ HCP_T_HS SG_ 193 WRSLDWhlDistVal 250;
BA_REL_ "GenSigSuprvResp" BU_SG_REL_ HCP_T_HS SG_ 193 WRSLDWhlDistVal 1;
BA_REL_ "GenSigTimeoutMsg" BU_SG_REL_ HCP_T_HS SG_ 193 WRSLDWhlDistVal 193;
BA_REL_ "GenSigTimeoutTime" BU_SG_REL_ HCP_T_HS SG_ 193 WRSLDWhlDistVal 250;
BA_REL_ "GenSigSuprvResp" BU_SG_REL_ FICM_HS SG_ 193 WRSLDWhlDistVal 1;
BA_REL_ "GenSigTimeoutMsg" BU_SG_REL_ FICM_HS SG_ 193 WRSLDWhlDistVal 193;
BA_REL_ "GenSigTimeoutTime" BU_SG_REL_ FICM_HS SG_ 193 WRSLDWhlDistVal 250;
BA_REL_ "GenSigSuprvResp" BU_SG_REL_ CGM_HS SG_ 193 WRSLDWhlDistVal 1;
BA_REL_ "GenSigTimeoutMsg" BU_SG_REL_ CGM_HS SG_ 193 WRSLDWhlDistVal 193;
BA_REL_ "GenSigTimeoutTime" BU_SG_REL_ CGM_HS SG_ 193 WRSLDWhlDistVal 250;
BA_REL_ "GenSigSuprvResp" BU_SG_REL_ HCP_HS SG_ 193 WRSLDWhlDistVal 1;
BA_REL_ "GenSigTimeoutMsg" BU_SG_REL_ HCP_HS SG_ 193 WRSLDWhlDistVal 193;
BA_REL_ "GenSigTimeoutTime" BU_SG_REL_ HCP_HS SG_ 193 WRSLDWhlDistVal 250;
BA_REL_ "GenSigSuprvResp" BU_SG_REL_ RDCM_HS SG_ 193 WRSLDWhlDistVal 1;
BA_REL_ "GenSigTimeoutMsg" BU_SG_REL_ RDCM_HS SG_ 193 WRSLDWhlDistVal 193;
BA_REL_ "GenSigTimeoutTime" BU_SG_REL_ RDCM_HS SG_ 193 WRSLDWhlDistVal 250;
BA_REL_ "GenSigSuprvResp" BU_SG_REL_ PTO_HS SG_ 193 WRSLDWhlDistVal 1;
BA_REL_ "GenSigTimeoutMsg" BU_SG_REL_ PTO_HS SG_ 193 WRSLDWhlDistVal 193;
BA_REL_ "GenSigTimeoutTime" BU_SG_REL_ PTO_HS SG_ 193 WRSLDWhlDistVal 250;
BA_REL_ "GenSigSuprvResp" BU_SG_REL_ BCM_HS SG_ 193 WRSLDWhlDistVal 1;
BA_REL_ "GenSigTimeoutMsg" BU_SG_REL_ BCM_HS SG_ 193 WRSLDWhlDistVal 193;
BA_REL_ "GenSigTimeoutTime" BU_SG_REL_ BCM_HS SG_ 193 WRSLDWhlDistVal 250;
BA_REL_ "GenSigSuprvResp" BU_SG_REL_ TCCM_HS SG_ 193 WRSLDWhlDistVal 1;
BA_REL_ "GenSigTimeoutMsg" BU_SG_REL_ TCCM_HS SG_ 193 WRSLDWhlDistVal 193;
BA_REL_ "GenSigTimeoutTime" BU_SG_REL_ TCCM_HS SG_ 193 WRSLDWhlDistVal 25;
BA_REL_ "GenSigSuprvResp" BU_SG_REL_ HCP_B_HS SG_ 193 WRSLDWhlRotStatRst 1;
BA_REL_ "GenSigTimeoutMsg" BU_SG_REL_ HCP_B_HS SG_ 193 WRSLDWhlRotStatRst 193;
BA_REL_ "GenSigTimeoutTime" BU_SG_REL_ HCP_B_HS SG_ 193 WRSLDWhlRotStatRst 250;
BA_REL_ "GenSigSuprvResp" BU_SG_REL_ FCM_HS SG_ 193 WRSLDWhlRotStatRst 1;
BA_REL_ "GenSigTimeoutMsg" BU_SG_REL_ FCM_HS SG_ 193 WRSLDWhlRotStatRst 193;
BA_REL_ "GenSigTimeoutTime" BU_SG_REL_ FCM_HS SG_ 193 WRSLDWhlRotStatRst 250;
BA_REL_ "GenSigSuprvResp" BU_SG_REL_ HCP_T_HS SG_ 193 WRSLDWhlRotStatRst 1;
BA_REL_ "GenSigTimeoutMsg" BU_SG_REL_ HCP_T_HS SG_ 193 WRSLDWhlRotStatRst 193;
BA_REL_ "GenSigTimeoutTime" BU_SG_REL_ HCP_T_HS SG_ 193 WRSLDWhlRotStatRst 250;
BA_REL_ "GenSigSuprvResp" BU_SG_REL_ HCP_T_HS SG_ 193 WRSLDWhlRotStatRst 1;
BA_REL_ "GenSigTimeoutMsg" BU_SG_REL_ HCP_T_HS SG_ 193 WRSLDWhlRotStatRst 193;
BA_REL_ "GenSigTimeoutTime" BU_SG_REL_ HCP_T_HS SG_ 193 WRSLDWhlRotStatRst 250;
BA_REL_ "GenSigSuprvResp" BU_SG_REL_ FICM_HS SG_ 193 WRSLDWhlRotStatRst 1;
BA_REL_ "GenSigTimeoutMsg" BU_SG_REL_ FICM_HS SG_ 193 WRSLDWhlRotStatRst 193;
BA_REL_ "GenSigTimeoutTime" BU_SG_REL_ FICM_HS SG_ 193 WRSLDWhlRotStatRst 250;
BA_REL_ "GenSigSuprvResp" BU_SG_REL_ CGM_HS SG_ 193 WRSLDWhlRotStatRst 1;
BA_REL_ "GenSigTimeoutMsg" BU_SG_REL_ CGM_HS SG_ 193 WRSLDWhlRotStatRst 193;
BA_REL_ "GenSigTimeoutTime" BU_SG_REL_ CGM_HS SG_ 193 WRSLDWhlRotStatRst 250;
BA_REL_ "GenSigSuprvResp" BU_SG_REL_ HCP_HS SG_ 193 WRSLDWhlRotStatRst 1;
BA_REL_ "GenSigTimeoutMsg" BU_SG_REL_ HCP_HS SG_ 193 WRSLDWhlRotStatRst 193;
BA_REL_ "GenSigTimeoutTime" BU_SG_REL_ HCP_HS SG_ 193 WRSLDWhlRotStatRst 250;
BA_REL_ "GenSigSuprvResp" BU_SG_REL_ RDCM_HS SG_ 193 WRSLDWhlRotStatRst 1;
BA_REL_ "GenSigTimeoutMsg" BU_SG_REL_ RDCM_HS SG_ 193 WRSLDWhlRotStatRst 193;
BA_REL_ "GenSigTimeoutTime" BU_SG_REL_ RDCM_HS SG_ 193 WRSLDWhlRotStatRst 250;
BA_REL_ "GenSigSuprvResp" BU_SG_REL_ PTO_HS SG_ 193 WRSLDWhlRotStatRst 1;
BA_REL_ "GenSigTimeoutMsg" BU_SG_REL_ PTO_HS SG_ 193 WRSLDWhlRotStatRst 193;
BA_REL_ "GenSigTimeoutTime" BU_SG_REL_ PTO_HS SG_ 193 WRSLDWhlRotStatRst 250;
BA_REL_ "GenSigSuprvResp" BU_SG_REL_ BCM_HS SG_ 193 WRSLDWhlRotStatRst 1;
BA_REL_ "GenSigTimeoutMsg" BU_SG_REL_ BCM_HS SG_ 193 WRSLDWhlRotStatRst 193;
BA_REL_ "GenSigTimeoutTime" BU_SG_REL_ BCM_HS SG_ 193 WRSLDWhlRotStatRst 250;
BA_REL_ "GenSigSuprvResp" BU_SG_REL_ TCCM_HS SG_ 193 WRSLDWhlRotStatRst 1;
BA_REL_ "GenSigTimeoutMsg" BU_SG_REL_ TCCM_HS SG_ 193 WRSLDWhlRotStatRst 193;
BA_REL_ "GenSigTimeoutTime" BU_SG_REL_ TCCM_HS SG_ 193 WRSLDWhlRotStatRst 25;
BA_REL_ "GenSigSuprvResp" BU_SG_REL_ HCP_B_HS SG_ 193 WRSLDWhlDistTmstm 1;
BA_REL_ "GenSigTimeoutMsg" BU_SG_REL_ HCP_B_HS SG_ 193 WRSLDWhlDistTmstm 193;
BA_REL_ "GenSigTimeoutTime" BU_SG_REL_ HCP_B_HS SG_ 193 WRSLDWhlDistTmstm 250;
BA_REL_ "GenSigSuprvResp" BU_SG_REL_ FCM_HS SG_ 193 WRSLDWhlDistTmstm 1;
BA_REL_ "GenSigTimeoutMsg" BU_SG_REL_ FCM_HS SG_ 193 WRSLDWhlDistTmstm 193;
BA_REL_ "GenSigTimeoutTime" BU_SG_REL_ FCM_HS SG_ 193 WRSLDWhlDistTmstm 250;
BA_REL_ "GenSigSuprvResp" BU_SG_REL_ HCP_T_HS SG_ 193 WRSLDWhlDistTmstm 1;
BA_REL_ "GenSigTimeoutMsg" BU_SG_REL_ HCP_T_HS SG_ 193 WRSLDWhlDistTmstm 193;
BA_REL_ "GenSigTimeoutTime" BU_SG_REL_ HCP_T_HS SG_ 193 WRSLDWhlDistTmstm 250;
BA_REL_ "GenSigSuprvResp" BU_SG_REL_ HCP_T_HS SG_ 193 WRSLDWhlDistTmstm 1;
BA_REL_ "GenSigTimeoutMsg" BU_SG_REL_ HCP_T_HS SG_ 193 WRSLDWhlDistTmstm 193;
BA_REL_ "GenSigTimeoutTime" BU_SG_REL_ HCP_T_HS SG_ 193 WRSLDWhlDistTmstm 250;
BA_REL_ "GenSigSuprvResp" BU_SG_REL_ FICM_HS SG_ 193 WRSLDWhlDistTmstm 1;
BA_REL_ "GenSigTimeoutMsg" BU_SG_REL_ FICM_HS SG_ 193 WRSLDWhlDistTmstm 193;
BA_REL_ "GenSigTimeoutTime" BU_SG_REL_ FICM_HS SG_ 193 WRSLDWhlDistTmstm 250;
BA_REL_ "GenSigSuprvResp" BU_SG_REL_ CGM_HS SG_ 193 WRSLDWhlDistTmstm 1;
BA_REL_ "GenSigTimeoutMsg" BU_SG_REL_ CGM_HS SG_ 193 WRSLDWhlDistTmstm 193;
BA_REL_ "GenSigTimeoutTime" BU_SG_REL_ CGM_HS SG_ 193 WRSLDWhlDistTmstm 250;
BA_REL_ "GenSigSuprvResp" BU_SG_REL_ HCP_HS SG_ 193 WRSLDWhlDistTmstm 1;
BA_REL_ "GenSigTimeoutMsg" BU_SG_REL_ HCP_HS SG_ 193 WRSLDWhlDistTmstm 193;
BA_REL_ "GenSigTimeoutTime" BU_SG_REL_ HCP_HS SG_ 193 WRSLDWhlDistTmstm 250;
BA_REL_ "GenSigSuprvResp" BU_SG_REL_ RDCM_HS SG_ 193 WRSLDWhlDistTmstm 1;
BA_REL_ "GenSigTimeoutMsg" BU_SG_REL_ RDCM_HS SG_ 193 WRSLDWhlDistTmstm 193;
BA_REL_ "GenSigTimeoutTime" BU_SG_REL_ RDCM_HS SG_ 193 WRSLDWhlDistTmstm 250;
BA_REL_ "GenSigSuprvResp" BU_SG_REL_ PTO_HS SG_ 193 WRSLDWhlDistTmstm 1;
BA_REL_ "GenSigTimeoutMsg" BU_SG_REL_ PTO_HS SG_ 193 WRSLDWhlDistTmstm 193;
BA_REL_ "GenSigTimeoutTime" BU_SG_REL_ PTO_HS SG_ 193 WRSLDWhlDistTmstm 250;
BA_REL_ "GenSigSuprvResp" BU_SG_REL_ BCM_HS SG_ 193 WRSLDWhlDistTmstm 1;
BA_REL_ "GenSigTimeoutMsg" BU_SG_REL_ BCM_HS SG_ 193 WRSLDWhlDistTmstm 193;
BA_REL_ "GenSigTimeoutTime" BU_SG_REL_ BCM_HS SG_ 193 WRSLDWhlDistTmstm 250;
BA_REL_ "GenSigSuprvResp" BU_SG_REL_ TCCM_HS SG_ 193 WRSLDWhlDistTmstm 1;
BA_REL_ "GenSigTimeoutMsg" BU_SG_REL_ TCCM_HS SG_ 193 WRSLDWhlDistTmstm 193;
BA_REL_ "GenSigTimeoutTime" BU_SG_REL_ TCCM_HS SG_ 193 WRSLDWhlDistTmstm 25;
BA_REL_ "GenSigSuprvResp" BU_SG_REL_ HCP_B_HS SG_ 193 WRSLDWhlDistPlsCntr 1;
BA_REL_ "GenSigTimeoutMsg" BU_SG_REL_ HCP_B_HS SG_ 193 WRSLDWhlDistPlsCntr 193;
BA_REL_ "GenSigTimeoutTime" BU_SG_REL_ HCP_B_HS SG_ 193 WRSLDWhlDistPlsCntr 250;
BA_REL_ "GenSigSuprvResp" BU_SG_REL_ FCM_HS SG_ 193 WRSLDWhlDistPlsCntr 1;
BA_REL_ "GenSigTimeoutMsg" BU_SG_REL_ FCM_HS SG_ 193 WRSLDWhlDistPlsCntr 193;
BA_REL_ "GenSigTimeoutTime" BU_SG_REL_ FCM_HS SG_ 193 WRSLDWhlDistPlsCntr 250;
BA_REL_ "GenSigSuprvResp" BU_SG_REL_ HCP_T_HS SG_ 193 WRSLDWhlDistPlsCntr 1;
BA_REL_ "GenSigTimeoutMsg" BU_SG_REL_ HCP_T_HS SG_ 193 WRSLDWhlDistPlsCntr 193;
BA_REL_ "GenSigTimeoutTime" BU_SG_REL_ HCP_T_HS SG_ 193 WRSLDWhlDistPlsCntr 250;
BA_REL_ "GenSigSuprvResp" BU_SG_REL_ HCP_T_HS SG_ 193 WRSLDWhlDistPlsCntr 1;
BA_REL_ "GenSigTimeoutMsg" BU_SG_REL_ HCP_T_HS SG_ 193 WRSLDWhlDistPlsCntr 193;
BA_REL_ "GenSigTimeoutTime" BU_SG_REL_ HCP_T_HS SG_ 193 WRSLDWhlDistPlsCntr 250;
BA_REL_ "GenSigSuprvResp" BU_SG_REL_ FICM_HS SG_ 193 WRSLDWhlDistPlsCntr 1;
BA_REL_ "GenSigTimeoutMsg" BU_SG_REL_ FICM_HS SG_ 193 WRSLDWhlDistPlsCntr 193;
BA_REL_ "GenSigTimeoutTime" BU_SG_REL_ FICM_HS SG_ 193 WRSLDWhlDistPlsCntr 250;
BA_REL_ "GenSigSuprvResp" BU_SG_REL_ CGM_HS SG_ 193 WRSLDWhlDistPlsCntr 1;
BA_REL_ "GenSigTimeoutMsg" BU_SG_REL_ CGM_HS SG_ 193 WRSLDWhlDistPlsCntr 193;
BA_REL_ "GenSigTimeoutTime" BU_SG_REL_ CGM_HS SG_ 193 WRSLDWhlDistPlsCntr 250;
BA_REL_ "GenSigSuprvResp" BU_SG_REL_ HCP_HS SG_ 193 WRSLDWhlDistPlsCntr 1;
BA_REL_ "GenSigTimeoutMsg" BU_SG_REL_ HCP_HS SG_ 193 WRSLDWhlDistPlsCntr 193;
BA_REL_ "GenSigTimeoutTime" BU_SG_REL_ HCP_HS SG_ 193 WRSLDWhlDistPlsCntr 250;
BA_REL_ "GenSigSuprvResp" BU_SG_REL_ RDCM_HS SG_ 193 WRSLDWhlDistPlsCntr 1;
BA_REL_ "GenSigTimeoutMsg" BU_SG_REL_ RDCM_HS SG_ 193 WRSLDWhlDistPlsCntr 193;
BA_REL_ "GenSigTimeoutTime" BU_SG_REL_ RDCM_HS SG_ 193 WRSLDWhlDistPlsCntr 250;
BA_REL_ "GenSigSuprvResp" BU_SG_REL_ PTO_HS SG_ 193 WRSLDWhlDistPlsCntr 1;
BA_REL_ "GenSigTimeoutMsg" BU_SG_REL_ PTO_HS SG_ 193 WRSLDWhlDistPlsCntr 193;
BA_REL_ "GenSigTimeoutTime" BU_SG_REL_ PTO_HS SG_ 193 WRSLDWhlDistPlsCntr 250;
BA_REL_ "GenSigSuprvResp" BU_SG_REL_ BCM_HS SG_ 193 WRSLDWhlDistPlsCntr 1;
BA_REL_ "GenSigTimeoutMsg" BU_SG_REL_ BCM_HS SG_ 193 WRSLDWhlDistPlsCntr 193;
BA_REL_ "GenSigTimeoutTime" BU_SG_REL_ BCM_HS SG_ 193 WRSLDWhlDistPlsCntr 250;
BA_REL_ "GenSigSuprvResp" BU_SG_REL_ TCCM_HS SG_ 193 WRSLDWhlDistPlsCntr 1;
BA_REL_ "GenSigTimeoutMsg" BU_SG_REL_ TCCM_HS SG_ 193 WRSLDWhlDistPlsCntr 193;
BA_REL_ "GenSigTimeoutTime" BU_SG_REL_ TCCM_HS SG_ 193 WRSLDWhlDistPlsCntr 25;
BA_REL_ "GenSigSuprvResp" BU_SG_REL_ HCP_B_HS SG_ 193 WRSRDWhlDisTpRC 1;
BA_REL_ "GenSigTimeoutMsg" BU_SG_REL_ HCP_B_HS SG_ 193 WRSRDWhlDisTpRC 193;
BA_REL_ "GenSigTimeoutTime" BU_SG_REL_ HCP_B_HS SG_ 193 WRSRDWhlDisTpRC 250;
BA_REL_ "GenSigSuprvResp" BU_SG_REL_ FCM_HS SG_ 193 WRSRDWhlDisTpRC 1;
BA_REL_ "GenSigTimeoutMsg" BU_SG_REL_ FCM_HS SG_ 193 WRSRDWhlDisTpRC 193;
BA_REL_ "GenSigTimeoutTime" BU_SG_REL_ FCM_HS SG_ 193 WRSRDWhlDisTpRC 250;
BA_REL_ "GenSigSuprvResp" BU_SG_REL_ HCP_T_HS SG_ 193 WRSRDWhlDisTpRC 1;
BA_REL_ "GenSigTimeoutMsg" BU_SG_REL_ HCP_T_HS SG_ 193 WRSRDWhlDisTpRC 193;
BA_REL_ "GenSigTimeoutTime" BU_SG_REL_ HCP_T_HS SG_ 193 WRSRDWhlDisTpRC 250;
BA_REL_ "GenSigSuprvResp" BU_SG_REL_ HCP_T_HS SG_ 193 WRSRDWhlDisTpRC 1;
BA_REL_ "GenSigTimeoutMsg" BU_SG_REL_ HCP_T_HS SG_ 193 WRSRDWhlDisTpRC 193;
BA_REL_ "GenSigTimeoutTime" BU_SG_REL_ HCP_T_HS SG_ 193 WRSRDWhlDisTpRC 250;
BA_REL_ "GenSigSuprvResp" BU_SG_REL_ FICM_HS SG_ 193 WRSRDWhlDisTpRC 1;
BA_REL_ "GenSigTimeoutMsg" BU_SG_REL_ FICM_HS SG_ 193 WRSRDWhlDisTpRC 193;
BA_REL_ "GenSigTimeoutTime" BU_SG_REL_ FICM_HS SG_ 193 WRSRDWhlDisTpRC 250;
BA_REL_ "GenSigSuprvResp" BU_SG_REL_ CGM_HS SG_ 193 WRSRDWhlDisTpRC 1;
BA_REL_ "GenSigTimeoutMsg" BU_SG_REL_ CGM_HS SG_ 193 WRSRDWhlDisTpRC 193;
BA_REL_ "GenSigTimeoutTime" BU_SG_REL_ CGM_HS SG_ 193 WRSRDWhlDisTpRC 250;
BA_REL_ "GenSigSuprvResp" BU_SG_REL_ HCP_HS SG_ 193 WRSRDWhlDisTpRC 1;
BA_REL_ "GenSigTimeoutMsg" BU_SG_REL_ HCP_HS SG_ 193 WRSRDWhlDisTpRC 193;
BA_REL_ "GenSigTimeoutTime" BU_SG_REL_ HCP_HS SG_ 193 WRSRDWhlDisTpRC 250;
BA_REL_ "GenSigSuprvResp" BU_SG_REL_ BCP_HS SG_ 193 WRSRDWhlDisTpRC 1;
BA_REL_ "GenSigTimeoutMsg" BU_SG_REL_ BCP_HS SG_ 193 WRSRDWhlDisTpRC 193;
BA_REL_ "GenSigTimeoutTime" BU_SG_REL_ BCP_HS SG_ 193 WRSRDWhlDisTpRC 250;
BA_REL_ "GenSigSuprvResp" BU_SG_REL_ RDCM_HS SG_ 193 WRSRDWhlDisTpRC 1;
BA_REL_ "GenSigTimeoutMsg" BU_SG_REL_ RDCM_HS SG_ 193 WRSRDWhlDisTpRC 193;
BA_REL_ "GenSigTimeoutTime" BU_SG_REL_ RDCM_HS SG_ 193 WRSRDWhlDisTpRC 250;
BA_REL_ "GenSigSuprvResp" BU_SG_REL_ PTO_HS SG_ 193 WRSRDWhlDisTpRC 1;
BA_REL_ "GenSigTimeoutMsg" BU_SG_REL_ PTO_HS SG_ 193 WRSRDWhlDisTpRC 193;
BA_REL_ "GenSigTimeoutTime" BU_SG_REL_ PTO_HS SG_ 193 WRSRDWhlDisTpRC 250;
BA_REL_ "GenSigSuprvResp" BU_SG_REL_ BCM_HS SG_ 193 WRSRDWhlDisTpRC 1;
BA_REL_ "GenSigTimeoutMsg" BU_SG_REL_ BCM_HS SG_ 193 WRSRDWhlDisTpRC 193;
BA_REL_ "GenSigTimeoutTime" BU_SG_REL_ BCM_HS SG_ 193 WRSRDWhlDisTpRC 250;
BA_REL_ "GenSigSuprvResp" BU_SG_REL_ TCCM_HS SG_ 193 WRSRDWhlDisTpRC 1;
BA_REL_ "GenSigTimeoutMsg" BU_SG_REL_ TCCM_HS SG_ 193 WRSRDWhlDisTpRC 193;
BA_REL_ "GenSigTimeoutTime" BU_SG_REL_ TCCM_HS SG_ 193 WRSRDWhlDisTpRC 25;
BA_REL_ "GenSigSuprvResp" BU_SG_REL_ HCP_B_HS SG_ 193 WRSRDSeqNum 1;
BA_REL_ "GenSigTimeoutMsg" BU_SG_REL_ HCP_B_HS SG_ 193 WRSRDSeqNum 193;
BA_REL_ "GenSigTimeoutTime" BU_SG_REL_ HCP_B_HS SG_ 193 WRSRDSeqNum 250;
BA_REL_ "GenSigSuprvResp" BU_SG_REL_ FCM_HS SG_ 193 WRSRDSeqNum 1;
BA_REL_ "GenSigTimeoutMsg" BU_SG_REL_ FCM_HS SG_ 193 WRSRDSeqNum 193;
BA_REL_ "GenSigTimeoutTime" BU_SG_REL_ FCM_HS SG_ 193 WRSRDSeqNum 250;
BA_REL_ "GenSigSuprvResp" BU_SG_REL_ HCP_T_HS SG_ 193 WRSRDSeqNum 1;
BA_REL_ "GenSigTimeoutMsg" BU_SG_REL_ HCP_T_HS SG_ 193 WRSRDSeqNum 193;
BA_REL_ "GenSigTimeoutTime" BU_SG_REL_ HCP_T_HS SG_ 193 WRSRDSeqNum 250;
BA_REL_ "GenSigSuprvResp" BU_SG_REL_ HCP_T_HS SG_ 193 WRSRDSeqNum 1;
BA_REL_ "GenSigTimeoutMsg" BU_SG_REL_ HCP_T_HS SG_ 193 WRSRDSeqNum 193;
BA_REL_ "GenSigTimeoutTime" BU_SG_REL_ HCP_T_HS SG_ 193 WRSRDSeqNum 250;
BA_REL_ "GenSigSuprvResp" BU_SG_REL_ FICM_HS SG_ 193 WRSRDSeqNum 1;
BA_REL_ "GenSigTimeoutMsg" BU_SG_REL_ FICM_HS SG_ 193 WRSRDSeqNum 193;
BA_REL_ "GenSigTimeoutTime" BU_SG_REL_ FICM_HS SG_ 193 WRSRDSeqNum 250;
BA_REL_ "GenSigSuprvResp" BU_SG_REL_ CGM_HS SG_ 193 WRSRDSeqNum 1;
BA_REL_ "GenSigTimeoutMsg" BU_SG_REL_ CGM_HS SG_ 193 WRSRDSeqNum 193;
BA_REL_ "GenSigTimeoutTime" BU_SG_REL_ CGM_HS SG_ 193 WRSRDSeqNum 250;
BA_REL_ "GenSigSuprvResp" BU_SG_REL_ HCP_HS SG_ 193 WRSRDSeqNum 1;
BA_REL_ "GenSigTimeoutMsg" BU_SG_REL_ HCP_HS SG_ 193 WRSRDSeqNum 193;
BA_REL_ "GenSigTimeoutTime" BU_SG_REL_ HCP_HS SG_ 193 WRSRDSeqNum 250;
BA_REL_ "GenSigSuprvResp" BU_SG_REL_ BCP_HS SG_ 193 WRSRDSeqNum 1;
BA_REL_ "GenSigTimeoutMsg" BU_SG_REL_ BCP_HS SG_ 193 WRSRDSeqNum 193;
BA_REL_ "GenSigTimeoutTime" BU_SG_REL_ BCP_HS SG_ 193 WRSRDSeqNum 250;
BA_REL_ "GenSigSuprvResp" BU_SG_REL_ RDCM_HS SG_ 193 WRSRDSeqNum 1;
BA_REL_ "GenSigTimeoutMsg" BU_SG_REL_ RDCM_HS SG_ 193 WRSRDSeqNum 193;
BA_REL_ "GenSigTimeoutTime" BU_SG_REL_ RDCM_HS SG_ 193 WRSRDSeqNum 250;
BA_REL_ "GenSigSuprvResp" BU_SG_REL_ PTO_HS SG_ 193 WRSRDSeqNum 1;
BA_REL_ "GenSigTimeoutMsg" BU_SG_REL_ PTO_HS SG_ 193 WRSRDSeqNum 193;
BA_REL_ "GenSigTimeoutTime" BU_SG_REL_ PTO_HS SG_ 193 WRSRDSeqNum 250;
BA_REL_ "GenSigSuprvResp" BU_SG_REL_ BCM_HS SG_ 193 WRSRDSeqNum 1;
BA_REL_ "GenSigTimeoutMsg" BU_SG_REL_ BCM_HS SG_ 193 WRSRDSeqNum 193;
BA_REL_ "GenSigTimeoutTime" BU_SG_REL_ BCM_HS SG_ 193 WRSRDSeqNum 250;
BA_REL_ "GenSigSuprvResp" BU_SG_REL_ TCCM_HS SG_ 193 WRSRDSeqNum 1;
BA_REL_ "GenSigTimeoutMsg" BU_SG_REL_ TCCM_HS SG_ 193 WRSRDSeqNum 193;
BA_REL_ "GenSigTimeoutTime" BU_SG_REL_ TCCM_HS SG_ 193 WRSRDSeqNum 25;
BA_REL_ "GenSigSuprvResp" BU_SG_REL_ HCP_B_HS SG_ 193 WRSRDWhlRotStatRst 1;
BA_REL_ "GenSigTimeoutMsg" BU_SG_REL_ HCP_B_HS SG_ 193 WRSRDWhlRotStatRst 193;
BA_REL_ "GenSigTimeoutTime" BU_SG_REL_ HCP_B_HS SG_ 193 WRSRDWhlRotStatRst 250;
BA_REL_ "GenSigSuprvResp" BU_SG_REL_ FCM_HS SG_ 193 WRSRDWhlRotStatRst 1;
BA_REL_ "GenSigTimeoutMsg" BU_SG_REL_ FCM_HS SG_ 193 WRSRDWhlRotStatRst 193;
BA_REL_ "GenSigTimeoutTime" BU_SG_REL_ FCM_HS SG_ 193 WRSRDWhlRotStatRst 250;
BA_REL_ "GenSigSuprvResp" BU_SG_REL_ HCP_T_HS SG_ 193 WRSRDWhlRotStatRst 1;
BA_REL_ "GenSigTimeoutMsg" BU_SG_REL_ HCP_T_HS SG_ 193 WRSRDWhlRotStatRst 193;
BA_REL_ "GenSigTimeoutTime" BU_SG_REL_ HCP_T_HS SG_ 193 WRSRDWhlRotStatRst 250;
BA_REL_ "GenSigSuprvResp" BU_SG_REL_ HCP_T_HS SG_ 193 WRSRDWhlRotStatRst 1;
BA_REL_ "GenSigTimeoutMsg" BU_SG_REL_ HCP_T_HS SG_ 193 WRSRDWhlRotStatRst 193;
BA_REL_ "GenSigTimeoutTime" BU_SG_REL_ HCP_T_HS SG_ 193 WRSRDWhlRotStatRst 250;
BA_REL_ "GenSigSuprvResp" BU_SG_REL_ FICM_HS SG_ 193 WRSRDWhlRotStatRst 1;
BA_REL_ "GenSigTimeoutMsg" BU_SG_REL_ FICM_HS SG_ 193 WRSRDWhlRotStatRst 193;
BA_REL_ "GenSigTimeoutTime" BU_SG_REL_ FICM_HS SG_ 193 WRSRDWhlRotStatRst 250;
BA_REL_ "GenSigSuprvResp" BU_SG_REL_ CGM_HS SG_ 193 WRSRDWhlRotStatRst 1;
BA_REL_ "GenSigTimeoutMsg" BU_SG_REL_ CGM_HS SG_ 193 WRSRDWhlRotStatRst 193;
BA_REL_ "GenSigTimeoutTime" BU_SG_REL_ CGM_HS SG_ 193 WRSRDWhlRotStatRst 250;
BA_REL_ "GenSigSuprvResp" BU_SG_REL_ HCP_HS SG_ 193 WRSRDWhlRotStatRst 1;
BA_REL_ "GenSigTimeoutMsg" BU_SG_REL_ HCP_HS SG_ 193 WRSRDWhlRotStatRst 193;
BA_REL_ "GenSigTimeoutTime" BU_SG_REL_ HCP_HS SG_ 193 WRSRDWhlRotStatRst 250;
BA_REL_ "GenSigSuprvResp" BU_SG_REL_ BCP_HS SG_ 193 WRSRDWhlRotStatRst 1;
BA_REL_ "GenSigTimeoutMsg" BU_SG_REL_ BCP_HS SG_ 193 WRSRDWhlRotStatRst 193;
BA_REL_ "GenSigTimeoutTime" BU_SG_REL_ BCP_HS SG_ 193 WRSRDWhlRotStatRst 250;
BA_REL_ "GenSigSuprvResp" BU_SG_REL_ RDCM_HS SG_ 193 WRSRDWhlRotStatRst 1;
BA_REL_ "GenSigTimeoutMsg" BU_SG_REL_ RDCM_HS SG_ 193 WRSRDWhlRotStatRst 193;
BA_REL_ "GenSigTimeoutTime" BU_SG_REL_ RDCM_HS SG_ 193 WRSRDWhlRotStatRst 250;
BA_REL_ "GenSigSuprvResp" BU_SG_REL_ PTO_HS SG_ 193 WRSRDWhlRotStatRst 1;
BA_REL_ "GenSigTimeoutMsg" BU_SG_REL_ PTO_HS SG_ 193 WRSRDWhlRotStatRst 193;
BA_REL_ "GenSigTimeoutTime" BU_SG_REL_ PTO_HS SG_ 193 WRSRDWhlRotStatRst 250;
BA_REL_ "GenSigSuprvResp" BU_SG_REL_ BCM_HS SG_ 193 WRSRDWhlRotStatRst 1;
BA_REL_ "GenSigTimeoutMsg" BU_SG_REL_ BCM_HS SG_ 193 WRSRDWhlRotStatRst 193;
BA_REL_ "GenSigTimeoutTime" BU_SG_REL_ BCM_HS SG_ 193 WRSRDWhlRotStatRst 250;
BA_REL_ "GenSigSuprvResp" BU_SG_REL_ TCCM_HS SG_ 193 WRSRDWhlRotStatRst 1;
BA_REL_ "GenSigTimeoutMsg" BU_SG_REL_ TCCM_HS SG_ 193 WRSRDWhlRotStatRst 193;
BA_REL_ "GenSigTimeoutTime" BU_SG_REL_ TCCM_HS SG_ 193 WRSRDWhlRotStatRst 25;
BA_REL_ "GenSigSuprvResp" BU_SG_REL_ HCP_B_HS SG_ 193 WRSRDWhlDistVal 1;
BA_REL_ "GenSigTimeoutMsg" BU_SG_REL_ HCP_B_HS SG_ 193 WRSRDWhlDistVal 193;
BA_REL_ "GenSigTimeoutTime" BU_SG_REL_ HCP_B_HS SG_ 193 WRSRDWhlDistVal 250;
BA_REL_ "GenSigSuprvResp" BU_SG_REL_ FCM_HS SG_ 193 WRSRDWhlDistVal 1;
BA_REL_ "GenSigTimeoutMsg" BU_SG_REL_ FCM_HS SG_ 193 WRSRDWhlDistVal 193;
BA_REL_ "GenSigTimeoutTime" BU_SG_REL_ FCM_HS SG_ 193 WRSRDWhlDistVal 250;
BA_REL_ "GenSigSuprvResp" BU_SG_REL_ HCP_T_HS SG_ 193 WRSRDWhlDistVal 1;
BA_REL_ "GenSigTimeoutMsg" BU_SG_REL_ HCP_T_HS SG_ 193 WRSRDWhlDistVal 193;
BA_REL_ "GenSigTimeoutTime" BU_SG_REL_ HCP_T_HS SG_ 193 WRSRDWhlDistVal 250;
BA_REL_ "GenSigSuprvResp" BU_SG_REL_ HCP_T_HS SG_ 193 WRSRDWhlDistVal 1;
BA_REL_ "GenSigTimeoutMsg" BU_SG_REL_ HCP_T_HS SG_ 193 WRSRDWhlDistVal 193;
BA_REL_ "GenSigTimeoutTime" BU_SG_REL_ HCP_T_HS SG_ 193 WRSRDWhlDistVal 250;
BA_REL_ "GenSigSuprvResp" BU_SG_REL_ FICM_HS SG_ 193 WRSRDWhlDistVal 1;
BA_REL_ "GenSigTimeoutMsg" BU_SG_REL_ FICM_HS SG_ 193 WRSRDWhlDistVal 193;
BA_REL_ "GenSigTimeoutTime" BU_SG_REL_ FICM_HS SG_ 193 WRSRDWhlDistVal 250;
BA_REL_ "GenSigSuprvResp" BU_SG_REL_ CGM_HS SG_ 193 WRSRDWhlDistVal 1;
BA_REL_ "GenSigTimeoutMsg" BU_SG_REL_ CGM_HS SG_ 193 WRSRDWhlDistVal 193;
BA_REL_ "GenSigTimeoutTime" BU_SG_REL_ CGM_HS SG_ 193 WRSRDWhlDistVal 250;
BA_REL_ "GenSigSuprvResp" BU_SG_REL_ HCP_HS SG_ 193 WRSRDWhlDistVal 1;
BA_REL_ "GenSigTimeoutMsg" BU_SG_REL_ HCP_HS SG_ 193 WRSRDWhlDistVal 193;
BA_REL_ "GenSigTimeoutTime" BU_SG_REL_ HCP_HS SG_ 193 WRSRDWhlDistVal 250;
BA_REL_ "GenSigSuprvResp" BU_SG_REL_ BCP_HS SG_ 193 WRSRDWhlDistVal 1;
BA_REL_ "GenSigTimeoutMsg" BU_SG_REL_ BCP_HS SG_ 193 WRSRDWhlDistVal 193;
BA_REL_ "GenSigTimeoutTime" BU_SG_REL_ BCP_HS SG_ 193 WRSRDWhlDistVal 250;
BA_REL_ "GenSigSuprvResp" BU_SG_REL_ RDCM_HS SG_ 193 WRSRDWhlDistVal 1;
BA_REL_ "GenSigTimeoutMsg" BU_SG_REL_ RDCM_HS SG_ 193 WRSRDWhlDistVal 193;
BA_REL_ "GenSigTimeoutTime" BU_SG_REL_ RDCM_HS SG_ 193 WRSRDWhlDistVal 250;
BA_REL_ "GenSigSuprvResp" BU_SG_REL_ PTO_HS SG_ 193 WRSRDWhlDistVal 1;
BA_REL_ "GenSigTimeoutMsg" BU_SG_REL_ PTO_HS SG_ 193 WRSRDWhlDistVal 193;
BA_REL_ "GenSigTimeoutTime" BU_SG_REL_ PTO_HS SG_ 193 WRSRDWhlDistVal 250;
BA_REL_ "GenSigSuprvResp" BU_SG_REL_ BCM_HS SG_ 193 WRSRDWhlDistVal 1;
BA_REL_ "GenSigTimeoutMsg" BU_SG_REL_ BCM_HS SG_ 193 WRSRDWhlDistVal 193;
BA_REL_ "GenSigTimeoutTime" BU_SG_REL_ BCM_HS SG_ 193 WRSRDWhlDistVal 250;
BA_REL_ "GenSigSuprvResp" BU_SG_REL_ TCCM_HS SG_ 193 WRSRDWhlDistVal 1;
BA_REL_ "GenSigTimeoutMsg" BU_SG_REL_ TCCM_HS SG_ 193 WRSRDWhlDistVal 193;
BA_REL_ "GenSigTimeoutTime" BU_SG_REL_ TCCM_HS SG_ 193 WRSRDWhlDistVal 25;
BA_REL_ "GenSigSuprvResp" BU_SG_REL_ HCP_B_HS SG_ 193 WRSRDWhlDistTmstm 1;
BA_REL_ "GenSigTimeoutMsg" BU_SG_REL_ HCP_B_HS SG_ 193 WRSRDWhlDistTmstm 193;
BA_REL_ "GenSigTimeoutTime" BU_SG_REL_ HCP_B_HS SG_ 193 WRSRDWhlDistTmstm 250;
BA_REL_ "GenSigSuprvResp" BU_SG_REL_ FCM_HS SG_ 193 WRSRDWhlDistTmstm 1;
BA_REL_ "GenSigTimeoutMsg" BU_SG_REL_ FCM_HS SG_ 193 WRSRDWhlDistTmstm 193;
BA_REL_ "GenSigTimeoutTime" BU_SG_REL_ FCM_HS SG_ 193 WRSRDWhlDistTmstm 250;
BA_REL_ "GenSigSuprvResp" BU_SG_REL_ HCP_T_HS SG_ 193 WRSRDWhlDistTmstm 1;
BA_REL_ "GenSigTimeoutMsg" BU_SG_REL_ HCP_T_HS SG_ 193 WRSRDWhlDistTmstm 193;
BA_REL_ "GenSigTimeoutTime" BU_SG_REL_ HCP_T_HS SG_ 193 WRSRDWhlDistTmstm 250;
BA_REL_ "GenSigSuprvResp" BU_SG_REL_ HCP_T_HS SG_ 193 WRSRDWhlDistTmstm 1;
BA_REL_ "GenSigTimeoutMsg" BU_SG_REL_ HCP_T_HS SG_ 193 WRSRDWhlDistTmstm 193;
BA_REL_ "GenSigTimeoutTime" BU_SG_REL_ HCP_T_HS SG_ 193 WRSRDWhlDistTmstm 250;
BA_REL_ "GenSigSuprvResp" BU_SG_REL_ FICM_HS SG_ 193 WRSRDWhlDistTmstm 1;
BA_REL_ "GenSigTimeoutMsg" BU_SG_REL_ FICM_HS SG_ 193 WRSRDWhlDistTmstm 193;
BA_REL_ "GenSigTimeoutTime" BU_SG_REL_ FICM_HS SG_ 193 WRSRDWhlDistTmstm 250;
BA_REL_ "GenSigSuprvResp" BU_SG_REL_ CGM_HS SG_ 193 WRSRDWhlDistTmstm 1;
BA_REL_ "GenSigTimeoutMsg" BU_SG_REL_ CGM_HS SG_ 193 WRSRDWhlDistTmstm 193;
BA_REL_ "GenSigTimeoutTime" BU_SG_REL_ CGM_HS SG_ 193 WRSRDWhlDistTmstm 250;
BA_REL_ "GenSigSuprvResp" BU_SG_REL_ HCP_HS SG_ 193 WRSRDWhlDistTmstm 1;
BA_REL_ "GenSigTimeoutMsg" BU_SG_REL_ HCP_HS SG_ 193 WRSRDWhlDistTmstm 193;
BA_REL_ "GenSigTimeoutTime" BU_SG_REL_ HCP_HS SG_ 193 WRSRDWhlDistTmstm 250;
BA_REL_ "GenSigSuprvResp" BU_SG_REL_ BCP_HS SG_ 193 WRSRDWhlDistTmstm 1;
BA_REL_ "GenSigTimeoutMsg" BU_SG_REL_ BCP_HS SG_ 193 WRSRDWhlDistTmstm 193;
BA_REL_ "GenSigTimeoutTime" BU_SG_REL_ BCP_HS SG_ 193 WRSRDWhlDistTmstm 250;
BA_REL_ "GenSigSuprvResp" BU_SG_REL_ RDCM_HS SG_ 193 WRSRDWhlDistTmstm 1;
BA_REL_ "GenSigTimeoutMsg" BU_SG_REL_ RDCM_HS SG_ 193 WRSRDWhlDistTmstm 193;
BA_REL_ "GenSigTimeoutTime" BU_SG_REL_ RDCM_HS SG_ 193 WRSRDWhlDistTmstm 250;
BA_REL_ "GenSigSuprvResp" BU_SG_REL_ PTO_HS SG_ 193 WRSRDWhlDistTmstm 1;
BA_REL_ "GenSigTimeoutMsg" BU_SG_REL_ PTO_HS SG_ 193 WRSRDWhlDistTmstm 193;
BA_REL_ "GenSigTimeoutTime" BU_SG_REL_ PTO_HS SG_ 193 WRSRDWhlDistTmstm 250;
BA_REL_ "GenSigSuprvResp" BU_SG_REL_ BCM_HS SG_ 193 WRSRDWhlDistTmstm 1;
BA_REL_ "GenSigTimeoutMsg" BU_SG_REL_ BCM_HS SG_ 193 WRSRDWhlDistTmstm 193;
BA_REL_ "GenSigTimeoutTime" BU_SG_REL_ BCM_HS SG_ 193 WRSRDWhlDistTmstm 250;
BA_REL_ "GenSigSuprvResp" BU_SG_REL_ TCCM_HS SG_ 193 WRSRDWhlDistTmstm 1;
BA_REL_ "GenSigTimeoutMsg" BU_SG_REL_ TCCM_HS SG_ 193 WRSRDWhlDistTmstm 193;
BA_REL_ "GenSigTimeoutTime" BU_SG_REL_ TCCM_HS SG_ 193 WRSRDWhlDistTmstm 25;
BA_REL_ "GenSigSuprvResp" BU_SG_REL_ HCP_B_HS SG_ 193 WRSRDWhlDistPlsCntr 1;
BA_REL_ "GenSigTimeoutMsg" BU_SG_REL_ HCP_B_HS SG_ 193 WRSRDWhlDistPlsCntr 193;
BA_REL_ "GenSigTimeoutTime" BU_SG_REL_ HCP_B_HS SG_ 193 WRSRDWhlDistPlsCntr 250;
BA_REL_ "GenSigSuprvResp" BU_SG_REL_ FCM_HS SG_ 193 WRSRDWhlDistPlsCntr 1;
BA_REL_ "GenSigTimeoutMsg" BU_SG_REL_ FCM_HS SG_ 193 WRSRDWhlDistPlsCntr 193;
BA_REL_ "GenSigTimeoutTime" BU_SG_REL_ FCM_HS SG_ 193 WRSRDWhlDistPlsCntr 250;
BA_REL_ "GenSigSuprvResp" BU_SG_REL_ HCP_T_HS SG_ 193 WRSRDWhlDistPlsCntr 1;
BA_REL_ "GenSigTimeoutMsg" BU_SG_REL_ HCP_T_HS SG_ 193 WRSRDWhlDistPlsCntr 193;
BA_REL_ "GenSigTimeoutTime" BU_SG_REL_ HCP_T_HS SG_ 193 WRSRDWhlDistPlsCntr 250;
BA_REL_ "GenSigSuprvResp" BU_SG_REL_ HCP_T_HS SG_ 193 WRSRDWhlDistPlsCntr 1;
BA_REL_ "GenSigTimeoutMsg" BU_SG_REL_ HCP_T_HS SG_ 193 WRSRDWhlDistPlsCntr 193;
BA_REL_ "GenSigTimeoutTime" BU_SG_REL_ HCP_T_HS SG_ 193 WRSRDWhlDistPlsCntr 250;
BA_REL_ "GenSigSuprvResp" BU_SG_REL_ FICM_HS SG_ 193 WRSRDWhlDistPlsCntr 1;
BA_REL_ "GenSigTimeoutMsg" BU_SG_REL_ FICM_HS SG_ 193 WRSRDWhlDistPlsCntr 193;
BA_REL_ "GenSigTimeoutTime" BU_SG_REL_ FICM_HS SG_ 193 WRSRDWhlDistPlsCntr 250;
BA_REL_ "GenSigSuprvResp" BU_SG_REL_ CGM_HS SG_ 193 WRSRDWhlDistPlsCntr 1;
BA_REL_ "GenSigTimeoutMsg" BU_SG_REL_ CGM_HS SG_ 193 WRSRDWhlDistPlsCntr 193;
BA_REL_ "GenSigTimeoutTime" BU_SG_REL_ CGM_HS SG_ 193 WRSRDWhlDistPlsCntr 250;
BA_REL_ "GenSigSuprvResp" BU_SG_REL_ HCP_HS SG_ 193 WRSRDWhlDistPlsCntr 1;
BA_REL_ "GenSigTimeoutMsg" BU_SG_REL_ HCP_HS SG_ 193 WRSRDWhlDistPlsCntr 193;
BA_REL_ "GenSigTimeoutTime" BU_SG_REL_ HCP_HS SG_ 193 WRSRDWhlDistPlsCntr 250;
BA_REL_ "GenSigSuprvResp" BU_SG_REL_ BCP_HS SG_ 193 WRSRDWhlDistPlsCntr 1;
BA_REL_ "GenSigTimeoutMsg" BU_SG_REL_ BCP_HS SG_ 193 WRSRDWhlDistPlsCntr 193;
BA_REL_ "GenSigTimeoutTime" BU_SG_REL_ BCP_HS SG_ 193 WRSRDWhlDistPlsCntr 250;
BA_REL_ "GenSigSuprvResp" BU_SG_REL_ RDCM_HS SG_ 193 WRSRDWhlDistPlsCntr 1;
BA_REL_ "GenSigTimeoutMsg" BU_SG_REL_ RDCM_HS SG_ 193 WRSRDWhlDistPlsCntr 193;
BA_REL_ "GenSigTimeoutTime" BU_SG_REL_ RDCM_HS SG_ 193 WRSRDWhlDistPlsCntr 250;
BA_REL_ "GenSigSuprvResp" BU_SG_REL_ PTO_HS SG_ 193 WRSRDWhlDistPlsCntr 1;
BA_REL_ "GenSigTimeoutMsg" BU_SG_REL_ PTO_HS SG_ 193 WRSRDWhlDistPlsCntr 193;
BA_REL_ "GenSigTimeoutTime" BU_SG_REL_ PTO_HS SG_ 193 WRSRDWhlDistPlsCntr 250;
BA_REL_ "GenSigSuprvResp" BU_SG_REL_ BCM_HS SG_ 193 WRSRDWhlDistPlsCntr 1;
BA_REL_ "GenSigTimeoutMsg" BU_SG_REL_ BCM_HS SG_ 193 WRSRDWhlDistPlsCntr 193;
BA_REL_ "GenSigTimeoutTime" BU_SG_REL_ BCM_HS SG_ 193 WRSRDWhlDistPlsCntr 250;
BA_REL_ "GenSigSuprvResp" BU_SG_REL_ TCCM_HS SG_ 193 WRSRDWhlDistPlsCntr 1;
BA_REL_ "GenSigTimeoutMsg" BU_SG_REL_ TCCM_HS SG_ 193 WRSRDWhlDistPlsCntr 193;
BA_REL_ "GenSigTimeoutTime" BU_SG_REL_ TCCM_HS SG_ 193 WRSRDWhlDistPlsCntr 25;
BA_REL_ "GenSigSuprvResp" BU_SG_REL_ PTO_HS SG_ 481 CrsSecSwStatPVal 1;
BA_REL_ "GenSigTimeoutMsg" BU_SG_REL_ PTO_HS SG_ 481 CrsSecSwStatPVal 481;
BA_REL_ "GenSigTimeoutTime" BU_SG_REL_ PTO_HS SG_ 481 CrsSecSwStatPVal 250;
BA_REL_ "GenSigSuprvResp" BU_SG_REL_ PTO_HS SG_ 481 CrsSecSwStatARC 1;
BA_REL_ "GenSigTimeoutMsg" BU_SG_REL_ PTO_HS SG_ 481 CrsSecSwStatARC 481;
BA_REL_ "GenSigTimeoutTime" BU_SG_REL_ PTO_HS SG_ 481 CrsSecSwStatARC 250;
BA_REL_ "GenSigSuprvResp" BU_SG_REL_ PTO_HS SG_ 481 CrsSecSwStat 1;
BA_REL_ "GenSigTimeoutMsg" BU_SG_REL_ PTO_HS SG_ 481 CrsSecSwStat 481;
BA_REL_ "GenSigTimeoutTime" BU_SG_REL_ PTO_HS SG_ 481 CrsSecSwStat 250;
BA_REL_ "GenSigSuprvResp" BU_SG_REL_ PTO_HS SG_ 481 CrsSpdLmtrSwStatPVal 1;
BA_REL_ "GenSigTimeoutMsg" BU_SG_REL_ PTO_HS SG_ 481 CrsSpdLmtrSwStatPVal 481;
BA_REL_ "GenSigTimeoutTime" BU_SG_REL_ PTO_HS SG_ 481 CrsSpdLmtrSwStatPVal 250;
BA_REL_ "GenSigSuprvResp" BU_SG_REL_ PTO_HS SG_ 481 CrsSpdLmtrSwStatARC 1;
BA_REL_ "GenSigTimeoutMsg" BU_SG_REL_ PTO_HS SG_ 481 CrsSpdLmtrSwStatARC 481;
BA_REL_ "GenSigTimeoutTime" BU_SG_REL_ PTO_HS SG_ 481 CrsSpdLmtrSwStatARC 250;
BA_REL_ "GenSigSuprvResp" BU_SG_REL_ PTO_HS SG_ 481 CrsSpdLmtrSwStat 1;
BA_REL_ "GenSigTimeoutMsg" BU_SG_REL_ PTO_HS SG_ 481 CrsSpdLmtrSwStat 481;
BA_REL_ "GenSigTimeoutTime" BU_SG_REL_ PTO_HS SG_ 481 CrsSpdLmtrSwStat 250;
BA_REL_ "GenSigSuprvResp" BU_SG_REL_ EOCM_F_HS SG_ 481 AdptCrsGapSwAct 2;
BA_REL_ "GenSigTimeoutMsg" BU_SG_REL_ EOCM_F_HS SG_ 481 AdptCrsGapSwAct 481;
BA_REL_ "GenSigTimeoutTime" BU_SG_REL_ EOCM_F_HS SG_ 481 AdptCrsGapSwAct 120;
BA_REL_ "GenSigSuprvResp" BU_SG_REL_ ACC_HS SG_ 481 AdptCrsGapSwAct 1;
BA_REL_ "GenSigTimeoutMsg" BU_SG_REL_ ACC_HS SG_ 481 AdptCrsGapSwAct 481;
BA_REL_ "GenSigTimeoutTime" BU_SG_REL_ ACC_HS SG_ 481 AdptCrsGapSwAct 250;
BA_REL_ "GenSigSuprvResp" BU_SG_REL_ ACC_HS SG_ 481 CrsCntrlSwStCanSwAct 1;
BA_REL_ "GenSigTimeoutMsg" BU_SG_REL_ ACC_HS SG_ 481 CrsCntrlSwStCanSwAct 481;
BA_REL_ "GenSigTimeoutTime" BU_SG_REL_ ACC_HS SG_ 481 CrsCntrlSwStCanSwAct 250;
BA_REL_ "GenSigSuprvResp" BU_SG_REL_ ACC_HS SG_ 481 CrsCntrlSwStSwDataIntgty 1;
BA_REL_ "GenSigTimeoutMsg" BU_SG_REL_ ACC_HS SG_ 481 CrsCntrlSwStSwDataIntgty 481;
BA_REL_ "GenSigTimeoutTime" BU_SG_REL_ ACC_HS SG_ 481 CrsCntrlSwStSwDataIntgty 250;
BA_REL_ "GenSigSuprvResp" BU_SG_REL_ ACC_HS SG_ 481 CrsCntrlSwStSpdInSwAct 1;
BA_REL_ "GenSigTimeoutMsg" BU_SG_REL_ ACC_HS SG_ 481 CrsCntrlSwStSpdInSwAct 481;
BA_REL_ "GenSigTimeoutTime" BU_SG_REL_ ACC_HS SG_ 481 CrsCntrlSwStSpdInSwAct 250;
BA_REL_ "GenSigSuprvResp" BU_SG_REL_ ACC_HS SG_ 481 CrsCntrlSwStSpDcSwAct 1;
BA_REL_ "GenSigTimeoutMsg" BU_SG_REL_ ACC_HS SG_ 481 CrsCntrlSwStSpDcSwAct 481;
BA_REL_ "GenSigTimeoutTime" BU_SG_REL_ ACC_HS SG_ 481 CrsCntrlSwStSpDcSwAct 250;
BA_REL_ "GenSigSuprvResp" BU_SG_REL_ ACC_HS SG_ 481 CrsCntrlSwStSetSwAct 1;
BA_REL_ "GenSigTimeoutMsg" BU_SG_REL_ ACC_HS SG_ 481 CrsCntrlSwStSetSwAct 481;
BA_REL_ "GenSigTimeoutTime" BU_SG_REL_ ACC_HS SG_ 481 CrsCntrlSwStSetSwAct 250;
BA_REL_ "GenSigSuprvResp" BU_SG_REL_ ACC_HS SG_ 481 CrsCntrlSwStResSwAct 1;
BA_REL_ "GenSigTimeoutMsg" BU_SG_REL_ ACC_HS SG_ 481 CrsCntrlSwStResSwAct 481;
BA_REL_ "GenSigTimeoutTime" BU_SG_REL_ ACC_HS SG_ 481 CrsCntrlSwStResSwAct 250;
BA_REL_ "GenSigSuprvResp" BU_SG_REL_ ACC_HS SG_ 481 CrsCntrlSwStOnSwAct 1;
BA_REL_ "GenSigTimeoutMsg" BU_SG_REL_ ACC_HS SG_ 481 CrsCntrlSwStOnSwAct 481;
BA_REL_ "GenSigTimeoutTime" BU_SG_REL_ ACC_HS SG_ 481 CrsCntrlSwStOnSwAct 250;
BA_REL_ "GenSigSuprvResp" BU_SG_REL_ EOCM_F_HS SG_ 481 CrsCntrlSwStAlvRollCnt 1;
BA_REL_ "GenSigTimeoutMsg" BU_SG_REL_ EOCM_F_HS SG_ 481 CrsCntrlSwStAlvRollCnt 481;
BA_REL_ "GenSigTimeoutTime" BU_SG_REL_ EOCM_F_HS SG_ 481 CrsCntrlSwStAlvRollCnt 120;
BA_REL_ "GenSigSuprvResp" BU_SG_REL_ ICCM_OBD_HS SG_ 455 CSETRER_TorqReqVal 1;
BA_REL_ "GenSigTimeoutMsg" BU_SG_REL_ ICCM_OBD_HS SG_ 455 CSETRER_TorqReqVal 455;
BA_REL_ "GenSigTimeoutTime" BU_SG_REL_ ICCM_OBD_HS SG_ 455 CSETRER_TorqReqVal 250;
BA_REL_ "GenSigSuprvResp" BU_SG_REL_ ICCM_HS SG_ 455 CSETRER_TorqReqVal 1;
BA_REL_ "GenSigTimeoutMsg" BU_SG_REL_ ICCM_HS SG_ 455 CSETRER_TorqReqVal 455;
BA_REL_ "GenSigTimeoutTime" BU_SG_REL_ ICCM_HS SG_ 455 CSETRER_TorqReqVal 250;
BA_REL_ "GenSigSuprvResp" BU_SG_REL_ EOCM_F_HS SG_ 455 CSETRER_TorqReqVal 1;
BA_REL_ "GenSigTimeoutMsg" BU_SG_REL_ EOCM_F_HS SG_ 455 CSETRER_TorqReqVal 455;
BA_REL_ "GenSigTimeoutTime" BU_SG_REL_ EOCM_F_HS SG_ 455 CSETRER_TorqReqVal 120;
BA_REL_ "GenSigSuprvResp" BU_SG_REL_ ACC_HS SG_ 455 CSETRER_TorqReqVal 1;
BA_REL_ "GenSigTimeoutMsg" BU_SG_REL_ ACC_HS SG_ 455 CSETRER_TorqReqVal 455;
BA_REL_ "GenSigTimeoutTime" BU_SG_REL_ ACC_HS SG_ 455 CSETRER_TorqReqVal 120;
BA_REL_ "GenSigSuprvResp" BU_SG_REL_ ICCM_OBD_HS SG_ 455 CSETRER_TqIntvnTyp 1;
BA_REL_ "GenSigTimeoutMsg" BU_SG_REL_ ICCM_OBD_HS SG_ 455 CSETRER_TqIntvnTyp 455;
BA_REL_ "GenSigTimeoutTime" BU_SG_REL_ ICCM_OBD_HS SG_ 455 CSETRER_TqIntvnTyp 250;
BA_REL_ "GenSigSuprvResp" BU_SG_REL_ ICCM_HS SG_ 455 CSETRER_TqIntvnTyp 1;
BA_REL_ "GenSigTimeoutMsg" BU_SG_REL_ ICCM_HS SG_ 455 CSETRER_TqIntvnTyp 455;
BA_REL_ "GenSigTimeoutTime" BU_SG_REL_ ICCM_HS SG_ 455 CSETRER_TqIntvnTyp 250;
BA_REL_ "GenSigSuprvResp" BU_SG_REL_ EOCM_F_HS SG_ 455 CSETRER_TqIntvnTyp 1;
BA_REL_ "GenSigTimeoutMsg" BU_SG_REL_ EOCM_F_HS SG_ 455 CSETRER_TqIntvnTyp 455;
BA_REL_ "GenSigTimeoutTime" BU_SG_REL_ EOCM_F_HS SG_ 455 CSETRER_TqIntvnTyp 120;
BA_REL_ "GenSigSuprvResp" BU_SG_REL_ ACC_HS SG_ 455 CSETRER_TqIntvnTyp 1;
BA_REL_ "GenSigTimeoutMsg" BU_SG_REL_ ACC_HS SG_ 455 CSETRER_TqIntvnTyp 455;
BA_REL_ "GenSigTimeoutTime" BU_SG_REL_ ACC_HS SG_ 455 CSETRER_TqIntvnTyp 120;
BA_REL_ "GenSigRxStartValue" BU_SG_REL_ ECM_HS SG_ 455 CSETRER_TqIntvnTyp "$0 - No intervention";
BA_REL_ "GenSigSuprvResp" BU_SG_REL_ TCM_HS SG_ 761 BrkSysHRBkCtrlAvail 1;
BA_REL_ "GenSigTimeoutMsg" BU_SG_REL_ TCM_HS SG_ 761 BrkSysHRBkCtrlAvail 761;
BA_REL_ "GenSigTimeoutTime" BU_SG_REL_ TCM_HS SG_ 761 BrkSysHRBkCtrlAvail 250;
BA_REL_ "GenSigSuprvResp" BU_SG_REL_ TCM_HS SG_ 761 BrkSysHRBkCtrlStat 1;
BA_REL_ "GenSigTimeoutMsg" BU_SG_REL_ TCM_HS SG_ 761 BrkSysHRBkCtrlStat 761;
BA_REL_ "GenSigTimeoutTime" BU_SG_REL_ TCM_HS SG_ 761 BrkSysHRBkCtrlStat 250;
BA_REL_ "GenSigSuprvResp" BU_SG_REL_ TCM_HS SG_ 761 BrkSysHSAAval 1;
BA_REL_ "GenSigTimeoutMsg" BU_SG_REL_ TCM_HS SG_ 761 BrkSysHSAAval 761;
BA_REL_ "GenSigTimeoutTime" BU_SG_REL_ TCM_HS SG_ 761 BrkSysHSAAval 250;
BA_REL_ "GenSigSuprvResp" BU_SG_REL_ TCM_HS SG_ 761 BrkSysHSAStat 1;
BA_REL_ "GenSigTimeoutMsg" BU_SG_REL_ TCM_HS SG_ 761 BrkSysHSAStat 761;
BA_REL_ "GenSigTimeoutTime" BU_SG_REL_ TCM_HS SG_ 761 BrkSysHSAStat 250;
BA_REL_ "GenSigSuprvResp" BU_SG_REL_ ECM_HS SG_ 761 HillDscntCtrlStatPVal 1;
BA_REL_ "GenSigTimeoutMsg" BU_SG_REL_ ECM_HS SG_ 761 HillDscntCtrlStatPVal 761;
BA_REL_ "GenSigTimeoutTime" BU_SG_REL_ ECM_HS SG_ 761 HillDscntCtrlStatPVal 250;
BA_REL_ "GenSigSuprvResp" BU_SG_REL_ ECM_HS SG_ 761 HillDscntCtrlStatARC 1;
BA_REL_ "GenSigTimeoutMsg" BU_SG_REL_ ECM_HS SG_ 761 HillDscntCtrlStatARC 761;
BA_REL_ "GenSigTimeoutTime" BU_SG_REL_ ECM_HS SG_ 761 HillDscntCtrlStatARC 250;
BA_REL_ "GenSigSuprvResp" BU_SG_REL_ ECM_HS SG_ 761 HillDscntCtrlStat 1;
BA_REL_ "GenSigTimeoutMsg" BU_SG_REL_ ECM_HS SG_ 761 HillDscntCtrlStat 761;
BA_REL_ "GenSigTimeoutTime" BU_SG_REL_ ECM_HS SG_ 761 HillDscntCtrlStat 250;
BA_REL_ "GenSigSuprvResp" BU_SG_REL_ FCM_HS SG_ 761 AutoBrkFeatInhbtPVal 1;
BA_REL_ "GenSigTimeoutMsg" BU_SG_REL_ FCM_HS SG_ 761 AutoBrkFeatInhbtPVal 761;
BA_REL_ "GenSigTimeoutTime" BU_SG_REL_ FCM_HS SG_ 761 AutoBrkFeatInhbtPVal 250;
BA_REL_ "GenSigSuprvResp" BU_SG_REL_ FCM_HS SG_ 761 AutoBrkFeatInhbtARC 1;
BA_REL_ "GenSigTimeoutMsg" BU_SG_REL_ FCM_HS SG_ 761 AutoBrkFeatInhbtARC 761;
BA_REL_ "GenSigTimeoutTime" BU_SG_REL_ FCM_HS SG_ 761 AutoBrkFeatInhbtARC 250;
BA_REL_ "GenSigSuprvResp" BU_SG_REL_ FCM_HS SG_ 761 ABFI_CollPrepSysInhbt 1;
BA_REL_ "GenSigTimeoutMsg" BU_SG_REL_ FCM_HS SG_ 761 ABFI_CollPrepSysInhbt 761;
BA_REL_ "GenSigTimeoutTime" BU_SG_REL_ FCM_HS SG_ 761 ABFI_CollPrepSysInhbt 250;
BA_REL_ "GenSigSuprvResp" BU_SG_REL_ FCM_HS SG_ 761 ABFI_RrVirtlBmprInh 1;
BA_REL_ "GenSigTimeoutMsg" BU_SG_REL_ FCM_HS SG_ 761 ABFI_RrVirtlBmprInh 761;
BA_REL_ "GenSigTimeoutTime" BU_SG_REL_ FCM_HS SG_ 761 ABFI_RrVirtlBmprInh 250;
BA_REL_ "GenSigSuprvResp" BU_SG_REL_ HCP_B_HS SG_ 761 BrkPdlDrvApplPres 1;
BA_REL_ "GenSigTimeoutMsg" BU_SG_REL_ HCP_B_HS SG_ 761 BrkPdlDrvApplPres 761;
BA_REL_ "GenSigTimeoutTime" BU_SG_REL_ HCP_B_HS SG_ 761 BrkPdlDrvApplPres 250;
BA_REL_ "GenSigSuprvResp" BU_SG_REL_ BCP_HS SG_ 761 BrkPdlDrvApplPres 1;
BA_REL_ "GenSigTimeoutMsg" BU_SG_REL_ BCP_HS SG_ 761 BrkPdlDrvApplPres 761;
BA_REL_ "GenSigTimeoutTime" BU_SG_REL_ BCP_HS SG_ 761 BrkPdlDrvApplPres 250;
BA_REL_ "GenSigSuprvResp" BU_SG_REL_ FCM_HS SG_ 761 BrkPdlDrvApplPres 1;
BA_REL_ "GenSigTimeoutMsg" BU_SG_REL_ FCM_HS SG_ 761 BrkPdlDrvApplPres 761;
BA_REL_ "GenSigTimeoutTime" BU_SG_REL_ FCM_HS SG_ 761 BrkPdlDrvApplPres 250;
BA_REL_ "GenSigSuprvResp" BU_SG_REL_ VES_HS SG_ 761 BrkPdlDrvApplPres 1;
BA_REL_ "GenSigTimeoutMsg" BU_SG_REL_ VES_HS SG_ 761 BrkPdlDrvApplPres 761;
BA_REL_ "GenSigTimeoutTime" BU_SG_REL_ VES_HS SG_ 761 BrkPdlDrvApplPres 250;
BA_REL_ "GenSigSuprvResp" BU_SG_REL_ EPS_HS SG_ 761 BrkPdlDrvApplPres 1;
BA_REL_ "GenSigTimeoutMsg" BU_SG_REL_ EPS_HS SG_ 761 BrkPdlDrvApplPres 761;
BA_REL_ "GenSigTimeoutTime" BU_SG_REL_ EPS_HS SG_ 761 BrkPdlDrvApplPres 250;
BA_REL_ "GenSigSuprvResp" BU_SG_REL_ FCM_HS SG_ 761 AutoBrkPTReqStat 1;
BA_REL_ "GenSigTimeoutMsg" BU_SG_REL_ FCM_HS SG_ 761 AutoBrkPTReqStat 761;
BA_REL_ "GenSigTimeoutTime" BU_SG_REL_ FCM_HS SG_ 761 AutoBrkPTReqStat 250;
BA_REL_ "GenSigSuprvResp" BU_SG_REL_ VES_HS SG_ 761 SprTireSt 1;
BA_REL_ "GenSigTimeoutMsg" BU_SG_REL_ VES_HS SG_ 761 SprTireSt 761;
BA_REL_ "GenSigTimeoutTime" BU_SG_REL_ VES_HS SG_ 761 SprTireSt 250;
BA_REL_ "GenSigSuprvResp" BU_SG_REL_ EPS_HS SG_ 761 SprTireSt 1;
BA_REL_ "GenSigTimeoutMsg" BU_SG_REL_ EPS_HS SG_ 761 SprTireSt 761;
BA_REL_ "GenSigTimeoutTime" BU_SG_REL_ EPS_HS SG_ 761 SprTireSt 250;
BA_REL_ "GenSigSuprvResp" BU_SG_REL_ RDCM_HS SG_ 761 SprTireSt 1;
BA_REL_ "GenSigTimeoutMsg" BU_SG_REL_ RDCM_HS SG_ 761 SprTireSt 761;
BA_REL_ "GenSigTimeoutTime" BU_SG_REL_ RDCM_HS SG_ 761 SprTireSt 250;
BA_REL_ "GenSigSuprvResp" BU_SG_REL_ TCCM_HS SG_ 761 SprTireSt 1;
BA_REL_ "GenSigTimeoutMsg" BU_SG_REL_ TCCM_HS SG_ 761 SprTireSt 761;
BA_REL_ "GenSigTimeoutTime" BU_SG_REL_ TCCM_HS SG_ 761 SprTireSt 250;
BA_REL_ "GenSigSuprvResp" BU_SG_REL_ TCCM_HS SG_ 761 SprTireSt 1;
BA_REL_ "GenSigTimeoutMsg" BU_SG_REL_ TCCM_HS SG_ 761 SprTireSt 761;
BA_REL_ "GenSigTimeoutTime" BU_SG_REL_ TCCM_HS SG_ 761 SprTireSt 250;
BA_REL_ "GenSigSuprvResp" BU_SG_REL_ ECM_HS SG_ 489 EnhDrvMdSwChUseRq 1;
BA_REL_ "GenSigTimeoutMsg" BU_SG_REL_ ECM_HS SG_ 489 EnhDrvMdSwChUseRq 489;
BA_REL_ "GenSigTimeoutTime" BU_SG_REL_ ECM_HS SG_ 489 EnhDrvMdSwChUseRq 250;
BA_REL_ "GenSigSuprvResp" BU_SG_REL_ TCM_HS SG_ 489 DrvIndpntBrkAppAct 1;
BA_REL_ "GenSigTimeoutMsg" BU_SG_REL_ TCM_HS SG_ 489 DrvIndpntBrkAppAct 489;
BA_REL_ "GenSigTimeoutTime" BU_SG_REL_ TCM_HS SG_ 489 DrvIndpntBrkAppAct 50;
BA_REL_ "GenSigSuprvResp" BU_SG_REL_ ECM_HS SG_ 489 DrvIndpntBrkAppAct 1;
BA_REL_ "GenSigTimeoutMsg" BU_SG_REL_ ECM_HS SG_ 489 DrvIndpntBrkAppAct 489;
BA_REL_ "GenSigTimeoutTime" BU_SG_REL_ ECM_HS SG_ 489 DrvIndpntBrkAppAct 50;
BA_REL_ "GenSigSuprvResp" BU_SG_REL_ HCP_HS SG_ 489 WhlSlpSt 1;
BA_REL_ "GenSigTimeoutMsg" BU_SG_REL_ HCP_HS SG_ 489 WhlSlpSt 489;
BA_REL_ "GenSigTimeoutTime" BU_SG_REL_ HCP_HS SG_ 489 WhlSlpSt 250;
BA_REL_ "GenSigSuprvResp" BU_SG_REL_ HCP_T_HS SG_ 489 WhlSlpSt 1;
BA_REL_ "GenSigTimeoutMsg" BU_SG_REL_ HCP_T_HS SG_ 489 WhlSlpSt 489;
BA_REL_ "GenSigTimeoutTime" BU_SG_REL_ HCP_T_HS SG_ 489 WhlSlpSt 250;
BA_REL_ "GenSigSuprvResp" BU_SG_REL_ ECM_HS SG_ 489 WhlSlpSt 1;
BA_REL_ "GenSigTimeoutMsg" BU_SG_REL_ ECM_HS SG_ 489 WhlSlpSt 489;
BA_REL_ "GenSigTimeoutTime" BU_SG_REL_ ECM_HS SG_ 489 WhlSlpSt 250;
BA_REL_ "GenSigRxStartValue" BU_SG_REL_ TCM_HS SG_ 489 BSTGRReqdGear "$0 - No Action";
BA_REL_ "GenSigRxStartValue" BU_SG_REL_ TCM_HS SG_ 489 BSTGRReqType "$0 - No Action";
BA_REL_ "GenSigSuprvResp" BU_SG_REL_ EPS_HS SG_ 489 VehDynOvrUndrStr 1;
BA_REL_ "GenSigTimeoutMsg" BU_SG_REL_ EPS_HS SG_ 489 VehDynOvrUndrStr 489;
BA_REL_ "GenSigTimeoutTime" BU_SG_REL_ EPS_HS SG_ 489 VehDynOvrUndrStr 250;
BA_REL_ "GenSigSuprvResp" BU_SG_REL_ FCM_HS SG_ 489 VSELatAcc 1;
BA_REL_ "GenSigTimeoutMsg" BU_SG_REL_ FCM_HS SG_ 489 VSELatAcc 489;
BA_REL_ "GenSigTimeoutTime" BU_SG_REL_ FCM_HS SG_ 489 VSELatAcc 250;
BA_REL_ "GenSigSuprvResp" BU_SG_REL_ EPS_HS SG_ 489 VSELatAcc 1;
BA_REL_ "GenSigTimeoutMsg" BU_SG_REL_ EPS_HS SG_ 489 VSELatAcc 489;
BA_REL_ "GenSigTimeoutTime" BU_SG_REL_ EPS_HS SG_ 489 VSELatAcc 250;
BA_REL_ "GenSigSuprvResp" BU_SG_REL_ ICCM_OBD_HS SG_ 489 VSEAct 1;
BA_REL_ "GenSigTimeoutMsg" BU_SG_REL_ ICCM_OBD_HS SG_ 489 VSEAct 489;
BA_REL_ "GenSigTimeoutTime" BU_SG_REL_ ICCM_OBD_HS SG_ 489 VSEAct 250;
BA_REL_ "GenSigSuprvResp" BU_SG_REL_ ICCM_HS SG_ 489 VSEAct 1;
BA_REL_ "GenSigTimeoutMsg" BU_SG_REL_ ICCM_HS SG_ 489 VSEAct 489;
BA_REL_ "GenSigTimeoutTime" BU_SG_REL_ ICCM_HS SG_ 489 VSEAct 250;
BA_REL_ "GenSigSuprvResp" BU_SG_REL_ EOCM_F_HS SG_ 489 VSEAct 1;
BA_REL_ "GenSigTimeoutMsg" BU_SG_REL_ EOCM_F_HS SG_ 489 VSEAct 489;
BA_REL_ "GenSigTimeoutTime" BU_SG_REL_ EOCM_F_HS SG_ 489 VSEAct 120;
BA_REL_ "GenSigSuprvResp" BU_SG_REL_ EOCM_F_HS SG_ 489 VSEAct 1;
BA_REL_ "GenSigTimeoutMsg" BU_SG_REL_ EOCM_F_HS SG_ 489 VSEAct 489;
BA_REL_ "GenSigTimeoutTime" BU_SG_REL_ EOCM_F_HS SG_ 489 VSEAct 120;
BA_REL_ "GenSigSuprvResp" BU_SG_REL_ EOCM_F_HS SG_ 489 VSEAct 1;
BA_REL_ "GenSigTimeoutTime" BU_SG_REL_ EOCM_F_HS SG_ 489 VSEAct 120;
BA_REL_ "GenSigSuprvResp" BU_SG_REL_ ACC_HS SG_ 489 VSEAct 1;
BA_REL_ "GenSigTimeoutMsg" BU_SG_REL_ ACC_HS SG_ 489 VSEAct 489;
BA_REL_ "GenSigTimeoutTime" BU_SG_REL_ ACC_HS SG_ 489 VSEAct 120;
BA_REL_ "GenSigSuprvResp" BU_SG_REL_ ACC_HS SG_ 489 VSEAct 1;
BA_REL_ "GenSigTimeoutTime" BU_SG_REL_ ACC_HS SG_ 489 VSEAct 120;
BA_REL_ "GenSigSuprvResp" BU_SG_REL_ ACC_HS SG_ 489 VSEAct 1;
BA_REL_ "GenSigTimeoutMsg" BU_SG_REL_ ACC_HS SG_ 489 VSEAct 489;
BA_REL_ "GenSigTimeoutTime" BU_SG_REL_ ACC_HS SG_ 489 VSEAct 250;
BA_REL_ "GenSigSuprvResp" BU_SG_REL_ EOCM_F_HS SG_ 489 VhDynCntlSysSt 1;
BA_REL_ "GenSigTimeoutMsg" BU_SG_REL_ EOCM_F_HS SG_ 489 VhDynCntlSysSt 489;
BA_REL_ "GenSigTimeoutTime" BU_SG_REL_ EOCM_F_HS SG_ 489 VhDynCntlSysSt 250;
BA_REL_ "GenSigSuprvResp" BU_SG_REL_ FCM_HS SG_ 489 VhDynCntlSysSt 1;
BA_REL_ "GenSigTimeoutMsg" BU_SG_REL_ FCM_HS SG_ 489 VhDynCntlSysSt 489;
BA_REL_ "GenSigTimeoutTime" BU_SG_REL_ FCM_HS SG_ 489 VhDynCntlSysSt 250;
BA_REL_ "GenSigSuprvResp" BU_SG_REL_ RDCM_HS SG_ 489 VhDynCntlSysSt 1;
BA_REL_ "GenSigTimeoutMsg" BU_SG_REL_ RDCM_HS SG_ 489 VhDynCntlSysSt 489;
BA_REL_ "GenSigTimeoutTime" BU_SG_REL_ RDCM_HS SG_ 489 VhDynCntlSysSt 250;
BA_REL_ "GenSigSuprvRespSubValue" BU_SG_REL_ BCM_HS SG_ 489 VehDynYawRateV 1;
BA_REL_ "GenSigSuprvResp" BU_SG_REL_ BCM_HS SG_ 489 VehDynYawRateV 2;
BA_REL_ "GenSigTimeoutMsg" BU_SG_REL_ BCM_HS SG_ 489 VehDynYawRateV 489;
BA_REL_ "GenSigTimeoutTime" BU_SG_REL_ BCM_HS SG_ 489 VehDynYawRateV 250;
BA_REL_ "GenSigSuprvResp" BU_SG_REL_ ICCM_OBD_HS SG_ 489 VehDynYawRate 1;
BA_REL_ "GenSigTimeoutMsg" BU_SG_REL_ ICCM_OBD_HS SG_ 489 VehDynYawRate 489;
BA_REL_ "GenSigTimeoutTime" BU_SG_REL_ ICCM_OBD_HS SG_ 489 VehDynYawRate 250;
BA_REL_ "GenSigSuprvResp" BU_SG_REL_ ICCM_HS SG_ 489 VehDynYawRate 1;
BA_REL_ "GenSigTimeoutMsg" BU_SG_REL_ ICCM_HS SG_ 489 VehDynYawRate 489;
BA_REL_ "GenSigTimeoutTime" BU_SG_REL_ ICCM_HS SG_ 489 VehDynYawRate 250;
BA_REL_ "GenSigSuprvResp" BU_SG_REL_ FCM_HS SG_ 489 VehDynYawRate 1;
BA_REL_ "GenSigTimeoutMsg" BU_SG_REL_ FCM_HS SG_ 489 VehDynYawRate 489;
BA_REL_ "GenSigTimeoutTime" BU_SG_REL_ FCM_HS SG_ 489 VehDynYawRate 250;
BA_REL_ "GenSigSuprvResp" BU_SG_REL_ HMIM_HS SG_ 489 VehDynYawRate 1;
BA_REL_ "GenSigTimeoutMsg" BU_SG_REL_ HMIM_HS SG_ 489 VehDynYawRate 489;
BA_REL_ "GenSigTimeoutTime" BU_SG_REL_ HMIM_HS SG_ 489 VehDynYawRate 250;
BA_REL_ "GenSigVBitResp" BU_SG_REL_ BCM_HS SG_ 489 VehDynYawRate 1;
BA_REL_ "GenSigSuprvResp" BU_SG_REL_ BCM_HS SG_ 489 VehDynYawRate 1;
BA_REL_ "GenSigTimeoutMsg" BU_SG_REL_ BCM_HS SG_ 489 VehDynYawRate 489;
BA_REL_ "GenSigTimeoutTime" BU_SG_REL_ BCM_HS SG_ 489 VehDynYawRate 250;
BA_REL_ "GenSigSuprvResp" BU_SG_REL_ AHL_AFL_HS SG_ 489 VehDynYawRate 1;
BA_REL_ "GenSigTimeoutMsg" BU_SG_REL_ AHL_AFL_HS SG_ 489 VehDynYawRate 489;
BA_REL_ "GenSigTimeoutTime" BU_SG_REL_ AHL_AFL_HS SG_ 489 VehDynYawRate 250;
BA_REL_ "GenSigSuprvResp" BU_SG_REL_ ACC_HS SG_ 489 VehDynYawRate 1;
BA_REL_ "GenSigTimeoutMsg" BU_SG_REL_ ACC_HS SG_ 489 VehDynYawRate 489;
BA_REL_ "GenSigTimeoutTime" BU_SG_REL_ ACC_HS SG_ 489 VehDynYawRate 250;
BA_REL_ "GenSigRxStartValue" BU_SG_REL_ TCCM_HS SG_ 489 TrnsBrkSysCltchRelRqd "False";
BA_REL_ "GenSigRxStartValue" BU_SG_REL_ TCM_HS SG_ 489 TrnsBrkSysCltchRelRqd "False";
BA_REL_ "GenSigSuprvResp" BU_SG_REL_ TCM_HS SG_ 489 TrnsBrkSysCltchRelRqd 1;
BA_REL_ "GenSigTimeoutMsg" BU_SG_REL_ TCM_HS SG_ 489 TrnsBrkSysCltchRelRqd 489;
BA_REL_ "GenSigTimeoutTime" BU_SG_REL_ TCM_HS SG_ 489 TrnsBrkSysCltchRelRqd 50;
BA_REL_ "GenSigSuprvResp" BU_SG_REL_ EPS_HS SG_ 489 TracCntrlSysDrIntnt 1;
BA_REL_ "GenSigTimeoutMsg" BU_SG_REL_ EPS_HS SG_ 489 TracCntrlSysDrIntnt 489;
BA_REL_ "GenSigTimeoutTime" BU_SG_REL_ EPS_HS SG_ 489 TracCntrlSysDrIntnt 250;
BA_REL_ "GenSigSuprvResp" BU_SG_REL_ RDCM_HS SG_ 489 TracCntrlSysDrIntnt 1;
BA_REL_ "GenSigTimeoutMsg" BU_SG_REL_ RDCM_HS SG_ 489 TracCntrlSysDrIntnt 489;
BA_REL_ "GenSigTimeoutTime" BU_SG_REL_ RDCM_HS SG_ 489 TracCntrlSysDrIntnt 250;
BA_REL_ "GenSigSuprvResp" BU_SG_REL_ EOCM_F_HS SG_ 489 TCSysEnbld 1;
BA_REL_ "GenSigTimeoutMsg" BU_SG_REL_ EOCM_F_HS SG_ 489 TCSysEnbld 489;
BA_REL_ "GenSigTimeoutTime" BU_SG_REL_ EOCM_F_HS SG_ 489 TCSysEnbld 120;
BA_REL_ "GenSigSuprvResp" BU_SG_REL_ EOCM_F_HS SG_ 489 TCSysEnbld 1;
BA_REL_ "GenSigTimeoutTime" BU_SG_REL_ EOCM_F_HS SG_ 489 TCSysEnbld 120;
BA_REL_ "GenSigSuprvResp" BU_SG_REL_ ACC_HS SG_ 489 TCSysEnbld 1;
BA_REL_ "GenSigTimeoutTime" BU_SG_REL_ ACC_HS SG_ 489 TCSysEnbld 120;
BA_REL_ "GenSigSuprvResp" BU_SG_REL_ RDCM_HS SG_ 489 TCSysEnbld 1;
BA_REL_ "GenSigTimeoutMsg" BU_SG_REL_ RDCM_HS SG_ 489 TCSysEnbld 489;
BA_REL_ "GenSigTimeoutTime" BU_SG_REL_ RDCM_HS SG_ 489 TCSysEnbld 250;
BA_REL_ "GenSigSuprvResp" BU_SG_REL_ PTO_HS SG_ 489 TCSysAtv 1;
BA_REL_ "GenSigTimeoutMsg" BU_SG_REL_ PTO_HS SG_ 489 TCSysAtv 489;
BA_REL_ "GenSigTimeoutTime" BU_SG_REL_ PTO_HS SG_ 489 TCSysAtv 250;
BA_REL_ "GenSigSuprvResp" BU_SG_REL_ EOCM_F_HS SG_ 489 TCSysAtv 1;
BA_REL_ "GenSigTimeoutMsg" BU_SG_REL_ EOCM_F_HS SG_ 489 TCSysAtv 489;
BA_REL_ "GenSigTimeoutTime" BU_SG_REL_ EOCM_F_HS SG_ 489 TCSysAtv 120;
BA_REL_ "GenSigSuprvResp" BU_SG_REL_ EOCM_F_HS SG_ 489 TCSysAtv 1;
BA_REL_ "GenSigTimeoutTime" BU_SG_REL_ EOCM_F_HS SG_ 489 TCSysAtv 120;
BA_REL_ "GenSigSuprvResp" BU_SG_REL_ ACC_HS SG_ 489 TCSysAtv 1;
BA_REL_ "GenSigTimeoutTime" BU_SG_REL_ ACC_HS SG_ 489 TCSysAtv 120;
BA_REL_ "GenSigRxStartValue" BU_SG_REL_ ACC_HS SG_ 489 TCSysAtv "0";
BA_REL_ "GenSigSuprvResp" BU_SG_REL_ ACC_HS SG_ 489 TCSysAtv 1;
BA_REL_ "GenSigTimeoutMsg" BU_SG_REL_ ACC_HS SG_ 489 TCSysAtv 489;
BA_REL_ "GenSigTimeoutTime" BU_SG_REL_ ACC_HS SG_ 489 TCSysAtv 250;
BA_REL_ "GenSigSuprvResp" BU_SG_REL_ EOCM_F_HS SG_ 489 BrkPdlDrvAppPrsDetcd 1;
BA_REL_ "GenSigTimeoutMsg" BU_SG_REL_ EOCM_F_HS SG_ 489 BrkPdlDrvAppPrsDetcd 489;
BA_REL_ "GenSigTimeoutTime" BU_SG_REL_ EOCM_F_HS SG_ 489 BrkPdlDrvAppPrsDetcd 120;
BA_REL_ "GenSigSuprvResp" BU_SG_REL_ EOCM_F_HS SG_ 489 BrkPdlDrvAppPrsDetcd 1;
BA_REL_ "GenSigTimeoutTime" BU_SG_REL_ EOCM_F_HS SG_ 489 BrkPdlDrvAppPrsDetcd 120;
BA_REL_ "GenSigSuprvResp" BU_SG_REL_ ACC_HS SG_ 489 BrkPdlDrvAppPrsDetcd 1;
BA_REL_ "GenSigTimeoutMsg" BU_SG_REL_ ACC_HS SG_ 489 BrkPdlDrvAppPrsDetcd 489;
BA_REL_ "GenSigTimeoutTime" BU_SG_REL_ ACC_HS SG_ 489 BrkPdlDrvAppPrsDetcd 250;
BA_REL_ "GenSigSuprvResp" BU_SG_REL_ VES_HS SG_ 489 BrkPdlDrvAppPrsDetcd 1;
BA_REL_ "GenSigTimeoutMsg" BU_SG_REL_ VES_HS SG_ 489 BrkPdlDrvAppPrsDetcd 489;
BA_REL_ "GenSigTimeoutTime" BU_SG_REL_ VES_HS SG_ 489 BrkPdlDrvAppPrsDetcd 250;
BA_REL_ "GenSigSuprvResp" BU_SG_REL_ EPS_HS SG_ 489 BrkPdlDrvAppPrsDetcd 1;
BA_REL_ "GenSigTimeoutMsg" BU_SG_REL_ EPS_HS SG_ 489 BrkPdlDrvAppPrsDetcd 489;
BA_REL_ "GenSigTimeoutTime" BU_SG_REL_ EPS_HS SG_ 489 BrkPdlDrvAppPrsDetcd 250;
BA_REL_ "GenSigVBitResp" BU_SG_REL_ ECM_HS SG_ 489 BrkPdlDrvAppPrsDetcd 1;
BA_REL_ "GenSigSuprvResp" BU_SG_REL_ EOCM_F_HS SG_ 489 ACCBrkngAct 1;
BA_REL_ "GenSigTimeoutMsg" BU_SG_REL_ EOCM_F_HS SG_ 489 ACCBrkngAct 489;
BA_REL_ "GenSigTimeoutTime" BU_SG_REL_ EOCM_F_HS SG_ 489 ACCBrkngAct 120;
BA_REL_ "GenSigSuprvResp" BU_SG_REL_ EOCM_F_HS SG_ 489 ACCBrkngAct 1;
BA_REL_ "GenSigTimeoutTime" BU_SG_REL_ EOCM_F_HS SG_ 489 ACCBrkngAct 120;
BA_REL_ "GenSigSuprvResp" BU_SG_REL_ FCM_HS SG_ 489 ABSFld 1;
BA_REL_ "GenSigTimeoutMsg" BU_SG_REL_ FCM_HS SG_ 489 ABSFld 489;
BA_REL_ "GenSigTimeoutTime" BU_SG_REL_ FCM_HS SG_ 489 ABSFld 250;
BA_REL_ "GenSigSuprvResp" BU_SG_REL_ EOCM_F_HS SG_ 489 ABSFld 1;
BA_REL_ "GenSigTimeoutMsg" BU_SG_REL_ EOCM_F_HS SG_ 489 ABSFld 489;
BA_REL_ "GenSigTimeoutTime" BU_SG_REL_ EOCM_F_HS SG_ 489 ABSFld 120;
BA_REL_ "GenSigSuprvResp" BU_SG_REL_ EOCM_F_HS SG_ 489 ABSFld 1;
BA_REL_ "GenSigTimeoutTime" BU_SG_REL_ EOCM_F_HS SG_ 489 ABSFld 120;
BA_REL_ "GenSigSuprvResp" BU_SG_REL_ ACC_HS SG_ 489 ABSFld 1;
BA_REL_ "GenSigTimeoutMsg" BU_SG_REL_ ACC_HS SG_ 489 ABSFld 489;
BA_REL_ "GenSigTimeoutTime" BU_SG_REL_ ACC_HS SG_ 489 ABSFld 120;
BA_REL_ "GenSigSuprvResp" BU_SG_REL_ ACC_HS SG_ 489 ABSFld 1;
BA_REL_ "GenSigTimeoutTime" BU_SG_REL_ ACC_HS SG_ 489 ABSFld 120;
BA_REL_ "GenSigSuprvResp" BU_SG_REL_ ICCM_OBD_HS SG_ 489 ABSFld 1;
BA_REL_ "GenSigTimeoutMsg" BU_SG_REL_ ICCM_OBD_HS SG_ 489 ABSFld 489;
BA_REL_ "GenSigTimeoutTime" BU_SG_REL_ ICCM_OBD_HS SG_ 489 ABSFld 250;
BA_REL_ "GenSigSuprvResp" BU_SG_REL_ ICCM_HS SG_ 489 ABSFld 1;
BA_REL_ "GenSigTimeoutMsg" BU_SG_REL_ ICCM_HS SG_ 489 ABSFld 489;
BA_REL_ "GenSigTimeoutTime" BU_SG_REL_ ICCM_HS SG_ 489 ABSFld 250;
BA_REL_ "GenSigSuprvResp" BU_SG_REL_ EPB_HS SG_ 489 ABSFld 1;
BA_REL_ "GenSigTimeoutMsg" BU_SG_REL_ EPB_HS SG_ 489 ABSFld 489;
BA_REL_ "GenSigTimeoutTime" BU_SG_REL_ EPB_HS SG_ 489 ABSFld 50;
BA_REL_ "GenSigSuprvResp" BU_SG_REL_ EOCM_F_HS SG_ 489 ABSAtv 1;
BA_REL_ "GenSigTimeoutMsg" BU_SG_REL_ EOCM_F_HS SG_ 489 ABSAtv 489;
BA_REL_ "GenSigTimeoutTime" BU_SG_REL_ EOCM_F_HS SG_ 489 ABSAtv 120;
BA_REL_ "GenSigSuprvResp" BU_SG_REL_ EOCM_F_HS SG_ 489 ABSAtv 1;
BA_REL_ "GenSigTimeoutMsg" BU_SG_REL_ EOCM_F_HS SG_ 489 ABSAtv 489;
BA_REL_ "GenSigTimeoutTime" BU_SG_REL_ EOCM_F_HS SG_ 489 ABSAtv 120;
BA_REL_ "GenSigSuprvResp" BU_SG_REL_ EOCM_F_HS SG_ 489 ABSAtv 1;
BA_REL_ "GenSigTimeoutTime" BU_SG_REL_ EOCM_F_HS SG_ 489 ABSAtv 120;
BA_REL_ "GenSigSuprvResp" BU_SG_REL_ APPS_HS SG_ 489 ABSAtv 1;
BA_REL_ "GenSigTimeoutMsg" BU_SG_REL_ APPS_HS SG_ 489 ABSAtv 489;
BA_REL_ "GenSigTimeoutTime" BU_SG_REL_ APPS_HS SG_ 489 ABSAtv 250;
BA_REL_ "GenSigSuprvResp" BU_SG_REL_ SADS_HS SG_ 489 ABSAtv 1;
BA_REL_ "GenSigTimeoutMsg" BU_SG_REL_ SADS_HS SG_ 489 ABSAtv 489;
BA_REL_ "GenSigTimeoutTime" BU_SG_REL_ SADS_HS SG_ 489 ABSAtv 250;
BA_REL_ "GenSigSuprvResp" BU_SG_REL_ RDCM_HS SG_ 489 ABSAtv 1;
BA_REL_ "GenSigTimeoutMsg" BU_SG_REL_ RDCM_HS SG_ 489 ABSAtv 489;
BA_REL_ "GenSigTimeoutTime" BU_SG_REL_ RDCM_HS SG_ 489 ABSAtv 250;
BA_REL_ "GenSigSuprvResp" BU_SG_REL_ ACC_HS SG_ 489 ABSAtv 1;
BA_REL_ "GenSigTimeoutMsg" BU_SG_REL_ ACC_HS SG_ 489 ABSAtv 489;
BA_REL_ "GenSigTimeoutTime" BU_SG_REL_ ACC_HS SG_ 489 ABSAtv 120;
BA_REL_ "GenSigSuprvResp" BU_SG_REL_ ACC_HS SG_ 489 ABSAtv 1;
BA_REL_ "GenSigTimeoutTime" BU_SG_REL_ ACC_HS SG_ 489 ABSAtv 120;
BA_REL_ "GenSigSuprvResp" BU_SG_REL_ ACC_HS SG_ 489 ABSAtv 1;
BA_REL_ "GenSigTimeoutMsg" BU_SG_REL_ ACC_HS SG_ 489 ABSAtv 489;
BA_REL_ "GenSigTimeoutTime" BU_SG_REL_ ACC_HS SG_ 489 ABSAtv 250;
BA_REL_ "GenSigSuprvResp" BU_SG_REL_ BCM_HS SG_ 489 ABSAtv 1;
BA_REL_ "GenSigTimeoutMsg" BU_SG_REL_ BCM_HS SG_ 489 ABSAtv 489;
BA_REL_ "GenSigTimeoutTime" BU_SG_REL_ BCM_HS SG_ 489 ABSAtv 250;
BA_REL_ "GenSigSuprvResp" BU_SG_REL_ BCM_HS SG_ 489 ABSAtv 1;
BA_REL_ "GenSigTimeoutMsg" BU_SG_REL_ BCM_HS SG_ 489 ABSAtv 489;
BA_REL_ "GenSigTimeoutTime" BU_SG_REL_ BCM_HS SG_ 489 ABSAtv 250;
BA_REL_ "GenSigSuprvResp" BU_SG_REL_ TCCM_HS SG_ 489 ABSAtv 1;
BA_REL_ "GenSigTimeoutMsg" BU_SG_REL_ TCCM_HS SG_ 489 ABSAtv 489;
BA_REL_ "GenSigTimeoutTime" BU_SG_REL_ TCCM_HS SG_ 489 ABSAtv 250;
BA_REL_ "GenSigSuprvResp" BU_SG_REL_ TCCM_HS SG_ 489 ABSAtv 1;
BA_REL_ "GenSigTimeoutMsg" BU_SG_REL_ TCCM_HS SG_ 489 ABSAtv 489;
BA_REL_ "GenSigTimeoutTime" BU_SG_REL_ TCCM_HS SG_ 489 ABSAtv 250;
BA_REL_ "GenSigSuprvResp" BU_SG_REL_ BCM_HS SG_ 381 HillDesCtrlRedVehSpIO 1;
BA_REL_ "GenSigTimeoutMsg" BU_SG_REL_ BCM_HS SG_ 381 HillDesCtrlRedVehSpIO 381;
BA_REL_ "GenSigTimeoutTime" BU_SG_REL_ BCM_HS SG_ 381 HillDesCtrlRedVehSpIO 250;
BA_REL_ "GenSigSuprvResp" BU_SG_REL_ RDCM_HS SG_ 381 StWhAnVDA 1;
BA_REL_ "GenSigSuprvResp" BU_SG_REL_ ONSTAR_HS SG_ 381 StWhAnVDA 1;
BA_REL_ "GenSigSuprvResp" BU_SG_REL_ ACC_HS SG_ 381 StWhAnVDA 1;
BA_REL_ "GenSigSuprvResp" BU_SG_REL_ AHL_AFL_HS SG_ 381 StWhAnVDA 1;
BA_REL_ "GenSigSuprvResp" BU_SG_REL_ EPB_HS SG_ 381 StWhAnVDA 1;
BA_REL_ "GenSigSuprvResp" BU_SG_REL_ BCM_HS SG_ 381 StWhAnVDA 2;
BA_REL_ "GenSigTimeoutMsg" BU_SG_REL_ BCM_HS SG_ 381 StWhAnVDA 381;
BA_REL_ "GenSigTimeoutTime" BU_SG_REL_ BCM_HS SG_ 381 StWhAnVDA 250;
BA_REL_ "GenSigSuprvResp" BU_SG_REL_ BCM_HS SG_ 381 StWhAnVDA 2;
BA_REL_ "GenSigTimeoutMsg" BU_SG_REL_ BCM_HS SG_ 381 StWhAnVDA 381;
BA_REL_ "GenSigTimeoutTime" BU_SG_REL_ BCM_HS SG_ 381 StWhAnVDA 250;
BA_REL_ "GenSigSuprvResp" BU_SG_REL_ BCM_HS SG_ 381 TirePrsLowIO 1;
BA_REL_ "GenSigTimeoutMsg" BU_SG_REL_ BCM_HS SG_ 381 TirePrsLowIO 381;
BA_REL_ "GenSigTimeoutTime" BU_SG_REL_ BCM_HS SG_ 381 TirePrsLowIO 250;
BA_REL_ "GenSigSuprvResp" BU_SG_REL_ ECM_HS SG_ 381 ActVehAccel 1;
BA_REL_ "GenSigTimeoutMsg" BU_SG_REL_ ECM_HS SG_ 381 ActVehAccel 381;
BA_REL_ "GenSigTimeoutTime" BU_SG_REL_ ECM_HS SG_ 381 ActVehAccel 250;
BA_REL_ "GenSigSuprvResp" BU_SG_REL_ BSM_HS SG_ 381 ActVehAccel 1;
BA_REL_ "GenSigTimeoutMsg" BU_SG_REL_ BSM_HS SG_ 381 ActVehAccel 381;
BA_REL_ "GenSigTimeoutTime" BU_SG_REL_ BSM_HS SG_ 381 ActVehAccel 250;
BA_REL_ "GenSigSuprvResp" BU_SG_REL_ VICM_HS SG_ 381 ActVehAccel 1;
BA_REL_ "GenSigTimeoutMsg" BU_SG_REL_ VICM_HS SG_ 381 ActVehAccel 381;
BA_REL_ "GenSigTimeoutTime" BU_SG_REL_ VICM_HS SG_ 381 ActVehAccel 250;
BA_REL_ "GenSigSuprvResp" BU_SG_REL_ EOCM_F_HS SG_ 381 ActVehAccel 1;
BA_REL_ "GenSigTimeoutMsg" BU_SG_REL_ EOCM_F_HS SG_ 381 ActVehAccel 381;
BA_REL_ "GenSigTimeoutTime" BU_SG_REL_ EOCM_F_HS SG_ 381 ActVehAccel 250;
BA_REL_ "GenSigSuprvResp" BU_SG_REL_ FCM_HS SG_ 381 ActVehAccel 1;
BA_REL_ "GenSigTimeoutMsg" BU_SG_REL_ FCM_HS SG_ 381 ActVehAccel 381;
BA_REL_ "GenSigTimeoutTime" BU_SG_REL_ FCM_HS SG_ 381 ActVehAccel 250;
BA_REL_ "GenSigSuprvResp" BU_SG_REL_ ACC_HS SG_ 381 ActVehAccel 1;
BA_REL_ "GenSigTimeoutMsg" BU_SG_REL_ ACC_HS SG_ 381 ActVehAccel 381;
BA_REL_ "GenSigTimeoutTime" BU_SG_REL_ ACC_HS SG_ 381 ActVehAccel 250;
BA_REL_ "GenSigSuprvResp" BU_SG_REL_ EOCM_F_HS SG_ 381 BksOvht 1;
BA_REL_ "GenSigTimeoutMsg" BU_SG_REL_ EOCM_F_HS SG_ 381 BksOvht 381;
BA_REL_ "GenSigTimeoutTime" BU_SG_REL_ EOCM_F_HS SG_ 381 BksOvht 250;
BA_REL_ "GenSigSuprvResp" BU_SG_REL_ EOCM_F_HS SG_ 381 BksOvht 1;
BA_REL_ "GenSigTimeoutMsg" BU_SG_REL_ EOCM_F_HS SG_ 381 BksOvht 381;
BA_REL_ "GenSigTimeoutTime" BU_SG_REL_ EOCM_F_HS SG_ 381 BksOvht 250;
BA_REL_ "GenSigSuprvResp" BU_SG_REL_ APPS_HS SG_ 381 ABSPr 1;
BA_REL_ "GenSigTimeoutMsg" BU_SG_REL_ APPS_HS SG_ 381 ABSPr 381;
BA_REL_ "GenSigTimeoutTime" BU_SG_REL_ APPS_HS SG_ 381 ABSPr 250;
BA_REL_ "GenSigSuprvResp" BU_SG_REL_ BCM_HS SG_ 381 TreInfMonSysRstPrfmd 1;
BA_REL_ "GenSigTimeoutMsg" BU_SG_REL_ BCM_HS SG_ 381 TreInfMonSysRstPrfmd 381;
BA_REL_ "GenSigTimeoutTime" BU_SG_REL_ BCM_HS SG_ 381 TreInfMonSysRstPrfmd 250;
BA_REL_ "GenSigSuprvResp" BU_SG_REL_ EOCM_F_HS SG_ 381 ABSIO 1;
BA_REL_ "GenSigTimeoutMsg" BU_SG_REL_ EOCM_F_HS SG_ 381 ABSIO 381;
BA_REL_ "GenSigTimeoutTime" BU_SG_REL_ EOCM_F_HS SG_ 381 ABSIO 250;
BA_REL_ "GenSigSuprvResp" BU_SG_REL_ BCM_HS SG_ 381 ABSIO 1;
BA_REL_ "GenSigTimeoutMsg" BU_SG_REL_ BCM_HS SG_ 381 ABSIO 381;
BA_REL_ "GenSigTimeoutTime" BU_SG_REL_ BCM_HS SG_ 381 ABSIO 250;
BA_REL_ "GenSigSuprvResp" BU_SG_REL_ BCM_HS SG_ 381 BrkPadWrnIO 1;
BA_REL_ "GenSigTimeoutMsg" BU_SG_REL_ BCM_HS SG_ 381 BrkPadWrnIO 381;
BA_REL_ "GenSigTimeoutTime" BU_SG_REL_ BCM_HS SG_ 381 BrkPadWrnIO 250;
BA_REL_ "GenSigRxStartValue" BU_SG_REL_ ACC_HS SG_ 381 VehStabEnhmntMd "0";
BA_REL_ "GenSigSuprvResp" BU_SG_REL_ ACC_HS SG_ 381 VehStabEnhmntMd 1;
BA_REL_ "GenSigTimeoutMsg" BU_SG_REL_ ACC_HS SG_ 381 VehStabEnhmntMd 381;
BA_REL_ "GenSigTimeoutTime" BU_SG_REL_ ACC_HS SG_ 381 VehStabEnhmntMd 250;
BA_REL_ "GenSigSuprvResp" BU_SG_REL_ EOCM_F_HS SG_ 381 VehStabEnhmntMd 1;
BA_REL_ "GenSigTimeoutMsg" BU_SG_REL_ EOCM_F_HS SG_ 381 VehStabEnhmntMd 381;
BA_REL_ "GenSigTimeoutTime" BU_SG_REL_ EOCM_F_HS SG_ 381 VehStabEnhmntMd 250;
BA_REL_ "GenSigSuprvResp" BU_SG_REL_ TCCM_HS SG_ 381 VehStabEnhmntMd 1;
BA_REL_ "GenSigTimeoutMsg" BU_SG_REL_ TCCM_HS SG_ 381 VehStabEnhmntMd 381;
BA_REL_ "GenSigTimeoutTime" BU_SG_REL_ TCCM_HS SG_ 381 VehStabEnhmntMd 250;
BA_REL_ "GenSigRxStartValue" BU_SG_REL_ RDCM_HS SG_ 381 VehStabEnhmntMd "$1 - Normal";
BA_REL_ "GenSigSuprvResp" BU_SG_REL_ RDCM_HS SG_ 381 VehStabEnhmntMd 1;
BA_REL_ "GenSigTimeoutMsg" BU_SG_REL_ RDCM_HS SG_ 381 VehStabEnhmntMd 381;
BA_REL_ "GenSigTimeoutTime" BU_SG_REL_ RDCM_HS SG_ 381 VehStabEnhmntMd 250;
BA_REL_ "GenSigRxStartValue" BU_SG_REL_ BCM_HS SG_ 381 VehStabEnhmntMd "$1 - Normal";
BA_REL_ "GenSigSuprvResp" BU_SG_REL_ BCM_HS SG_ 381 VehStabEnhmntMd 1;
BA_REL_ "GenSigTimeoutMsg" BU_SG_REL_ BCM_HS SG_ 381 VehStabEnhmntMd 381;
BA_REL_ "GenSigTimeoutTime" BU_SG_REL_ BCM_HS SG_ 381 VehStabEnhmntMd 250;
BA_REL_ "GenSigSuprvResp" BU_SG_REL_ EPS_HS SG_ 381 VehStabEnhmntStat 1;
BA_REL_ "GenSigTimeoutMsg" BU_SG_REL_ EPS_HS SG_ 381 VehStabEnhmntStat 381;
BA_REL_ "GenSigTimeoutTime" BU_SG_REL_ EPS_HS SG_ 381 VehStabEnhmntStat 250;
BA_REL_ "GenSigSuprvResp" BU_SG_REL_ FCM_HS SG_ 381 VehStabEnhmntStat 1;
BA_REL_ "GenSigTimeoutMsg" BU_SG_REL_ FCM_HS SG_ 381 VehStabEnhmntStat 381;
BA_REL_ "GenSigTimeoutTime" BU_SG_REL_ FCM_HS SG_ 381 VehStabEnhmntStat 250;
BA_REL_ "GenSigRxStartValue" BU_SG_REL_ ACC_HS SG_ 381 VehStabEnhmntStat "0";
BA_REL_ "GenSigSuprvResp" BU_SG_REL_ ACC_HS SG_ 381 VehStabEnhmntStat 1;
BA_REL_ "GenSigTimeoutMsg" BU_SG_REL_ ACC_HS SG_ 381 VehStabEnhmntStat 381;
BA_REL_ "GenSigTimeoutTime" BU_SG_REL_ ACC_HS SG_ 381 VehStabEnhmntStat 250;
BA_REL_ "GenSigSuprvResp" BU_SG_REL_ EOCM_F_HS SG_ 381 VehStabEnhmntStat 1;
BA_REL_ "GenSigTimeoutMsg" BU_SG_REL_ EOCM_F_HS SG_ 381 VehStabEnhmntStat 381;
BA_REL_ "GenSigTimeoutTime" BU_SG_REL_ EOCM_F_HS SG_ 381 VehStabEnhmntStat 250;
BA_REL_ "GenSigSuprvResp" BU_SG_REL_ EOCM_F_HS SG_ 381 VehStabEnhmntStat 1;
BA_REL_ "GenSigTimeoutMsg" BU_SG_REL_ EOCM_F_HS SG_ 381 VehStabEnhmntStat 381;
BA_REL_ "GenSigTimeoutTime" BU_SG_REL_ EOCM_F_HS SG_ 381 VehStabEnhmntStat 250;
BA_REL_ "GenSigSuprvResp" BU_SG_REL_ BCM_HS SG_ 381 VehStabEnhmntStat 1;
BA_REL_ "GenSigTimeoutMsg" BU_SG_REL_ BCM_HS SG_ 381 VehStabEnhmntStat 381;
BA_REL_ "GenSigTimeoutTime" BU_SG_REL_ BCM_HS SG_ 381 VehStabEnhmntStat 250;
BA_REL_ "GenSigSuprvResp" BU_SG_REL_ SADS_HS SG_ 381 TCSysOpMd 1;
BA_REL_ "GenSigTimeoutMsg" BU_SG_REL_ SADS_HS SG_ 381 TCSysOpMd 381;
BA_REL_ "GenSigTimeoutTime" BU_SG_REL_ SADS_HS SG_ 381 TCSysOpMd 250;
BA_REL_ "GenSigSuprvResp" BU_SG_REL_ EPS_HS SG_ 381 TCSysOpMd 1;
BA_REL_ "GenSigTimeoutMsg" BU_SG_REL_ EPS_HS SG_ 381 TCSysOpMd 381;
BA_REL_ "GenSigTimeoutTime" BU_SG_REL_ EPS_HS SG_ 381 TCSysOpMd 250;
BA_REL_ "GenSigRxStartValue" BU_SG_REL_ ACC_HS SG_ 381 TCSysOpMd "0";
BA_REL_ "GenSigSuprvResp" BU_SG_REL_ ACC_HS SG_ 381 TCSysOpMd 1;
BA_REL_ "GenSigTimeoutMsg" BU_SG_REL_ ACC_HS SG_ 381 TCSysOpMd 381;
BA_REL_ "GenSigTimeoutTime" BU_SG_REL_ ACC_HS SG_ 381 TCSysOpMd 250;
BA_REL_ "GenSigSuprvResp" BU_SG_REL_ EOCM_F_HS SG_ 381 TCSysOpMd 1;
BA_REL_ "GenSigTimeoutMsg" BU_SG_REL_ EOCM_F_HS SG_ 381 TCSysOpMd 381;
BA_REL_ "GenSigTimeoutTime" BU_SG_REL_ EOCM_F_HS SG_ 381 TCSysOpMd 250;
BA_REL_ "GenSigRxStartValue" BU_SG_REL_ RDCM_HS SG_ 381 TCSysOpMd "$1 - Normal";
BA_REL_ "GenSigRxStartValue" BU_SG_REL_ BCM_HS SG_ 381 TCSysOpMd "$1 - Normal";
BA_REL_ "GenSigSuprvResp" BU_SG_REL_ BCM_HS SG_ 381 TCSysOpMd 1;
BA_REL_ "GenSigTimeoutMsg" BU_SG_REL_ BCM_HS SG_ 381 TCSysOpMd 381;
BA_REL_ "GenSigTimeoutTime" BU_SG_REL_ BCM_HS SG_ 381 TCSysOpMd 250;
BA_REL_ "GenSigSuprvResp" BU_SG_REL_ SADS_HS SG_ 381 TCSysOpStat 1;
BA_REL_ "GenSigTimeoutMsg" BU_SG_REL_ SADS_HS SG_ 381 TCSysOpStat 381;
BA_REL_ "GenSigTimeoutTime" BU_SG_REL_ SADS_HS SG_ 381 TCSysOpStat 250;
BA_REL_ "GenSigRxStartValue" BU_SG_REL_ ACC_HS SG_ 381 TCSysOpStat "0";
BA_REL_ "GenSigSuprvResp" BU_SG_REL_ ACC_HS SG_ 381 TCSysOpStat 1;
BA_REL_ "GenSigTimeoutMsg" BU_SG_REL_ ACC_HS SG_ 381 TCSysOpStat 381;
BA_REL_ "GenSigTimeoutTime" BU_SG_REL_ ACC_HS SG_ 381 TCSysOpStat 250;
BA_REL_ "GenSigSuprvResp" BU_SG_REL_ EOCM_F_HS SG_ 381 TCSysOpStat 1;
BA_REL_ "GenSigTimeoutMsg" BU_SG_REL_ EOCM_F_HS SG_ 381 TCSysOpStat 381;
BA_REL_ "GenSigTimeoutTime" BU_SG_REL_ EOCM_F_HS SG_ 381 TCSysOpStat 250;
BA_REL_ "GenSigSuprvResp" BU_SG_REL_ BCM_HS SG_ 381 TCSysOpStat 1;
BA_REL_ "GenSigTimeoutMsg" BU_SG_REL_ BCM_HS SG_ 381 TCSysOpStat 381;
BA_REL_ "GenSigTimeoutTime" BU_SG_REL_ BCM_HS SG_ 381 TCSysOpStat 250;
BA_REL_ "GenSigSuprvRespSubValue" BU_SG_REL_ BCM_HS SG_ 381 BrkSysVTopSpdLimVal 255;
BA_REL_ "GenSigSuprvResp" BU_SG_REL_ BCM_HS SG_ 381 BrkSysVTopSpdLimVal 2;
BA_REL_ "GenSigTimeoutMsg" BU_SG_REL_ BCM_HS SG_ 381 BrkSysVTopSpdLimVal 381;
BA_REL_ "GenSigTimeoutTime" BU_SG_REL_ BCM_HS SG_ 381 BrkSysVTopSpdLimVal 250;
BA_REL_ "GenSigSuprvResp" BU_SG_REL_ BCM_HS SG_ 381 BrkSysBrkLtsReqd 2;
BA_REL_ "GenSigTimeoutMsg" BU_SG_REL_ BCM_HS SG_ 381 BrkSysBrkLtsReqd 381;
BA_REL_ "GenSigTimeoutTime" BU_SG_REL_ BCM_HS SG_ 381 BrkSysBrkLtsReqd 250;
BA_REL_ "GenSigSuprvResp" BU_SG_REL_ EBCM_OBD_HS SG_ 241 NotEventStat 1;
BA_REL_ "GenSigTimeoutMsg" BU_SG_REL_ EBCM_OBD_HS SG_ 241 NotEventStat 241;
BA_REL_ "GenSigTimeoutTime" BU_SG_REL_ EBCM_OBD_HS SG_ 241 NotEventStat 250;
BA_REL_ "GenSigSuprvResp" BU_SG_REL_ EBCM_HS SG_ 241 NotEventStat 1;
BA_REL_ "GenSigTimeoutMsg" BU_SG_REL_ EBCM_HS SG_ 241 NotEventStat 241;
BA_REL_ "GenSigTimeoutTime" BU_SG_REL_ EBCM_HS SG_ 241 NotEventStat 250;
BA_REL_ "GenSigSuprvResp" BU_SG_REL_ VES_HS SG_ 241 NotEventStat 1;
BA_REL_ "GenSigTimeoutMsg" BU_SG_REL_ VES_HS SG_ 241 NotEventStat 241;
BA_REL_ "GenSigTimeoutTime" BU_SG_REL_ VES_HS SG_ 241 NotEventStat 250;
BA_REL_ "GenSigSuprvResp" BU_SG_REL_ EPS_HS SG_ 241 NotEventStat 1;
BA_REL_ "GenSigTimeoutMsg" BU_SG_REL_ EPS_HS SG_ 241 NotEventStat 241;
BA_REL_ "GenSigTimeoutTime" BU_SG_REL_ EPS_HS SG_ 241 NotEventStat 250;
BA_REL_ "GenSigSuprvResp" BU_SG_REL_ FCM_HS SG_ 241 BrkPdlChkData 1;
BA_REL_ "GenSigTimeoutMsg" BU_SG_REL_ FCM_HS SG_ 241 BrkPdlChkData 241;
BA_REL_ "GenSigTimeoutTime" BU_SG_REL_ FCM_HS SG_ 241 BrkPdlChkData 250;
BA_REL_ "GenSigSuprvResp" BU_SG_REL_ CGM_HS SG_ 241 BrkPdlChkData 1;
BA_REL_ "GenSigTimeoutMsg" BU_SG_REL_ CGM_HS SG_ 241 BrkPdlChkData 241;
BA_REL_ "GenSigTimeoutTime" BU_SG_REL_ CGM_HS SG_ 241 BrkPdlChkData 250;
BA_REL_ "GenSigSuprvResp" BU_SG_REL_ ACC_HS SG_ 241 BrkPdlChkData 1;
BA_REL_ "GenSigTimeoutMsg" BU_SG_REL_ ACC_HS SG_ 241 BrkPdlChkData 241;
BA_REL_ "GenSigTimeoutTime" BU_SG_REL_ ACC_HS SG_ 241 BrkPdlChkData 250;
BA_REL_ "GenSigSuprvResp" BU_SG_REL_ CGM_HS SG_ 241 BrkAppSnsrHmPosLrnd 1;
BA_REL_ "GenSigTimeoutMsg" BU_SG_REL_ CGM_HS SG_ 241 BrkAppSnsrHmPosLrnd 241;
BA_REL_ "GenSigTimeoutTime" BU_SG_REL_ CGM_HS SG_ 241 BrkAppSnsrHmPosLrnd 250;
BA_REL_ "GenSigSuprvResp" BU_SG_REL_ EOCM_F_HS SG_ 241 BrkAppSnsrHmPosLrnd 1;
BA_REL_ "GenSigTimeoutMsg" BU_SG_REL_ EOCM_F_HS SG_ 241 BrkAppSnsrHmPosLrnd 241;
BA_REL_ "GenSigTimeoutTime" BU_SG_REL_ EOCM_F_HS SG_ 241 BrkAppSnsrHmPosLrnd 120;
BA_REL_ "GenSigSuprvResp" BU_SG_REL_ FCM_HS SG_ 241 BrkAppSnsrHmPosLrnd 1;
BA_REL_ "GenSigTimeoutMsg" BU_SG_REL_ FCM_HS SG_ 241 BrkAppSnsrHmPosLrnd 241;
BA_REL_ "GenSigTimeoutTime" BU_SG_REL_ FCM_HS SG_ 241 BrkAppSnsrHmPosLrnd 250;
BA_REL_ "GenSigSuprvResp" BU_SG_REL_ VES_HS SG_ 241 BrkAppSnsrHmPosLrnd 1;
BA_REL_ "GenSigTimeoutMsg" BU_SG_REL_ VES_HS SG_ 241 BrkAppSnsrHmPosLrnd 241;
BA_REL_ "GenSigTimeoutTime" BU_SG_REL_ VES_HS SG_ 241 BrkAppSnsrHmPosLrnd 250;
BA_REL_ "GenSigSuprvResp" BU_SG_REL_ EPS_HS SG_ 241 BrkAppSnsrHmPosLrnd 1;
BA_REL_ "GenSigTimeoutMsg" BU_SG_REL_ EPS_HS SG_ 241 BrkAppSnsrHmPosLrnd 241;
BA_REL_ "GenSigTimeoutTime" BU_SG_REL_ EPS_HS SG_ 241 BrkAppSnsrHmPosLrnd 250;
BA_REL_ "GenSigSuprvResp" BU_SG_REL_ EBCM_OBD_HS SG_ 241 BrkAppSnsrHmPosLrnd 1;
BA_REL_ "GenSigTimeoutMsg" BU_SG_REL_ EBCM_OBD_HS SG_ 241 BrkAppSnsrHmPosLrnd 241;
BA_REL_ "GenSigTimeoutTime" BU_SG_REL_ EBCM_OBD_HS SG_ 241 BrkAppSnsrHmPosLrnd 250;
BA_REL_ "GenSigSuprvResp" BU_SG_REL_ EBCM_HS SG_ 241 BrkAppSnsrHmPosLrnd 1;
BA_REL_ "GenSigTimeoutMsg" BU_SG_REL_ EBCM_HS SG_ 241 BrkAppSnsrHmPosLrnd 241;
BA_REL_ "GenSigTimeoutTime" BU_SG_REL_ EBCM_HS SG_ 241 BrkAppSnsrHmPosLrnd 250;
BA_REL_ "GenSigSuprvResp" BU_SG_REL_ HCP_B_HS SG_ 241 BrkPedTrvlAchvd 1;
BA_REL_ "GenSigTimeoutMsg" BU_SG_REL_ HCP_B_HS SG_ 241 BrkPedTrvlAchvd 241;
BA_REL_ "GenSigTimeoutTime" BU_SG_REL_ HCP_B_HS SG_ 241 BrkPedTrvlAchvd 250;
BA_REL_ "GenSigSuprvResp" BU_SG_REL_ CGM_HS SG_ 241 BrkPedTrvlAchvd 1;
BA_REL_ "GenSigTimeoutMsg" BU_SG_REL_ CGM_HS SG_ 241 BrkPedTrvlAchvd 241;
BA_REL_ "GenSigTimeoutTime" BU_SG_REL_ CGM_HS SG_ 241 BrkPedTrvlAchvd 250;
BA_REL_ "GenSigSuprvResp" BU_SG_REL_ HCP_T_HS SG_ 241 BrkPedTrvlAchvd 1;
BA_REL_ "GenSigTimeoutMsg" BU_SG_REL_ HCP_T_HS SG_ 241 BrkPedTrvlAchvd 241;
BA_REL_ "GenSigTimeoutTime" BU_SG_REL_ HCP_T_HS SG_ 241 BrkPedTrvlAchvd 250;
BA_REL_ "GenSigSuprvResp" BU_SG_REL_ PTO_HS SG_ 241 BrkPedTrvlAchvd 1;
BA_REL_ "GenSigTimeoutMsg" BU_SG_REL_ PTO_HS SG_ 241 BrkPedTrvlAchvd 241;
BA_REL_ "GenSigTimeoutTime" BU_SG_REL_ PTO_HS SG_ 241 BrkPedTrvlAchvd 250;
BA_REL_ "GenSigSuprvResp" BU_SG_REL_ BSM_HS SG_ 241 BrkPedTrvlAchvd 1;
BA_REL_ "GenSigTimeoutMsg" BU_SG_REL_ BSM_HS SG_ 241 BrkPedTrvlAchvd 241;
BA_REL_ "GenSigTimeoutTime" BU_SG_REL_ BSM_HS SG_ 241 BrkPedTrvlAchvd 250;
BA_REL_ "GenSigSuprvResp" BU_SG_REL_ VICM_HS SG_ 241 BrkPedTrvlAchvd 1;
BA_REL_ "GenSigTimeoutMsg" BU_SG_REL_ VICM_HS SG_ 241 BrkPedTrvlAchvd 241;
BA_REL_ "GenSigTimeoutTime" BU_SG_REL_ VICM_HS SG_ 241 BrkPedTrvlAchvd 250;
BA_REL_ "GenSigSuprvResp" BU_SG_REL_ APPS_HS SG_ 241 BrkPedTrvlAchvd 1;
BA_REL_ "GenSigTimeoutMsg" BU_SG_REL_ APPS_HS SG_ 241 BrkPedTrvlAchvd 241;
BA_REL_ "GenSigTimeoutTime" BU_SG_REL_ APPS_HS SG_ 241 BrkPedTrvlAchvd 250;
BA_REL_ "GenSigSuprvResp" BU_SG_REL_ VES_HS SG_ 241 BrkPedTrvlAchvd 1;
BA_REL_ "GenSigTimeoutMsg" BU_SG_REL_ VES_HS SG_ 241 BrkPedTrvlAchvd 241;
BA_REL_ "GenSigTimeoutTime" BU_SG_REL_ VES_HS SG_ 241 BrkPedTrvlAchvd 250;
BA_REL_ "GenSigSuprvResp" BU_SG_REL_ EPS_HS SG_ 241 BrkPedTrvlAchvd 1;
BA_REL_ "GenSigTimeoutMsg" BU_SG_REL_ EPS_HS SG_ 241 BrkPedTrvlAchvd 241;
BA_REL_ "GenSigTimeoutTime" BU_SG_REL_ EPS_HS SG_ 241 BrkPedTrvlAchvd 250;
BA_REL_ "GenSigSuprvResp" BU_SG_REL_ EOCM_F_HS SG_ 241 BrkPedTrvlAchvd 1;
BA_REL_ "GenSigTimeoutMsg" BU_SG_REL_ EOCM_F_HS SG_ 241 BrkPedTrvlAchvd 241;
BA_REL_ "GenSigTimeoutTime" BU_SG_REL_ EOCM_F_HS SG_ 241 BrkPedTrvlAchvd 120;
BA_REL_ "GenSigSuprvResp" BU_SG_REL_ EOCM_F_HS SG_ 241 BrkPedTrvlAchvd 1;
BA_REL_ "GenSigTimeoutMsg" BU_SG_REL_ EOCM_F_HS SG_ 241 BrkPedTrvlAchvd 241;
BA_REL_ "GenSigTimeoutTime" BU_SG_REL_ EOCM_F_HS SG_ 241 BrkPedTrvlAchvd 120;
BA_REL_ "GenSigSuprvResp" BU_SG_REL_ EPB_HS SG_ 241 BrkPedTrvlAchvd 1;
BA_REL_ "GenSigTimeoutMsg" BU_SG_REL_ EPB_HS SG_ 241 BrkPedTrvlAchvd 241;
BA_REL_ "GenSigTimeoutTime" BU_SG_REL_ EPB_HS SG_ 241 BrkPedTrvlAchvd 25;
BA_REL_ "GenSigSuprvResp" BU_SG_REL_ ACC_HS SG_ 241 BrkPedTrvlAchvd 1;
BA_REL_ "GenSigTimeoutMsg" BU_SG_REL_ ACC_HS SG_ 241 BrkPedTrvlAchvd 241;
BA_REL_ "GenSigTimeoutTime" BU_SG_REL_ ACC_HS SG_ 241 BrkPedTrvlAchvd 25;
BA_REL_ "GenSigSuprvResp" BU_SG_REL_ RDCM_HS SG_ 241 BrkPedTrvlAchvd 1;
BA_REL_ "GenSigTimeoutMsg" BU_SG_REL_ RDCM_HS SG_ 241 BrkPedTrvlAchvd 241;
BA_REL_ "GenSigTimeoutTime" BU_SG_REL_ RDCM_HS SG_ 241 BrkPedTrvlAchvd 250;
BA_REL_ "GenSigSuprvResp" BU_SG_REL_ HCP_B_HS SG_ 241 BrkPedTrvlAchvdV 1;
BA_REL_ "GenSigTimeoutMsg" BU_SG_REL_ HCP_B_HS SG_ 241 BrkPedTrvlAchvdV 241;
BA_REL_ "GenSigTimeoutTime" BU_SG_REL_ HCP_B_HS SG_ 241 BrkPedTrvlAchvdV 250;
BA_REL_ "GenSigSuprvResp" BU_SG_REL_ CGM_HS SG_ 241 BrkPedTrvlAchvdV 1;
BA_REL_ "GenSigTimeoutMsg" BU_SG_REL_ CGM_HS SG_ 241 BrkPedTrvlAchvdV 241;
BA_REL_ "GenSigTimeoutTime" BU_SG_REL_ CGM_HS SG_ 241 BrkPedTrvlAchvdV 250;
BA_REL_ "GenSigSuprvResp" BU_SG_REL_ HCP_T_HS SG_ 241 BrkPedTrvlAchvdV 1;
BA_REL_ "GenSigTimeoutMsg" BU_SG_REL_ HCP_T_HS SG_ 241 BrkPedTrvlAchvdV 241;
BA_REL_ "GenSigTimeoutTime" BU_SG_REL_ HCP_T_HS SG_ 241 BrkPedTrvlAchvdV 250;
BA_REL_ "GenSigSuprvResp" BU_SG_REL_ PTO_HS SG_ 241 BrkPedTrvlAchvdV 1;
BA_REL_ "GenSigTimeoutMsg" BU_SG_REL_ PTO_HS SG_ 241 BrkPedTrvlAchvdV 241;
BA_REL_ "GenSigTimeoutTime" BU_SG_REL_ PTO_HS SG_ 241 BrkPedTrvlAchvdV 250;
BA_REL_ "GenSigSuprvResp" BU_SG_REL_ BSM_HS SG_ 241 BrkPedTrvlAchvdV 1;
BA_REL_ "GenSigTimeoutMsg" BU_SG_REL_ BSM_HS SG_ 241 BrkPedTrvlAchvdV 241;
BA_REL_ "GenSigTimeoutTime" BU_SG_REL_ BSM_HS SG_ 241 BrkPedTrvlAchvdV 250;
BA_REL_ "GenSigSuprvResp" BU_SG_REL_ VICM_HS SG_ 241 BrkPedTrvlAchvdV 1;
BA_REL_ "GenSigTimeoutMsg" BU_SG_REL_ VICM_HS SG_ 241 BrkPedTrvlAchvdV 241;
BA_REL_ "GenSigTimeoutTime" BU_SG_REL_ VICM_HS SG_ 241 BrkPedTrvlAchvdV 250;
BA_REL_ "GenSigSuprvResp" BU_SG_REL_ APPS_HS SG_ 241 BrkPedTrvlAchvdV 1;
BA_REL_ "GenSigTimeoutMsg" BU_SG_REL_ APPS_HS SG_ 241 BrkPedTrvlAchvdV 241;
BA_REL_ "GenSigTimeoutTime" BU_SG_REL_ APPS_HS SG_ 241 BrkPedTrvlAchvdV 250;
BA_REL_ "GenSigSuprvResp" BU_SG_REL_ VES_HS SG_ 241 BrkPedTrvlAchvdV 1;
BA_REL_ "GenSigTimeoutMsg" BU_SG_REL_ VES_HS SG_ 241 BrkPedTrvlAchvdV 241;
BA_REL_ "GenSigTimeoutTime" BU_SG_REL_ VES_HS SG_ 241 BrkPedTrvlAchvdV 250;
BA_REL_ "GenSigSuprvResp" BU_SG_REL_ EPS_HS SG_ 241 BrkPedTrvlAchvdV 1;
BA_REL_ "GenSigTimeoutMsg" BU_SG_REL_ EPS_HS SG_ 241 BrkPedTrvlAchvdV 241;
BA_REL_ "GenSigTimeoutTime" BU_SG_REL_ EPS_HS SG_ 241 BrkPedTrvlAchvdV 250;
BA_REL_ "GenSigSuprvResp" BU_SG_REL_ EOCM_F_HS SG_ 241 BrkPedTrvlAchvdV 1;
BA_REL_ "GenSigTimeoutMsg" BU_SG_REL_ EOCM_F_HS SG_ 241 BrkPedTrvlAchvdV 241;
BA_REL_ "GenSigTimeoutTime" BU_SG_REL_ EOCM_F_HS SG_ 241 BrkPedTrvlAchvdV 120;
BA_REL_ "GenSigSuprvResp" BU_SG_REL_ EOCM_F_HS SG_ 241 BrkPedTrvlAchvdV 1;
BA_REL_ "GenSigTimeoutMsg" BU_SG_REL_ EOCM_F_HS SG_ 241 BrkPedTrvlAchvdV 241;
BA_REL_ "GenSigTimeoutTime" BU_SG_REL_ EOCM_F_HS SG_ 241 BrkPedTrvlAchvdV 120;
BA_REL_ "GenSigSuprvResp" BU_SG_REL_ EPB_HS SG_ 241 BrkPedTrvlAchvdV 1;
BA_REL_ "GenSigTimeoutMsg" BU_SG_REL_ EPB_HS SG_ 241 BrkPedTrvlAchvdV 241;
BA_REL_ "GenSigTimeoutTime" BU_SG_REL_ EPB_HS SG_ 241 BrkPedTrvlAchvdV 25;
BA_REL_ "GenSigSuprvResp" BU_SG_REL_ ACC_HS SG_ 241 BrkPedTrvlAchvdV 1;
BA_REL_ "GenSigTimeoutMsg" BU_SG_REL_ ACC_HS SG_ 241 BrkPedTrvlAchvdV 241;
BA_REL_ "GenSigTimeoutTime" BU_SG_REL_ ACC_HS SG_ 241 BrkPedTrvlAchvdV 25;
BA_REL_ "GenSigSuprvResp" BU_SG_REL_ RDCM_HS SG_ 241 BrkPedTrvlAchvdV 1;
BA_REL_ "GenSigTimeoutMsg" BU_SG_REL_ RDCM_HS SG_ 241 BrkPedTrvlAchvdV 241;
BA_REL_ "GenSigTimeoutTime" BU_SG_REL_ RDCM_HS SG_ 241 BrkPedTrvlAchvdV 250;
BA_REL_ "GenSigSuprvResp" BU_SG_REL_ FCM_HS SG_ 241 BrkPdlPosGrad 1;
BA_REL_ "GenSigTimeoutMsg" BU_SG_REL_ FCM_HS SG_ 241 BrkPdlPosGrad 241;
BA_REL_ "GenSigTimeoutTime" BU_SG_REL_ FCM_HS SG_ 241 BrkPdlPosGrad 250;
BA_REL_ "GenSigSuprvResp" BU_SG_REL_ CGM_HS SG_ 241 BrkPdlPosGrad 1;
BA_REL_ "GenSigTimeoutMsg" BU_SG_REL_ CGM_HS SG_ 241 BrkPdlPosGrad 241;
BA_REL_ "GenSigTimeoutTime" BU_SG_REL_ CGM_HS SG_ 241 BrkPdlPosGrad 250;
BA_REL_ "GenSigSuprvResp" BU_SG_REL_ VES_HS SG_ 241 BrkPdlPosGrad 1;
BA_REL_ "GenSigTimeoutMsg" BU_SG_REL_ VES_HS SG_ 241 BrkPdlPosGrad 241;
BA_REL_ "GenSigTimeoutTime" BU_SG_REL_ VES_HS SG_ 241 BrkPdlPosGrad 250;
BA_REL_ "GenSigSuprvResp" BU_SG_REL_ EPS_HS SG_ 241 BrkPdlPosGrad 1;
BA_REL_ "GenSigTimeoutMsg" BU_SG_REL_ EPS_HS SG_ 241 BrkPdlPosGrad 241;
BA_REL_ "GenSigTimeoutTime" BU_SG_REL_ EPS_HS SG_ 241 BrkPdlPosGrad 250;
BA_REL_ "GenSigSuprvResp" BU_SG_REL_ SADS_HS SG_ 241 BrkPdlPosGrad 1;
BA_REL_ "GenSigTimeoutMsg" BU_SG_REL_ SADS_HS SG_ 241 BrkPdlPosGrad 241;
BA_REL_ "GenSigTimeoutTime" BU_SG_REL_ SADS_HS SG_ 241 BrkPdlPosGrad 250;
BA_REL_ "GenSigSuprvResp" BU_SG_REL_ FCM_HS SG_ 241 BrkPdlPos 1;
BA_REL_ "GenSigTimeoutMsg" BU_SG_REL_ FCM_HS SG_ 241 BrkPdlPos 241;
BA_REL_ "GenSigTimeoutTime" BU_SG_REL_ FCM_HS SG_ 241 BrkPdlPos 250;
BA_REL_ "GenSigSuprvResp" BU_SG_REL_ ECM_HS SG_ 241 BrkPdlPos 1;
BA_REL_ "GenSigTimeoutMsg" BU_SG_REL_ ECM_HS SG_ 241 BrkPdlPos 241;
BA_REL_ "GenSigTimeoutTime" BU_SG_REL_ ECM_HS SG_ 241 BrkPdlPos 250;
BA_REL_ "GenSigSuprvResp" BU_SG_REL_ CGM_HS SG_ 241 BrkPdlPos 1;
BA_REL_ "GenSigTimeoutMsg" BU_SG_REL_ CGM_HS SG_ 241 BrkPdlPos 241;
BA_REL_ "GenSigTimeoutTime" BU_SG_REL_ CGM_HS SG_ 241 BrkPdlPos 250;
BA_REL_ "GenSigSuprvResp" BU_SG_REL_ TCCM_HS SG_ 241 BrkPdlPos 1;
BA_REL_ "GenSigTimeoutMsg" BU_SG_REL_ TCCM_HS SG_ 241 BrkPdlPos 241;
BA_REL_ "GenSigTimeoutTime" BU_SG_REL_ TCCM_HS SG_ 241 BrkPdlPos 250;
BA_REL_ "GenSigSuprvResp" BU_SG_REL_ VES_HS SG_ 241 BrkPdlPos 1;
BA_REL_ "GenSigTimeoutMsg" BU_SG_REL_ VES_HS SG_ 241 BrkPdlPos 241;
BA_REL_ "GenSigTimeoutTime" BU_SG_REL_ VES_HS SG_ 241 BrkPdlPos 250;
BA_REL_ "GenSigSuprvResp" BU_SG_REL_ EPS_HS SG_ 241 BrkPdlPos 1;
BA_REL_ "GenSigTimeoutMsg" BU_SG_REL_ EPS_HS SG_ 241 BrkPdlPos 241;
BA_REL_ "GenSigTimeoutTime" BU_SG_REL_ EPS_HS SG_ 241 BrkPdlPos 250;
BA_REL_ "GenSigSuprvResp" BU_SG_REL_ PTO_HS SG_ 241 BrkPedPosAlvRolngCnt 1;
BA_REL_ "GenSigTimeoutMsg" BU_SG_REL_ PTO_HS SG_ 241 BrkPedPosAlvRolngCnt 241;
BA_REL_ "GenSigTimeoutTime" BU_SG_REL_ PTO_HS SG_ 241 BrkPedPosAlvRolngCnt 250;
BA_REL_ "GenSigSuprvResp" BU_SG_REL_ VES_HS SG_ 241 BrkPedPosAlvRolngCnt 1;
BA_REL_ "GenSigTimeoutMsg" BU_SG_REL_ VES_HS SG_ 241 BrkPedPosAlvRolngCnt 241;
BA_REL_ "GenSigTimeoutTime" BU_SG_REL_ VES_HS SG_ 241 BrkPedPosAlvRolngCnt 250;
BA_REL_ "GenSigSuprvResp" BU_SG_REL_ EPS_HS SG_ 241 BrkPedPosAlvRolngCnt 1;
BA_REL_ "GenSigTimeoutMsg" BU_SG_REL_ EPS_HS SG_ 241 BrkPedPosAlvRolngCnt 241;
BA_REL_ "GenSigTimeoutTime" BU_SG_REL_ EPS_HS SG_ 241 BrkPedPosAlvRolngCnt 250;
BA_REL_ "GenSigSuprvResp" BU_SG_REL_ EOCM_F_HS SG_ 241 BrkPedPosAlvRolngCnt 1;
BA_REL_ "GenSigTimeoutMsg" BU_SG_REL_ EOCM_F_HS SG_ 241 BrkPedPosAlvRolngCnt 241;
BA_REL_ "GenSigTimeoutTime" BU_SG_REL_ EOCM_F_HS SG_ 241 BrkPedPosAlvRolngCnt 120;
BA_REL_ "GenSigSuprvResp" BU_SG_REL_ ICCM_OBD_HS SG_ 241 BrkPedPosAlvRolngCnt 1;
BA_REL_ "GenSigTimeoutMsg" BU_SG_REL_ ICCM_OBD_HS SG_ 241 BrkPedPosAlvRolngCnt 241;
BA_REL_ "GenSigTimeoutTime" BU_SG_REL_ ICCM_OBD_HS SG_ 241 BrkPedPosAlvRolngCnt 250;
BA_REL_ "GenSigSuprvResp" BU_SG_REL_ ICCM_HS SG_ 241 BrkPedPosAlvRolngCnt 1;
BA_REL_ "GenSigTimeoutMsg" BU_SG_REL_ ICCM_HS SG_ 241 BrkPedPosAlvRolngCnt 241;
BA_REL_ "GenSigTimeoutTime" BU_SG_REL_ ICCM_HS SG_ 241 BrkPedPosAlvRolngCnt 250;
BA_REL_ "GenSigSuprvResp" BU_SG_REL_ EBCM_OBD_HS SG_ 241 BrkPedPosAlvRolngCnt 1;
BA_REL_ "GenSigTimeoutMsg" BU_SG_REL_ EBCM_OBD_HS SG_ 241 BrkPedPosAlvRolngCnt 241;
BA_REL_ "GenSigTimeoutTime" BU_SG_REL_ EBCM_OBD_HS SG_ 241 BrkPedPosAlvRolngCnt 250;
BA_REL_ "GenSigSuprvResp" BU_SG_REL_ EBCM_HS SG_ 241 BrkPedPosAlvRolngCnt 1;
BA_REL_ "GenSigTimeoutMsg" BU_SG_REL_ EBCM_HS SG_ 241 BrkPedPosAlvRolngCnt 241;
BA_REL_ "GenSigTimeoutTime" BU_SG_REL_ EBCM_HS SG_ 241 BrkPedPosAlvRolngCnt 250;
BA_REL_ "GenSigSuprvResp" BU_SG_REL_ CGM_HS SG_ 241 BrkPdlModTrvl 1;
BA_REL_ "GenSigTimeoutMsg" BU_SG_REL_ CGM_HS SG_ 241 BrkPdlModTrvl 241;
BA_REL_ "GenSigTimeoutTime" BU_SG_REL_ CGM_HS SG_ 241 BrkPdlModTrvl 250;
BA_REL_ "GenSigSuprvResp" BU_SG_REL_ EBCM_OBD_HS SG_ 241 BrkPdlModTrvl 1;
BA_REL_ "GenSigTimeoutMsg" BU_SG_REL_ EBCM_OBD_HS SG_ 241 BrkPdlModTrvl 241;
BA_REL_ "GenSigTimeoutTime" BU_SG_REL_ EBCM_OBD_HS SG_ 241 BrkPdlModTrvl 250;
BA_REL_ "GenSigSuprvResp" BU_SG_REL_ EBCM_HS SG_ 241 BrkPdlModTrvl 1;
BA_REL_ "GenSigTimeoutMsg" BU_SG_REL_ EBCM_HS SG_ 241 BrkPdlModTrvl 241;
BA_REL_ "GenSigTimeoutTime" BU_SG_REL_ EBCM_HS SG_ 241 BrkPdlModTrvl 250;
BA_REL_ "GenSigSuprvResp" BU_SG_REL_ EOCM_F_HS SG_ 241 BrkPdlModTrvl 1;
BA_REL_ "GenSigTimeoutMsg" BU_SG_REL_ EOCM_F_HS SG_ 241 BrkPdlModTrvl 241;
BA_REL_ "GenSigTimeoutTime" BU_SG_REL_ EOCM_F_HS SG_ 241 BrkPdlModTrvl 120;
BA_REL_ "GenSigSuprvResp" BU_SG_REL_ EOCM_F_HS SG_ 241 BrkPdlModTrvl 1;
BA_REL_ "GenSigTimeoutMsg" BU_SG_REL_ EOCM_F_HS SG_ 241 BrkPdlModTrvl 241;
BA_REL_ "GenSigTimeoutTime" BU_SG_REL_ EOCM_F_HS SG_ 241 BrkPdlModTrvl 120;
BA_REL_ "GenSigSuprvResp" BU_SG_REL_ VES_HS SG_ 241 BrkPdlModTrvl 1;
BA_REL_ "GenSigTimeoutMsg" BU_SG_REL_ VES_HS SG_ 241 BrkPdlModTrvl 241;
BA_REL_ "GenSigTimeoutTime" BU_SG_REL_ VES_HS SG_ 241 BrkPdlModTrvl 250;
BA_REL_ "GenSigSuprvResp" BU_SG_REL_ EPS_HS SG_ 241 BrkPdlModTrvl 1;
BA_REL_ "GenSigTimeoutMsg" BU_SG_REL_ EPS_HS SG_ 241 BrkPdlModTrvl 241;
BA_REL_ "GenSigTimeoutTime" BU_SG_REL_ EPS_HS SG_ 241 BrkPdlModTrvl 250;
BA_REL_ "GenSigVBitResp" BU_SG_REL_ ECM_HS SG_ 241 BrkPdlModTrvl 1;
BA_REL_ "GenSigSuprvResp" BU_SG_REL_ CGM_HS SG_ 241 BrkPdlInTrvPrt 1;
BA_REL_ "GenSigTimeoutMsg" BU_SG_REL_ CGM_HS SG_ 241 BrkPdlInTrvPrt 241;
BA_REL_ "GenSigTimeoutTime" BU_SG_REL_ CGM_HS SG_ 241 BrkPdlInTrvPrt 250;
BA_REL_ "GenSigSuprvResp" BU_SG_REL_ PTO_HS SG_ 241 BrkPdlInTrvPrt 1;
BA_REL_ "GenSigTimeoutMsg" BU_SG_REL_ PTO_HS SG_ 241 BrkPdlInTrvPrt 241;
BA_REL_ "GenSigTimeoutTime" BU_SG_REL_ PTO_HS SG_ 241 BrkPdlInTrvPrt 250;
BA_REL_ "GenSigSuprvResp" BU_SG_REL_ VES_HS SG_ 241 BrkPdlInTrvPrt 1;
BA_REL_ "GenSigTimeoutMsg" BU_SG_REL_ VES_HS SG_ 241 BrkPdlInTrvPrt 241;
BA_REL_ "GenSigTimeoutTime" BU_SG_REL_ VES_HS SG_ 241 BrkPdlInTrvPrt 250;
BA_REL_ "GenSigSuprvResp" BU_SG_REL_ EPS_HS SG_ 241 BrkPdlInTrvPrt 1;
BA_REL_ "GenSigTimeoutMsg" BU_SG_REL_ EPS_HS SG_ 241 BrkPdlInTrvPrt 241;
BA_REL_ "GenSigTimeoutTime" BU_SG_REL_ EPS_HS SG_ 241 BrkPdlInTrvPrt 250;
VAL_ 497 ElvtdIdlCstStReq 0 "No Action" 1 "Off" 2 "On" ;
VAL_ 497 FuelFltLfRstRqd 1 "true" 0 "false" ;
VAL_ 497 ACCompSysVDA 1 "VirtualDeviceAvailable" 0 "VirtualDeviceUnavailable" ;
VAL_ 497 BkupPwrModeMstrVDA 1 "VirtualDeviceAvailable" 0 "VirtualDeviceUnavailable" ;
VAL_ 497 PrkBrkVDA 1 "VirtualDeviceAvailable" 0 "VirtualDeviceUnavailable" ;
VAL_ 497 PrkBrkVDM 1 "Use Data" 0 "Don't Use Data" ;
VAL_ 497 BkupPwrModeMstrVDM 1 "Use Data" 0 "Don't Use Data" ;
VAL_ 497 ACCompSysVDM 1 "Use Data" 0 "Don't Use Data" ;
VAL_ 497 AirbgVDA 1 "VirtualDeviceAvailable" 0 "VirtualDeviceUnavailable" ;
VAL_ 497 SysBkupPwrMdEn 1 "true" 0 "false" ;
VAL_ 497 SysBkUpPwrMd 3 "Crank Request" 2 "Run" 1 "Accessory" 0 "Off" ;
VAL_ 497 SysPwrMd 3 "Crank Request" 2 "Run" 1 "Accessory" 0 "Off" ;
VAL_ 497 TrStLgMdAtv 1 "true" 0 "false" ;
VAL_ 497 DispMeasSys 1 "English" 0 "Metric" ;
VAL_ 497 ACCmpsrFldOn 1 "true" 0 "false" ;
VAL_ 497 ACCompModReq 3 "No Action" 2 "Engage" 1 "Disengage" 0 "Disengage Immediately" ;
VAL_ 497 ACCompNormLdV 1 "Invalid" 0 "Valid" ;
VAL_ 497 PTORSMstrEngShtReq 1 "true" 0 "false" ;
VAL_ 497 EngOilLfRstRq 1 "true" 0 "false" ;
VAL_ 497 SIRDpl 1 "true" 0 "false" ;
VAL_ 497 PTORmStMsEngStRq 1 "PTO Remote Start Requested" 0 "PTO Remote Start Not Requested" ;
VAL_ 497 RmVehStrRq 1 "Remote Start Requested" 0 "Remote Start Not Requested" ;
VAL_ 497 ThrtlPrgrsnReq 2 "Map C" 1 "Map B" 0 "Map A" ;
VAL_ 497 PrkBrkSwAtv 1 "true" 0 "false" ;
VAL_ 497 PMMAccTrmSt 1 "Active" 0 "Inactive" ;
VAL_ 497 PMMRunCrkTrmSt 1 "Active" 0 "Inactive" ;
VAL_ 497 ImmblzrPreRelPswdStat 1 "Information Valid" 0 "No Information" ;
VAL_ 840 WhlRotDrctnlStLftDrvn 0 "Unknown" 1 "Forward" 2 "Reverse" 3 "Not Supported" 4 "Failed" 5 "Reserved 1" 6 "Reserved 2" 7 "Reserved 3" ;
VAL_ 840 WhlRotDrctnlStRtDrvn 0 "Unknown" 1 "Forward" 2 "Reverse" 3 "Not Supported" 4 "Failed" 5 "Reserved 1" 6 "Reserved 2" 7 "Reserved 3" ;
VAL_ 840 WhlGrndVlctyRtDrvnV 1 "Invalid" 0 "Valid" ;
VAL_ 840 WhlGrndVlctyLftDrvnV 1 "Invalid" 0 "Valid" ;
VAL_ 193 WRSLDWhlDistVal 1 "Invalid" 0 "Valid" ;
VAL_ 193 WRSLDWhlRotStatRst 1 "true" 0 "false" ;
VAL_ 193 WRSRDWhlRotStatRst 1 "true" 0 "false" ;
VAL_ 193 WRSRDWhlDistVal 1 "Invalid" 0 "Valid" ;
VAL_ 481 CrsSecSwStat 15 "Unused and Reserved 7" 14 "Unused and Reserved 6" 13 "Unused and Reserved 5" 12 "Unused and Reserved 4" 11 "Unused and Reserved 3" 10 "Unused and Reserved 2" 9 "Between Ranges" 8 "Short to Power" 7 "Open/Short to Ground" 6 "Speed Decrease High" 5 "Speed Increase High" 4 "Gap Up" 3 "Gap Down" 2 "Unused and Reserved 1" 1 "No Activation" 0 "Indeterminate" ;
VAL_ 481 DrvSelMdSw3Sta 1 "Active" 0 "Inactive" ;
VAL_ 481 DrvSelMdSw2Sta 1 "Active" 0 "Inactive" ;
VAL_ 481 AuxHtrRq 1 "On" 0 "Off" ;
VAL_ 481 AuxHtrAtv 1 "true" 0 "false" ;
VAL_ 481 DrvSelMdSw1Sta 1 "Active" 0 "Inactive" ;
VAL_ 481 FuelMdSwActV 1 "Invalid" 0 "Valid" ;
VAL_ 481 FuelMdSwAct 1 "True" 0 "False" ;
VAL_ 481 CrsSpdLmtrSwStat 9 "Between Ranges" 8 "Short to Power" 7 "Open/Short to Ground" 6 "Cancel" 5 "Cruise On/Off" 4 "SL/SW On/Off/GAP" 3 "Set" 2 "Resume" 1 "No Activation" 0 "Indeterminate" ;
VAL_ 481 AdptCrsGapSwAct 2 "Increase Gap" 1 "Decrease Gap" 0 "No Activation" ;
VAL_ 481 CrsCntrlSwStCanSwAct 1 "true" 0 "false" ;
VAL_ 481 CrsCntrlSwStSwDataIntgty 3 "Illegal Range" 2 "Failure Detected" 1 "Data Invalid" 0 "Data Valid" ;
VAL_ 481 CrsCntrlSwStSpdInSwAct 1 "true" 0 "false" ;
VAL_ 481 CrsCntrlSwStSpDcSwAct 1 "true" 0 "false" ;
VAL_ 481 CrsCntrlSwStSetSwAct 1 "true" 0 "false" ;
VAL_ 481 CrsCntrlSwStResSwAct 1 "true" 0 "false" ;
VAL_ 481 CrsCntrlSwStOnSwAct 1 "true" 0 "false" ;
VAL_ 481 CrsCntCncRq 1 "Cancel" 0 "Do Not Cancel" ;
VAL_ 455 CSETRER_TqIntvnTyp 2 "Increase Torque" 1 "Reduce Torque" 0 "No Intervention" ;
VAL_ 761 BrkSysHRBkCtrlAvail 1 "true" 0 "false" ;
VAL_ 761 BrkSysHRBkCtrlStat 0 "Inactive" 1 "Control Target Vehicle Speed" 2 "Unused and Reserved 1" 3 "Unused and Reserved 2" ;
VAL_ 761 BrkSysHSAAval 1 "true" 0 "false" ;
VAL_ 761 BrkSysHSAStat 0 "Inactive" 1 "Brake Pressure Hold" 2 "Normal Pressure Decay" 3 "Drive-off Pressure Decay" ;
VAL_ 761 HillDscntCtrlStat 0 "Not Enabled" 1 "Enabled" 2 "Active" 3 "Unused" ;
VAL_ 761 ABFI_CollPrepSysInhbt 1 "true" 0 "false" ;
VAL_ 761 ABFI_RrVirtlBmprInh 1 "true" 0 "false" ;
VAL_ 761 BrkPdlDrvApplPresV 1 "Invalid" 0 "Valid" ;
VAL_ 761 AutoBrkPTReqStat 0 "Inactive" 1 "Active" 2 "Failed" 3 "Serial Communication Failure" 4 "Unused and Reserved 1" 5 "Unused and Reserved 2" 6 "Unused and Reserved 3" 7 "Unused and Reserved 4" ;
VAL_ 761 WhlSpdSnsgDTCStat 4 "Diagnostic Failed" 3 "Diagnostic Passed" 2 "No Status to Report" 1 "Critically Disabled" 0 "Not Supported" ;
VAL_ 761 SprTireSt 2 "Spare Detected" 1 "No Spare Detected" 0 "Undetermined" ;
VAL_ 489 EnhDrvMdSwChUseRq 1 "true" 0 "false" ;
VAL_ 489 IMUDataMsk 1 "true" 0 "false" ;
VAL_ 489 DrvIndpntBrkAppAct 1 "true" 0 "false" ;
VAL_ 489 WhlSlpSt 3 "Slip Detection Fault" 2 "Positive Slip Detected" 1 "Negative Slip Detected" 0 "No Slip Detected" ;
VAL_ 489 BSTGRReqdGear 8 "Eighth Gear" 7 "Seventh Gear" 6 "Sixth Gear" 5 "Fifth Gear" 4 "Fourth Gear" 3 "Third Gear" 2 "Second Gear" 1 "First Gear" 0 "No Action" ;
VAL_ 489 BSTGRReqType 3 "Hold Gear" 2 "Min Gear Request" 1 "Max Gear Request" 0 "No Action" ;
VAL_ 489 VSELatAccV 1 "Invalid" 0 "Valid" ;
VAL_ 489 VSEAct 1 "true" 0 "false" ;
VAL_ 489 VhDynCntlSysSt 7 "Driver Disabled" 6 "Enhanced Operation" 5 "Calibrating" 4 "Warming Up" 3 "Permanently Failed" 2 "Temporarily Inhibited" 1 "Reduced Function" 0 "Normal Operation" ;
VAL_ 489 VehDynYawRateV 1 "Invalid" 0 "Valid" ;
VAL_ 489 TrnsBrkSysCltchRelRqd 1 "true" 0 "false" ;
VAL_ 489 TracCntrlSysDrIntnt 1 "Enabled" 0 "Disabled" ;
VAL_ 489 VehDynOvrUndrStrV 1 "Invalid" 0 "Valid" ;
VAL_ 489 TCSysEnbld 1 "true" 0 "false" ;
VAL_ 489 TCSysAtv 1 "true" 0 "false" ;
VAL_ 489 BrkPdlDrvAppPrsDetcdV 1 "Invalid" 0 "Valid" ;
VAL_ 489 BrkPdlDrvAppPrsDetcd 1 "true" 0 "false" ;
VAL_ 489 ACCBrkngAct 1 "true" 0 "false" ;
VAL_ 489 ABSFld 1 "true" 0 "false" ;
VAL_ 489 ABSAtv 1 "true" 0 "false" ;
VAL_ 381 HillDesCtrlRedVehSpIO 1 "true" 0 "false" ;
VAL_ 381 EBDFailed 1 "true" 0 "false" ;
VAL_ 381 StWhAnVDA 1 "VirtualDeviceAvailable" 0 "VirtualDeviceUnavailable" ;
VAL_ 381 TirePrsLowIO 1 "true" 0 "false" ;
VAL_ 381 VaccBoostFailure 1 "true" 0 "false" ;
VAL_ 381 VSESysPrs 1 "true" 0 "false" ;
VAL_ 381 HalfSysFail 1 "true" 0 "false" ;
VAL_ 381 ActVehAccelV 1 "Invalid" 0 "Valid" ;
VAL_ 381 BksOvht 1 "true" 0 "false" ;
VAL_ 381 TCSysPr 1 "true" 0 "false" ;
VAL_ 381 ABSPr 1 "true" 0 "false" ;
VAL_ 381 TreInfMonSysRstPrfmd 1 "true" 0 "false" ;
VAL_ 381 ABSIO 1 "true" 0 "false" ;
VAL_ 381 BrkPadWrnIO 1 "true" 0 "false" ;
VAL_ 381 VehStabEnhmntMd 2 "Competitive" 1 "Normal" 0 "Off" ;
VAL_ 381 VehStabEnhmntStat 4 "Not Ready" 3 "Warming Up" 2 "Fault" 1 "Active" 0 "Inactive" ;
VAL_ 381 TCSysOpMd 2 "Off Road" 1 "Normal" 0 "Off" ;
VAL_ 381 TCSysOpStat 2 "Fault" 1 "Active" 0 "Inactive" ;
VAL_ 381 BrkSysRedBrkTlltlReq 1 "true" 0 "false" ;
VAL_ 381 BrkSysBrkLtsReqd 1 "true" 0 "false" ;
VAL_ 241 NotEventStat 2 "Pretensioner Deployment Event" 1 "Near Deployment Event" 0 "No Event" 3 "Airbag Deployment Event" ;
VAL_ 241 BrkAppSnsrHmPosLrnd 1 "true" 0 "false" ;
VAL_ 241 BrkPedTrvlAchvd 1 "true" 0 "false" ;
VAL_ 241 BrkPedTrvlAchvdV 1 "Invalid" 0 "Valid" ;
VAL_ 241 BrkPdlModTrvlV 1 "Invalid" 0 "Valid" ;
VAL_ 241 BrkPdlModTrvl 1 "true" 0 "false" ;
SIG_GROUP_ 193 WhlRotatStatLftDrvn 1 : WRSLDWhlDisTpRC WRSLDSeqNum WRSLDWhlDistVal WRSLDWhlRotStatRst WRSLDWhlDistTmstm WRSLDWhlDistPlsCntr;
SIG_GROUP_ 193 WhlRotatStatRtDrvn 1 : WRSRDWhlDisTpRC WRSRDSeqNum WRSRDWhlRotStatRst WRSRDWhlDistVal WRSRDWhlDistTmstm WRSRDWhlDistPlsCntr;
SIG_GROUP_ 481 CrsCntrlSwStat 1 : CrsCntrlSwStCanSwAct CrsCntrlSwStSwDataIntgty CrsCntrlSwStSpdInSwAct CrsCntrlSwStSpDcSwAct CrsCntrlSwStSetSwAct CrsCntrlSwStResSwAct CrsCntrlSwStOnSwAct;
SIG_GROUP_ 455 ChsSysEngTorqReqER 1 : CSETRER_TorqReqVal CSETRER_TqIntvnTyp;
SIG_GROUP_ 761 AutoBrkFeatInhbt 1 : ABFI_CollPrepSysInhbt ABFI_RrVirtlBmprInh;
SIG_GROUP_ 761 WhlSpdSnsLgsDiagStat 1 : WhlSpdSnsgDTCIndex WhlSpdSnsgDTCStat;
SIG_GROUP_ 489 BrkSysTransGearReq 1 : BSTGRReqdGear BSTGRReqType;
SIG_GROUP_ 241 BrkPedInitTrvlAchvdStat 1 : BrkPedTrvlAchvd BrkPedTrvlAchvdV;
